VERSION ""

NS_ :

BS_:

BU_: WCM4 WCM3 WCM2 WCM VPM VLM VKM VICM VECM VDM VCU_RTOS_ETH VCU_ENTRY_ETH VCU_AGVM_ETH VCU UVM UPM TIM TEST_TOOL_1 TCP_ETH TCP TCM TCCM SRR_SRR_ETH SRR_SRR SRR_SLR_ETH SRR_SLR SRR_RR SRR_RF_ETH SRR_RF SRR_LR_CR SRR_LF_ETH SRR_LF SIB SDM SCL SBZA_R SBZA_L SBM SAM_RR SAM_RF SAM_LR SAM_LF SAM_BH SADS RadioLow_ETH RadioLow RSI_RTOS_ETH RSI RDCM PTM PLCM PFCM PDR_ETH PDR PCM PA ODS2 ODS NVM MTCM_R MTCM_L MSM_RR MSM_P MSM_LR MSM_D MSB2 MSB1 MRCM_R MRCM_L MFC LRR_RR_ETH LRR_LR_ETH LRR_CF_ETH LRR LRL_CF_ETH LIB_48V LIB1 IPC_INT IPC_GP IPC ICS_Info ICCM HVAC_FP_R HVAC_FP_F HUD_CAN HDLM FPI_RTOS_ETH FPI FOPM FCM_LC FCM EPSb EPS_1 EPSRAb EPSRAa EPS EOCM_HC_Superset EOCM_HCP2 EOCM ELM ECP_X1 ECP_S2 ECP_S ECP_MC ECP_H3 ECP_H2 ECP_H1 ECP_E ECM EBCM DMS DEFC DCM CSM_ETH CSM_AV CSM CGM_OTA_ETH CGM BSM_MH BSM_HEV BSM BCM ARS ARB APA AOS AMP ALC AHS AHL_AFL ADIMb ADIMa ACP2_MCU

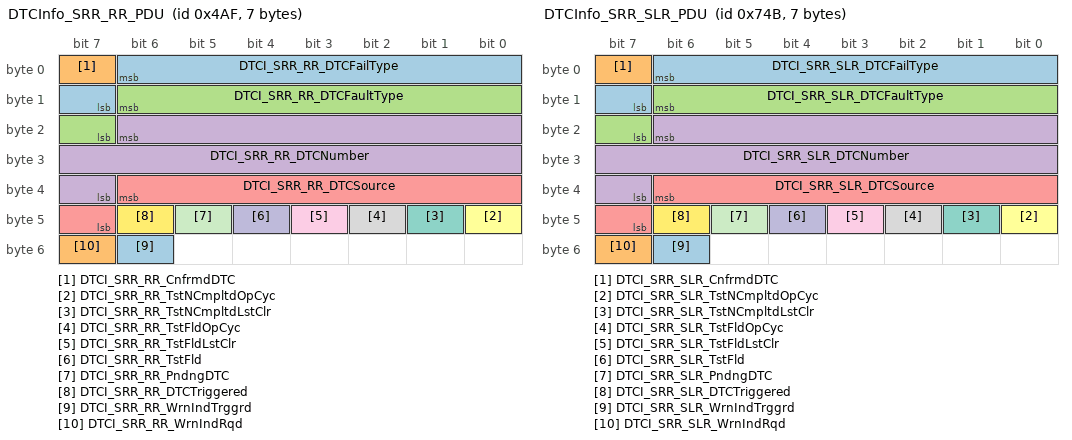
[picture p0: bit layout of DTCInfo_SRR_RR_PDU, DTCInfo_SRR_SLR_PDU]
BO_ 1199 DTCInfo_SRR_RR_PDU: 7 CGM
 SG_ DTCI_SRR_RR_DTCFailType : 6|8@0+ (1,0) [0|255] "" TCP,CSM
 SG_ DTCI_SRR_RR_CnfrmdDTC : 7|1@0+ (1,0) [0|1] "" TCP,CSM
 SG_ DTCI_SRR_RR_DTCFaultType : 14|8@0+ (1,0) [0|3] "" TCP,CSM
 SG_ DTCI_SRR_RR_DTCNumber : 22|16@0+ (1,0) [0|65535] "" TCP,CSM
 SG_ DTCI_SRR_RR_DTCSource : 38|8@0+ (1,0) [0|255] "" TCP,CSM
 SG_ DTCI_SRR_RR_TstNCmpltdOpCyc : 40|1@0+ (1,0) [0|1] "" TCP,CSM
 SG_ DTCI_SRR_RR_TstNCmpltdLstClr : 41|1@0+ (1,0) [0|1] "" TCP,CSM
 SG_ DTCI_SRR_RR_TstFldOpCyc : 42|1@0+ (1,0) [0|1] "" TCP,CSM
 SG_ DTCI_SRR_RR_TstFldLstClr : 43|1@0+ (1,0) [0|1] "" TCP,CSM
 SG_ DTCI_SRR_RR_TstFld : 44|1@0+ (1,0) [0|1] "" TCP,CSM
 SG_ DTCI_SRR_RR_PndngDTC : 45|1@0+ (1,0) [0|1] "" TCP,CSM
 SG_ DTCI_SRR_RR_DTCTriggered : 46|1@0+ (1,0) [0|1] "" TCP,CSM
 SG_ DTCI_SRR_RR_WrnIndTrggrd : 54|1@0+ (1,0) [0|1] "" TCP,CSM
 SG_ DTCI_SRR_RR_WrnIndRqd : 55|1@0+ (1,0) [0|1] "" TCP,CSM

BO_ 1867 DTCInfo_SRR_SLR_PDU: 7 CGM
 SG_ DTCI_SRR_SLR_DTCFailType : 6|8@0+ (1,0) [0|255] "" TCP,CSM
 SG_ DTCI_SRR_SLR_CnfrmdDTC : 7|1@0+ (1,0) [0|1] "" TCP,CSM
 SG_ DTCI_SRR_SLR_DTCFaultType : 14|8@0+ (1,0) [0|3] "" TCP,CSM
 SG_ DTCI_SRR_SLR_DTCNumber : 22|16@0+ (1,0) [0|65535] "" TCP,CSM
 SG_ DTCI_SRR_SLR_DTCSource : 38|8@0+ (1,0) [0|255] "" TCP,CSM
 SG_ DTCI_SRR_SLR_TstNCmpltdOpCyc : 40|1@0+ (1,0) [0|1] "" TCP,CSM
 SG_ DTCI_SRR_SLR_TstNCmpltdLstClr : 41|1@0+ (1,0) [0|1] "" TCP,CSM
 SG_ DTCI_SRR_SLR_TstFldOpCyc : 42|1@0+ (1,0) [0|1] "" TCP,CSM
 SG_ DTCI_SRR_SLR_TstFldLstClr : 43|1@0+ (1,0) [0|1] "" TCP,CSM
 SG_ DTCI_SRR_SLR_TstFld : 44|1@0+ (1,0) [0|1] "" TCP,CSM
 SG_ DTCI_SRR_SLR_PndngDTC : 45|1@0+ (1,0) [0|1] "" TCP,CSM
 SG_ DTCI_SRR_SLR_DTCTriggered : 46|1@0+ (1,0) [0|1] "" TCP,CSM
 SG_ DTCI_SRR_SLR_WrnIndTrggrd : 54|1@0+ (1,0) [0|1] "" TCP,CSM
 SG_ DTCI_SRR_SLR_WrnIndRqd : 55|1@0+ (1,0) [0|1] "" TCP,CSM

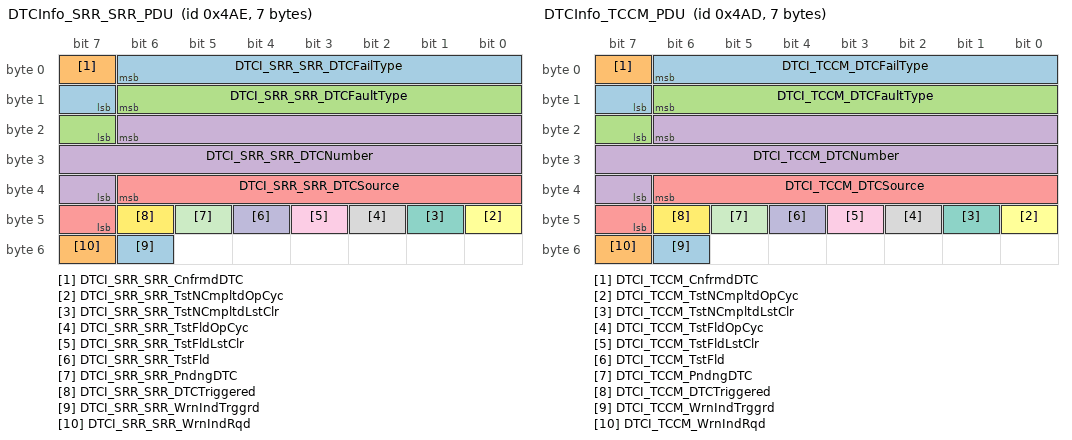
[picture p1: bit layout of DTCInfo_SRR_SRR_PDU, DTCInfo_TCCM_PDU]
BO_ 1198 DTCInfo_SRR_SRR_PDU: 7 CGM
 SG_ DTCI_SRR_SRR_DTCFailType : 6|8@0+ (1,0) [0|255] "" TCP,CSM
 SG_ DTCI_SRR_SRR_CnfrmdDTC : 7|1@0+ (1,0) [0|1] "" TCP,CSM
 SG_ DTCI_SRR_SRR_DTCFaultType : 14|8@0+ (1,0) [0|3] "" TCP,CSM
 SG_ DTCI_SRR_SRR_DTCNumber : 22|16@0+ (1,0) [0|65535] "" TCP,CSM
 SG_ DTCI_SRR_SRR_DTCSource : 38|8@0+ (1,0) [0|255] "" TCP,CSM
 SG_ DTCI_SRR_SRR_TstNCmpltdOpCyc : 40|1@0+ (1,0) [0|1] "" TCP,CSM
 SG_ DTCI_SRR_SRR_TstNCmpltdLstClr : 41|1@0+ (1,0) [0|1] "" TCP,CSM
 SG_ DTCI_SRR_SRR_TstFldOpCyc : 42|1@0+ (1,0) [0|1] "" TCP,CSM
 SG_ DTCI_SRR_SRR_TstFldLstClr : 43|1@0+ (1,0) [0|1] "" TCP,CSM
 SG_ DTCI_SRR_SRR_TstFld : 44|1@0+ (1,0) [0|1] "" TCP,CSM
 SG_ DTCI_SRR_SRR_PndngDTC : 45|1@0+ (1,0) [0|1] "" TCP,CSM
 SG_ DTCI_SRR_SRR_DTCTriggered : 46|1@0+ (1,0) [0|1] "" TCP,CSM
 SG_ DTCI_SRR_SRR_WrnIndTrggrd : 54|1@0+ (1,0) [0|1] "" TCP,CSM
 SG_ DTCI_SRR_SRR_WrnIndRqd : 55|1@0+ (1,0) [0|1] "" TCP,CSM

BO_ 1197 DTCInfo_TCCM_PDU: 7 CGM
 SG_ DTCI_TCCM_DTCFailType : 6|8@0+ (1,0) [0|255] "" TCP,CSM
 SG_ DTCI_TCCM_CnfrmdDTC : 7|1@0+ (1,0) [0|1] "" TCP,CSM
 SG_ DTCI_TCCM_DTCFaultType : 14|8@0+ (1,0) [0|3] "" TCP,CSM
 SG_ DTCI_TCCM_DTCNumber : 22|16@0+ (1,0) [0|65535] "" TCP,CSM
 SG_ DTCI_TCCM_DTCSource : 38|8@0+ (1,0) [0|255] "" TCP,CSM
 SG_ DTCI_TCCM_TstNCmpltdOpCyc : 40|1@0+ (1,0) [0|1] "" TCP,CSM
 SG_ DTCI_TCCM_TstNCmpltdLstClr : 41|1@0+ (1,0) [0|1] "" TCP,CSM
 SG_ DTCI_TCCM_TstFldOpCyc : 42|1@0+ (1,0) [0|1] "" TCP,CSM
 SG_ DTCI_TCCM_TstFldLstClr : 43|1@0+ (1,0) [0|1] "" TCP,CSM
 SG_ DTCI_TCCM_TstFld : 44|1@0+ (1,0) [0|1] "" TCP,CSM
 SG_ DTCI_TCCM_PndngDTC : 45|1@0+ (1,0) [0|1] "" TCP,CSM
 SG_ DTCI_TCCM_DTCTriggered : 46|1@0+ (1,0) [0|1] "" TCP,CSM
 SG_ DTCI_TCCM_WrnIndTrggrd : 54|1@0+ (1,0) [0|1] "" TCP,CSM
 SG_ DTCI_TCCM_WrnIndRqd : 55|1@0+ (1,0) [0|1] "" TCP,CSM

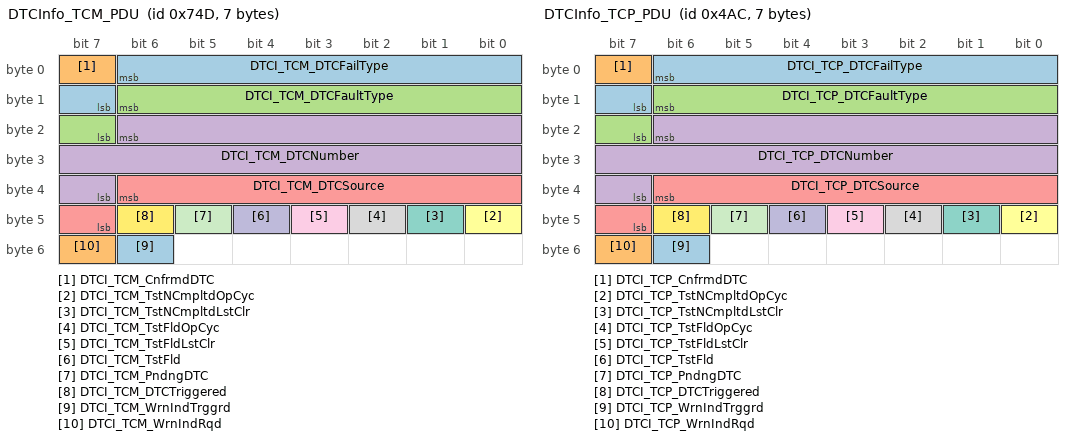
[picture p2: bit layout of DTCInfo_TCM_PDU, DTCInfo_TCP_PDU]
BO_ 1869 DTCInfo_TCM_PDU: 7 CGM
 SG_ DTCI_TCM_DTCFailType : 6|8@0+ (1,0) [0|255] "" TCP,CSM
 SG_ DTCI_TCM_CnfrmdDTC : 7|1@0+ (1,0) [0|1] "" TCP,CSM
 SG_ DTCI_TCM_DTCFaultType : 14|8@0+ (1,0) [0|3] "" TCP,CSM
 SG_ DTCI_TCM_DTCNumber : 22|16@0+ (1,0) [0|65535] "" TCP,CSM
 SG_ DTCI_TCM_DTCSource : 38|8@0+ (1,0) [0|255] "" TCP,CSM
 SG_ DTCI_TCM_TstNCmpltdOpCyc : 40|1@0+ (1,0) [0|1] "" TCP,CSM
 SG_ DTCI_TCM_TstNCmpltdLstClr : 41|1@0+ (1,0) [0|1] "" TCP,CSM
 SG_ DTCI_TCM_TstFldOpCyc : 42|1@0+ (1,0) [0|1] "" TCP,CSM
 SG_ DTCI_TCM_TstFldLstClr : 43|1@0+ (1,0) [0|1] "" TCP,CSM
 SG_ DTCI_TCM_TstFld : 44|1@0+ (1,0) [0|1] "" TCP,CSM
 SG_ DTCI_TCM_PndngDTC : 45|1@0+ (1,0) [0|1] "" TCP,CSM
 SG_ DTCI_TCM_DTCTriggered : 46|1@0+ (1,0) [0|1] "" TCP,CSM
 SG_ DTCI_TCM_WrnIndTrggrd : 54|1@0+ (1,0) [0|1] "" TCP,CSM
 SG_ DTCI_TCM_WrnIndRqd : 55|1@0+ (1,0) [0|1] "" TCP,CSM

BO_ 1196 DTCInfo_TCP_PDU: 7 TCP
 SG_ DTCI_TCP_DTCFailType : 6|8@0+ (1,0) [0|255] "" CGM,TCP,CSM
 SG_ DTCI_TCP_CnfrmdDTC : 7|1@0+ (1,0) [0|1] "" CGM,TCP,CSM
 SG_ DTCI_TCP_DTCFaultType : 14|8@0+ (1,0) [0|3] "" CGM,TCP,CSM
 SG_ DTCI_TCP_DTCNumber : 22|16@0+ (1,0) [0|65535] "" CGM,TCP,CSM
 SG_ DTCI_TCP_DTCSource : 38|8@0+ (1,0) [0|255] "" CGM,TCP,CSM
 SG_ DTCI_TCP_TstNCmpltdOpCyc : 40|1@0+ (1,0) [0|1] "" CGM,TCP,CSM
 SG_ DTCI_TCP_TstNCmpltdLstClr : 41|1@0+ (1,0) [0|1] "" CGM,TCP,CSM
 SG_ DTCI_TCP_TstFldOpCyc : 42|1@0+ (1,0) [0|1] "" CGM,TCP,CSM
 SG_ DTCI_TCP_TstFldLstClr : 43|1@0+ (1,0) [0|1] "" CGM,TCP,CSM
 SG_ DTCI_TCP_TstFld : 44|1@0+ (1,0) [0|1] "" CGM,TCP,CSM
 SG_ DTCI_TCP_PndngDTC : 45|1@0+ (1,0) [0|1] "" CGM,TCP,CSM
 SG_ DTCI_TCP_DTCTriggered : 46|1@0+ (1,0) [0|1] "" CGM,TCP,CSM
 SG_ DTCI_TCP_WrnIndTrggrd : 54|1@0+ (1,0) [0|1] "" CGM,TCP,CSM
 SG_ DTCI_TCP_WrnIndRqd : 55|1@0+ (1,0) [0|1] "" CGM,TCP,CSM

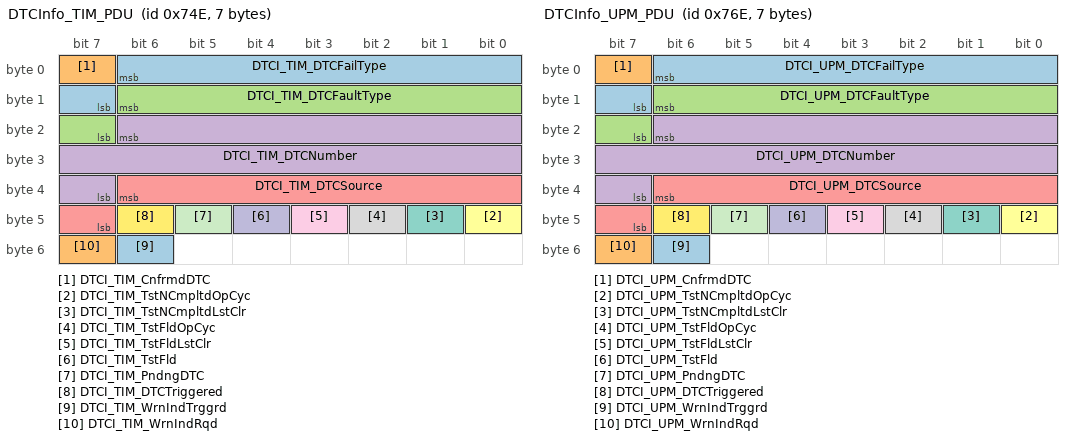
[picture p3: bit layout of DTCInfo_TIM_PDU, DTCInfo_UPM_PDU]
BO_ 1870 DTCInfo_TIM_PDU: 7 CGM
 SG_ DTCI_TIM_DTCFailType : 6|8@0+ (1,0) [0|255] "" TCP,CSM
 SG_ DTCI_TIM_CnfrmdDTC : 7|1@0+ (1,0) [0|1] "" TCP,CSM
 SG_ DTCI_TIM_DTCFaultType : 14|8@0+ (1,0) [0|3] "" TCP,CSM
 SG_ DTCI_TIM_DTCNumber : 22|16@0+ (1,0) [0|65535] "" TCP,CSM
 SG_ DTCI_TIM_DTCSource : 38|8@0+ (1,0) [0|255] "" TCP,CSM
 SG_ DTCI_TIM_TstNCmpltdOpCyc : 40|1@0+ (1,0) [0|1] "" TCP,CSM
 SG_ DTCI_TIM_TstNCmpltdLstClr : 41|1@0+ (1,0) [0|1] "" TCP,CSM
 SG_ DTCI_TIM_TstFldOpCyc : 42|1@0+ (1,0) [0|1] "" TCP,CSM
 SG_ DTCI_TIM_TstFldLstClr : 43|1@0+ (1,0) [0|1] "" TCP,CSM
 SG_ DTCI_TIM_TstFld : 44|1@0+ (1,0) [0|1] "" TCP,CSM
 SG_ DTCI_TIM_PndngDTC : 45|1@0+ (1,0) [0|1] "" TCP,CSM
 SG_ DTCI_TIM_DTCTriggered : 46|1@0+ (1,0) [0|1] "" TCP,CSM
 SG_ DTCI_TIM_WrnIndTrggrd : 54|1@0+ (1,0) [0|1] "" TCP,CSM
 SG_ DTCI_TIM_WrnIndRqd : 55|1@0+ (1,0) [0|1] "" TCP,CSM

BO_ 1902 DTCInfo_UPM_PDU: 7 CGM
 SG_ DTCI_UPM_DTCFailType : 6|8@0+ (1,0) [0|255] "" TCP
 SG_ DTCI_UPM_CnfrmdDTC : 7|1@0+ (1,0) [0|1] "" TCP
 SG_ DTCI_UPM_DTCFaultType : 14|8@0+ (1,0) [0|3] "" TCP
 SG_ DTCI_UPM_DTCNumber : 22|16@0+ (1,0) [0|65535] "" TCP
 SG_ DTCI_UPM_DTCSource : 38|8@0+ (1,0) [0|255] "" TCP
 SG_ DTCI_UPM_TstNCmpltdOpCyc : 40|1@0+ (1,0) [0|1] "" TCP
 SG_ DTCI_UPM_TstNCmpltdLstClr : 41|1@0+ (1,0) [0|1] "" TCP
 SG_ DTCI_UPM_TstFldOpCyc : 42|1@0+ (1,0) [0|1] "" TCP
 SG_ DTCI_UPM_TstFldLstClr : 43|1@0+ (1,0) [0|1] "" TCP
 SG_ DTCI_UPM_TstFld : 44|1@0+ (1,0) [0|1] "" TCP
 SG_ DTCI_UPM_PndngDTC : 45|1@0+ (1,0) [0|1] "" TCP
 SG_ DTCI_UPM_DTCTriggered : 46|1@0+ (1,0) [0|1] "" TCP
 SG_ DTCI_UPM_WrnIndTrggrd : 54|1@0+ (1,0) [0|1] "" TCP
 SG_ DTCI_UPM_WrnIndRqd : 55|1@0+ (1,0) [0|1] "" TCP

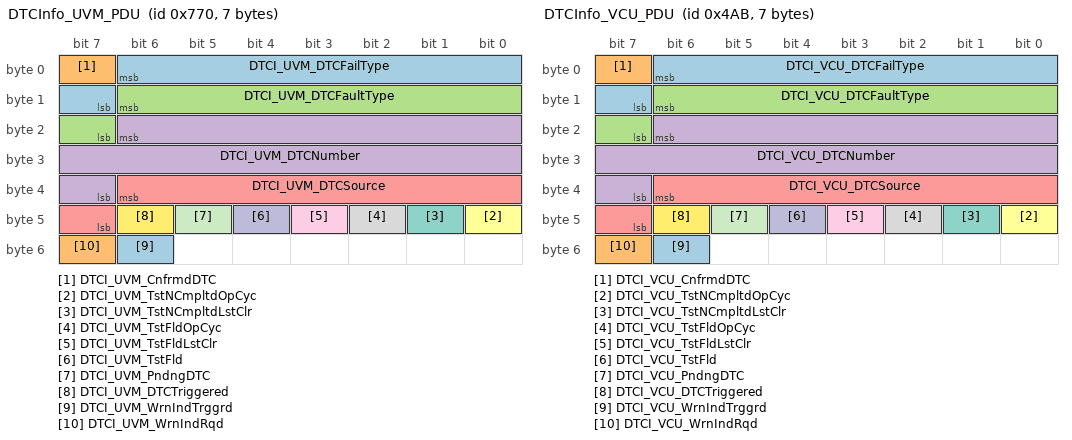
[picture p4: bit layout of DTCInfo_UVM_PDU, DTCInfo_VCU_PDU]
BO_ 1904 DTCInfo_UVM_PDU: 7 CGM
 SG_ DTCI_UVM_DTCFailType : 6|8@0+ (1,0) [0|255] "" TCP
 SG_ DTCI_UVM_CnfrmdDTC : 7|1@0+ (1,0) [0|1] "" TCP
 SG_ DTCI_UVM_DTCFaultType : 14|8@0+ (1,0) [0|3] "" TCP
 SG_ DTCI_UVM_DTCNumber : 22|16@0+ (1,0) [0|65535] "" TCP
 SG_ DTCI_UVM_DTCSource : 38|8@0+ (1,0) [0|255] "" TCP
 SG_ DTCI_UVM_TstNCmpltdOpCyc : 40|1@0+ (1,0) [0|1] "" TCP
 SG_ DTCI_UVM_TstNCmpltdLstClr : 41|1@0+ (1,0) [0|1] "" TCP
 SG_ DTCI_UVM_TstFldOpCyc : 42|1@0+ (1,0) [0|1] "" TCP
 SG_ DTCI_UVM_TstFldLstClr : 43|1@0+ (1,0) [0|1] "" TCP
 SG_ DTCI_UVM_TstFld : 44|1@0+ (1,0) [0|1] "" TCP
 SG_ DTCI_UVM_PndngDTC : 45|1@0+ (1,0) [0|1] "" TCP
 SG_ DTCI_UVM_DTCTriggered : 46|1@0+ (1,0) [0|1] "" TCP
 SG_ DTCI_UVM_WrnIndTrggrd : 54|1@0+ (1,0) [0|1] "" TCP
 SG_ DTCI_UVM_WrnIndRqd : 55|1@0+ (1,0) [0|1] "" TCP

BO_ 1195 DTCInfo_VCU_PDU: 7 VCU
 SG_ DTCI_VCU_DTCFailType : 6|8@0+ (1,0) [0|255] "" TCP
 SG_ DTCI_VCU_CnfrmdDTC : 7|1@0+ (1,0) [0|1] "" TCP
 SG_ DTCI_VCU_DTCFaultType : 14|8@0+ (1,0) [0|3] "" TCP
 SG_ DTCI_VCU_DTCNumber : 22|16@0+ (1,0) [0|65535] "" TCP
 SG_ DTCI_VCU_DTCSource : 38|8@0+ (1,0) [0|255] "" CGM,TCP
 SG_ DTCI_VCU_TstNCmpltdOpCyc : 40|1@0+ (1,0) [0|1] "" TCP
 SG_ DTCI_VCU_TstNCmpltdLstClr : 41|1@0+ (1,0) [0|1] "" TCP
 SG_ DTCI_VCU_TstFldOpCyc : 42|1@0+ (1,0) [0|1] "" TCP
 SG_ DTCI_VCU_TstFldLstClr : 43|1@0+ (1,0) [0|1] "" TCP
 SG_ DTCI_VCU_TstFld : 44|1@0+ (1,0) [0|1] "" TCP
 SG_ DTCI_VCU_PndngDTC : 45|1@0+ (1,0) [0|1] "" TCP
 SG_ DTCI_VCU_DTCTriggered : 46|1@0+ (1,0) [0|1] "" TCP
 SG_ DTCI_VCU_WrnIndTrggrd : 54|1@0+ (1,0) [0|1] "" TCP
 SG_ DTCI_VCU_WrnIndRqd : 55|1@0+ (1,0) [0|1] "" TCP

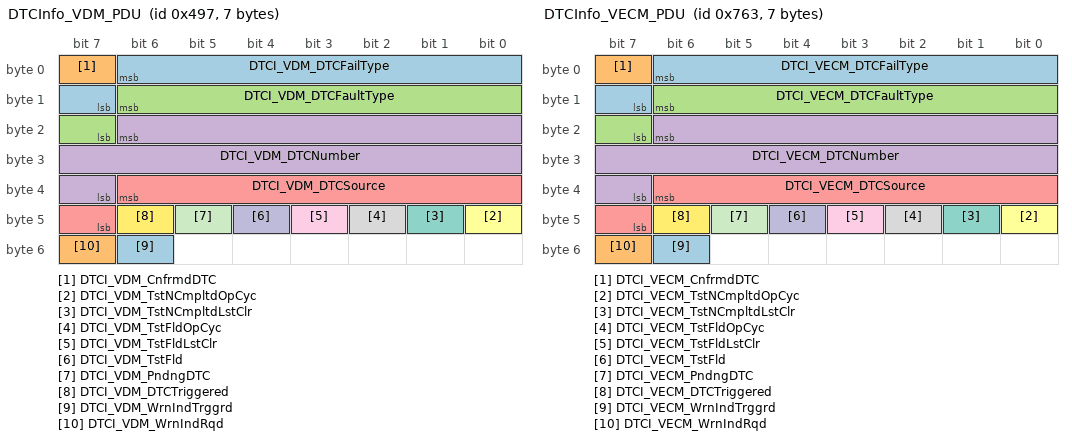
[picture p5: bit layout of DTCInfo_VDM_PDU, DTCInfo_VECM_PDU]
BO_ 1175 DTCInfo_VDM_PDU: 7 CGM
 SG_ DTCI_VDM_DTCFailType : 6|8@0+ (1,0) [0|255] "" TCP
 SG_ DTCI_VDM_CnfrmdDTC : 7|1@0+ (1,0) [0|1] "" TCP
 SG_ DTCI_VDM_DTCFaultType : 14|8@0+ (1,0) [0|3] "" TCP
 SG_ DTCI_VDM_DTCNumber : 22|16@0+ (1,0) [0|65535] "" TCP
 SG_ DTCI_VDM_DTCSource : 38|8@0+ (1,0) [0|255] "" TCP
 SG_ DTCI_VDM_TstNCmpltdOpCyc : 40|1@0+ (1,0) [0|1] "" TCP
 SG_ DTCI_VDM_TstNCmpltdLstClr : 41|1@0+ (1,0) [0|1] "" TCP
 SG_ DTCI_VDM_TstFldOpCyc : 42|1@0+ (1,0) [0|1] "" TCP
 SG_ DTCI_VDM_TstFldLstClr : 43|1@0+ (1,0) [0|1] "" TCP
 SG_ DTCI_VDM_TstFld : 44|1@0+ (1,0) [0|1] "" TCP
 SG_ DTCI_VDM_PndngDTC : 45|1@0+ (1,0) [0|1] "" TCP
 SG_ DTCI_VDM_DTCTriggered : 46|1@0+ (1,0) [0|1] "" TCP
 SG_ DTCI_VDM_WrnIndTrggrd : 54|1@0+ (1,0) [0|1] "" TCP
 SG_ DTCI_VDM_WrnIndRqd : 55|1@0+ (1,0) [0|1] "" TCP

BO_ 1891 DTCInfo_VECM_PDU: 7 CGM
 SG_ DTCI_VECM_DTCFailType : 6|8@0+ (1,0) [0|255] "" TCP
 SG_ DTCI_VECM_CnfrmdDTC : 7|1@0+ (1,0) [0|1] "" TCP
 SG_ DTCI_VECM_DTCFaultType : 14|8@0+ (1,0) [0|3] "" TCP
 SG_ DTCI_VECM_DTCNumber : 22|16@0+ (1,0) [0|65535] "" TCP
 SG_ DTCI_VECM_DTCSource : 38|8@0+ (1,0) [0|255] "" TCP
 SG_ DTCI_VECM_TstNCmpltdOpCyc : 40|1@0+ (1,0) [0|1] "" TCP
 SG_ DTCI_VECM_TstNCmpltdLstClr : 41|1@0+ (1,0) [0|1] "" TCP
 SG_ DTCI_VECM_TstFldOpCyc : 42|1@0+ (1,0) [0|1] "" TCP
 SG_ DTCI_VECM_TstFldLstClr : 43|1@0+ (1,0) [0|1] "" TCP
 SG_ DTCI_VECM_TstFld : 44|1@0+ (1,0) [0|1] "" TCP
 SG_ DTCI_VECM_PndngDTC : 45|1@0+ (1,0) [0|1] "" TCP
 SG_ DTCI_VECM_DTCTriggered : 46|1@0+ (1,0) [0|1] "" TCP
 SG_ DTCI_VECM_WrnIndTrggrd : 54|1@0+ (1,0) [0|1] "" TCP
 SG_ DTCI_VECM_WrnIndRqd : 55|1@0+ (1,0) [0|1] "" TCP

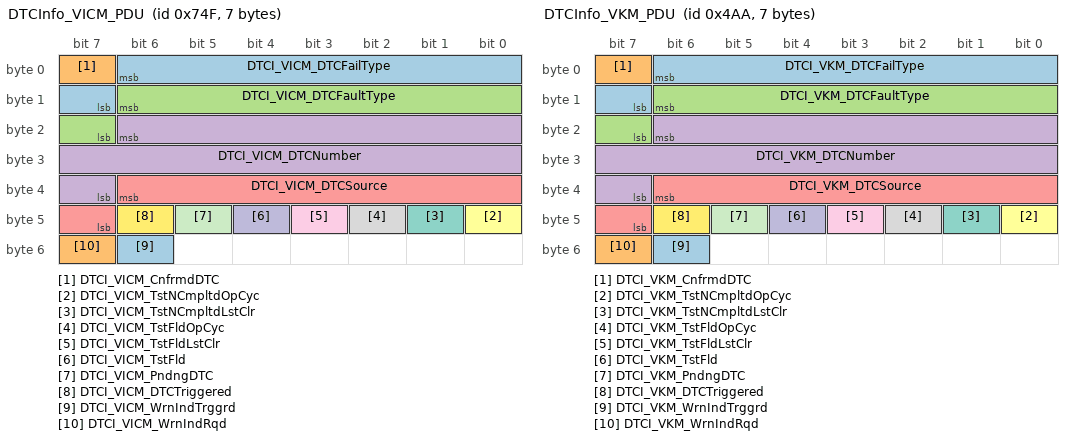
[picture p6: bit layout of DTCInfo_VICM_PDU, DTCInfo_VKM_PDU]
BO_ 1871 DTCInfo_VICM_PDU: 7 CGM
 SG_ DTCI_VICM_DTCFailType : 6|8@0+ (1,0) [0|255] "" TCP,CSM
 SG_ DTCI_VICM_CnfrmdDTC : 7|1@0+ (1,0) [0|1] "" TCP,CSM
 SG_ DTCI_VICM_DTCFaultType : 14|8@0+ (1,0) [0|3] "" TCP,CSM
 SG_ DTCI_VICM_DTCNumber : 22|16@0+ (1,0) [0|65535] "" TCP,CSM
 SG_ DTCI_VICM_DTCSource : 38|8@0+ (1,0) [0|255] "" TCP,CSM
 SG_ DTCI_VICM_TstNCmpltdOpCyc : 40|1@0+ (1,0) [0|1] "" TCP,CSM
 SG_ DTCI_VICM_TstNCmpltdLstClr : 41|1@0+ (1,0) [0|1] "" TCP,CSM
 SG_ DTCI_VICM_TstFldOpCyc : 42|1@0+ (1,0) [0|1] "" TCP,CSM
 SG_ DTCI_VICM_TstFldLstClr : 43|1@0+ (1,0) [0|1] "" TCP,CSM
 SG_ DTCI_VICM_TstFld : 44|1@0+ (1,0) [0|1] "" TCP,CSM
 SG_ DTCI_VICM_PndngDTC : 45|1@0+ (1,0) [0|1] "" TCP,CSM
 SG_ DTCI_VICM_DTCTriggered : 46|1@0+ (1,0) [0|1] "" TCP,CSM
 SG_ DTCI_VICM_WrnIndTrggrd : 54|1@0+ (1,0) [0|1] "" TCP,CSM
 SG_ DTCI_VICM_WrnIndRqd : 55|1@0+ (1,0) [0|1] "" TCP,CSM

BO_ 1194 DTCInfo_VKM_PDU: 7 VKM
 SG_ DTCI_VKM_DTCFailType : 6|8@0+ (1,0) [0|255] "" TCP,CSM
 SG_ DTCI_VKM_CnfrmdDTC : 7|1@0+ (1,0) [0|1] "" TCP,CSM
 SG_ DTCI_VKM_DTCFaultType : 14|8@0+ (1,0) [0|3] "" TCP,CSM
 SG_ DTCI_VKM_DTCNumber : 22|16@0+ (1,0) [0|65535] "" TCP,CSM
 SG_ DTCI_VKM_DTCSource : 38|8@0+ (1,0) [0|255] "" CGM,TCP,CSM
 SG_ DTCI_VKM_TstNCmpltdOpCyc : 40|1@0+ (1,0) [0|1] "" TCP,CSM
 SG_ DTCI_VKM_TstNCmpltdLstClr : 41|1@0+ (1,0) [0|1] "" TCP,CSM
 SG_ DTCI_VKM_TstFldOpCyc : 42|1@0+ (1,0) [0|1] "" TCP,CSM
 SG_ DTCI_VKM_TstFldLstClr : 43|1@0+ (1,0) [0|1] "" TCP,CSM
 SG_ DTCI_VKM_TstFld : 44|1@0+ (1,0) [0|1] "" TCP,CSM
 SG_ DTCI_VKM_PndngDTC : 45|1@0+ (1,0) [0|1] "" TCP,CSM
 SG_ DTCI_VKM_DTCTriggered : 46|1@0+ (1,0) [0|1] "" TCP,CSM
 SG_ DTCI_VKM_WrnIndTrggrd : 54|1@0+ (1,0) [0|1] "" TCP,CSM
 SG_ DTCI_VKM_WrnIndRqd : 55|1@0+ (1,0) [0|1] "" TCP,CSM

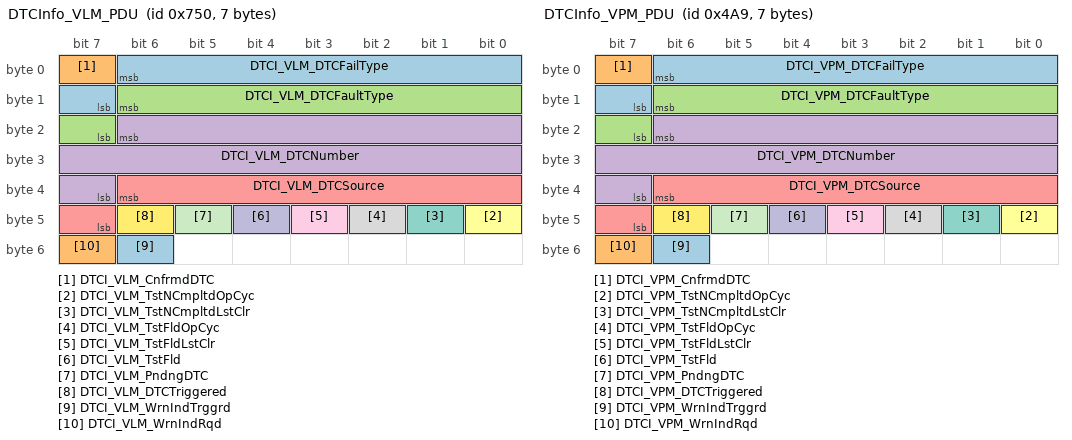
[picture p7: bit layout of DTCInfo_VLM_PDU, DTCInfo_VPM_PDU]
BO_ 1872 DTCInfo_VLM_PDU: 7 CGM
 SG_ DTCI_VLM_DTCFailType : 6|8@0+ (1,0) [0|255] "" TCP,CSM
 SG_ DTCI_VLM_CnfrmdDTC : 7|1@0+ (1,0) [0|1] "" TCP,CSM
 SG_ DTCI_VLM_DTCFaultType : 14|8@0+ (1,0) [0|3] "" TCP,CSM
 SG_ DTCI_VLM_DTCNumber : 22|16@0+ (1,0) [0|65535] "" TCP,CSM
 SG_ DTCI_VLM_DTCSource : 38|8@0+ (1,0) [0|255] "" TCP,CSM
 SG_ DTCI_VLM_TstNCmpltdOpCyc : 40|1@0+ (1,0) [0|1] "" TCP,CSM
 SG_ DTCI_VLM_TstNCmpltdLstClr : 41|1@0+ (1,0) [0|1] "" TCP,CSM
 SG_ DTCI_VLM_TstFldOpCyc : 42|1@0+ (1,0) [0|1] "" TCP,CSM
 SG_ DTCI_VLM_TstFldLstClr : 43|1@0+ (1,0) [0|1] "" TCP,CSM
 SG_ DTCI_VLM_TstFld : 44|1@0+ (1,0) [0|1] "" TCP,CSM
 SG_ DTCI_VLM_PndngDTC : 45|1@0+ (1,0) [0|1] "" TCP,CSM
 SG_ DTCI_VLM_DTCTriggered : 46|1@0+ (1,0) [0|1] "" TCP,CSM
 SG_ DTCI_VLM_WrnIndTrggrd : 54|1@0+ (1,0) [0|1] "" TCP,CSM
 SG_ DTCI_VLM_WrnIndRqd : 55|1@0+ (1,0) [0|1] "" TCP,CSM

BO_ 1193 DTCInfo_VPM_PDU: 7 CGM
 SG_ DTCI_VPM_DTCFailType : 6|8@0+ (1,0) [0|255] "" TCP,CSM
 SG_ DTCI_VPM_CnfrmdDTC : 7|1@0+ (1,0) [0|1] "" TCP,CSM
 SG_ DTCI_VPM_DTCFaultType : 14|8@0+ (1,0) [0|3] "" TCP,CSM
 SG_ DTCI_VPM_DTCNumber : 22|16@0+ (1,0) [0|65535] "" TCP,CSM
 SG_ DTCI_VPM_DTCSource : 38|8@0+ (1,0) [0|255] "" TCP,CSM
 SG_ DTCI_VPM_TstNCmpltdOpCyc : 40|1@0+ (1,0) [0|1] "" TCP,CSM
 SG_ DTCI_VPM_TstNCmpltdLstClr : 41|1@0+ (1,0) [0|1] "" TCP,CSM
 SG_ DTCI_VPM_TstFldOpCyc : 42|1@0+ (1,0) [0|1] "" TCP,CSM
 SG_ DTCI_VPM_TstFldLstClr : 43|1@0+ (1,0) [0|1] "" TCP,CSM
 SG_ DTCI_VPM_TstFld : 44|1@0+ (1,0) [0|1] "" TCP,CSM
 SG_ DTCI_VPM_PndngDTC : 45|1@0+ (1,0) [0|1] "" TCP,CSM
 SG_ DTCI_VPM_DTCTriggered : 46|1@0+ (1,0) [0|1] "" TCP,CSM
 SG_ DTCI_VPM_WrnIndTrggrd : 54|1@0+ (1,0) [0|1] "" TCP,CSM
 SG_ DTCI_VPM_WrnIndRqd : 55|1@0+ (1,0) [0|1] "" TCP,CSM

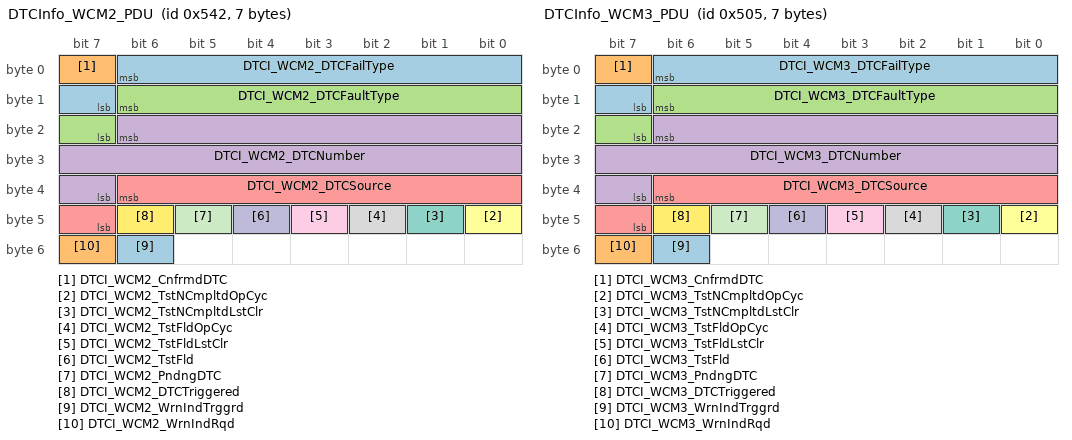
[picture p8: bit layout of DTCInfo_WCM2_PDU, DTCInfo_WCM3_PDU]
BO_ 1346 DTCInfo_WCM2_PDU: 7 WCM2
 SG_ DTCI_WCM2_DTCFailType : 6|8@0+ (1,0) [0|255] "" TCP
 SG_ DTCI_WCM2_CnfrmdDTC : 7|1@0+ (1,0) [0|1] "" TCP
 SG_ DTCI_WCM2_DTCFaultType : 14|8@0+ (1,0) [0|3] "" TCP
 SG_ DTCI_WCM2_DTCNumber : 22|16@0+ (1,0) [0|65535] "" TCP
 SG_ DTCI_WCM2_DTCSource : 38|8@0+ (1,0) [0|255] "" CGM,TCP
 SG_ DTCI_WCM2_TstNCmpltdOpCyc : 40|1@0+ (1,0) [0|1] "" TCP
 SG_ DTCI_WCM2_TstNCmpltdLstClr : 41|1@0+ (1,0) [0|1] "" TCP
 SG_ DTCI_WCM2_TstFldOpCyc : 42|1@0+ (1,0) [0|1] "" TCP
 SG_ DTCI_WCM2_TstFldLstClr : 43|1@0+ (1,0) [0|1] "" TCP
 SG_ DTCI_WCM2_TstFld : 44|1@0+ (1,0) [0|1] "" TCP
 SG_ DTCI_WCM2_PndngDTC : 45|1@0+ (1,0) [0|1] "" TCP
 SG_ DTCI_WCM2_DTCTriggered : 46|1@0+ (1,0) [0|1] "" TCP
 SG_ DTCI_WCM2_WrnIndTrggrd : 54|1@0+ (1,0) [0|1] "" TCP
 SG_ DTCI_WCM2_WrnIndRqd : 55|1@0+ (1,0) [0|1] "" TCP

BO_ 1285 DTCInfo_WCM3_PDU: 7 WCM3
 SG_ DTCI_WCM3_DTCFailType : 6|8@0+ (1,0) [0|255] "" TCP
 SG_ DTCI_WCM3_CnfrmdDTC : 7|1@0+ (1,0) [0|1] "" TCP
 SG_ DTCI_WCM3_DTCFaultType : 14|8@0+ (1,0) [0|3] "" TCP
 SG_ DTCI_WCM3_DTCNumber : 22|16@0+ (1,0) [0|65535] "" TCP
 SG_ DTCI_WCM3_DTCSource : 38|8@0+ (1,0) [0|255] "" CGM,TCP
 SG_ DTCI_WCM3_TstNCmpltdOpCyc : 40|1@0+ (1,0) [0|1] "" TCP
 SG_ DTCI_WCM3_TstNCmpltdLstClr : 41|1@0+ (1,0) [0|1] "" TCP
 SG_ DTCI_WCM3_TstFldOpCyc : 42|1@0+ (1,0) [0|1] "" TCP
 SG_ DTCI_WCM3_TstFldLstClr : 43|1@0+ (1,0) [0|1] "" TCP
 SG_ DTCI_WCM3_TstFld : 44|1@0+ (1,0) [0|1] "" TCP
 SG_ DTCI_WCM3_PndngDTC : 45|1@0+ (1,0) [0|1] "" TCP
 SG_ DTCI_WCM3_DTCTriggered : 46|1@0+ (1,0) [0|1] "" TCP
 SG_ DTCI_WCM3_WrnIndTrggrd : 54|1@0+ (1,0) [0|1] "" TCP
 SG_ DTCI_WCM3_WrnIndRqd : 55|1@0+ (1,0) [0|1] "" TCP

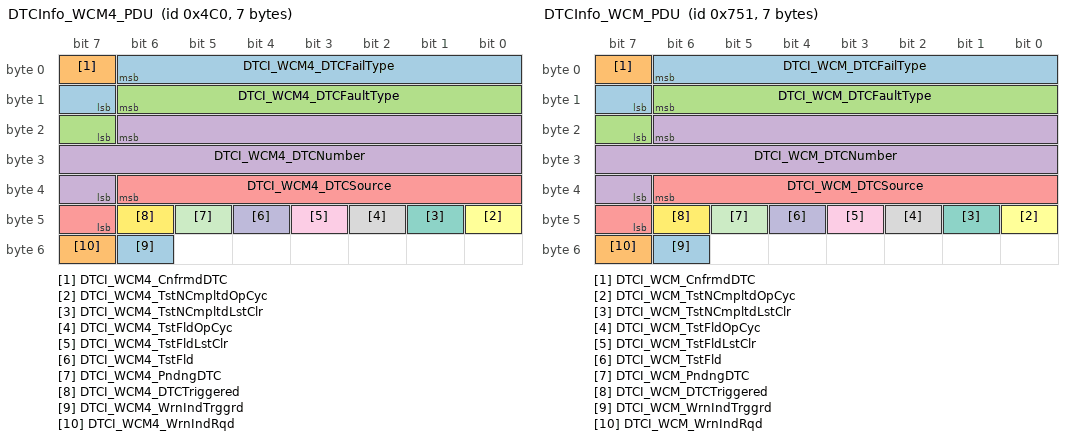
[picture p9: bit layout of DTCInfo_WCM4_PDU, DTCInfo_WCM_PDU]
BO_ 1216 DTCInfo_WCM4_PDU: 7 WCM4
 SG_ DTCI_WCM4_DTCFailType : 6|8@0+ (1,0) [0|255] "" TCP
 SG_ DTCI_WCM4_CnfrmdDTC : 7|1@0+ (1,0) [0|1] "" TCP
 SG_ DTCI_WCM4_DTCFaultType : 14|8@0+ (1,0) [0|3] "" TCP
 SG_ DTCI_WCM4_DTCNumber : 22|16@0+ (1,0) [0|65535] "" TCP
 SG_ DTCI_WCM4_DTCSource : 38|8@0+ (1,0) [0|255] "" CGM,TCP
 SG_ DTCI_WCM4_TstNCmpltdOpCyc : 40|1@0+ (1,0) [0|1] "" TCP
 SG_ DTCI_WCM4_TstNCmpltdLstClr : 41|1@0+ (1,0) [0|1] "" TCP
 SG_ DTCI_WCM4_TstFldOpCyc : 42|1@0+ (1,0) [0|1] "" TCP
 SG_ DTCI_WCM4_TstFldLstClr : 43|1@0+ (1,0) [0|1] "" TCP
 SG_ DTCI_WCM4_TstFld : 44|1@0+ (1,0) [0|1] "" TCP
 SG_ DTCI_WCM4_PndngDTC : 45|1@0+ (1,0) [0|1] "" TCP
 SG_ DTCI_WCM4_DTCTriggered : 46|1@0+ (1,0) [0|1] "" TCP
 SG_ DTCI_WCM4_WrnIndTrggrd : 54|1@0+ (1,0) [0|1] "" TCP
 SG_ DTCI_WCM4_WrnIndRqd : 55|1@0+ (1,0) [0|1] "" TCP

BO_ 1873 DTCInfo_WCM_PDU: 7 WCM
 SG_ DTCI_WCM_DTCFailType : 6|8@0+ (1,0) [0|255] "" TCP,CSM
 SG_ DTCI_WCM_CnfrmdDTC : 7|1@0+ (1,0) [0|1] "" TCP,CSM
 SG_ DTCI_WCM_DTCFaultType : 14|8@0+ (1,0) [0|3] "" TCP,CSM
 SG_ DTCI_WCM_DTCNumber : 22|16@0+ (1,0) [0|65535] "" TCP,CSM
 SG_ DTCI_WCM_DTCSource : 38|8@0+ (1,0) [0|255] "" CGM,TCP,CSM
 SG_ DTCI_WCM_TstNCmpltdOpCyc : 40|1@0+ (1,0) [0|1] "" TCP,CSM
 SG_ DTCI_WCM_TstNCmpltdLstClr : 41|1@0+ (1,0) [0|1] "" TCP,CSM
 SG_ DTCI_WCM_TstFldOpCyc : 42|1@0+ (1,0) [0|1] "" TCP,CSM
 SG_ DTCI_WCM_TstFldLstClr : 43|1@0+ (1,0) [0|1] "" TCP,CSM
 SG_ DTCI_WCM_TstFld : 44|1@0+ (1,0) [0|1] "" TCP,CSM
 SG_ DTCI_WCM_PndngDTC : 45|1@0+ (1,0) [0|1] "" TCP,CSM
 SG_ DTCI_WCM_DTCTriggered : 46|1@0+ (1,0) [0|1] "" TCP,CSM
 SG_ DTCI_WCM_WrnIndTrggrd : 54|1@0+ (1,0) [0|1] "" TCP,CSM
 SG_ DTCI_WCM_WrnIndRqd : 55|1@0+ (1,0) [0|1] "" TCP,CSM

BO_ 1390 DrvlnDispInfo_PCSM_PDU: 8 CGM
 SG_ DrvlnDispInfo_PCSM : 0|64@1+ (1,0) [0|1.84467e+019] "" IPC,IPC_INT,VCU

BO_ 872 DrvlnDispInfo_Prtctd_PDU: 8 CGM
 SG_ DDIP_MAC : 7|27@0+ (1,0) [0|1.34218e+008] "" IPC,IPC_INT,VCU
 SG_ DDIP_FCnt : 28|5@0+ (1,0) [0|31] "" IPC,IPC_INT,VCU
 SG_ DDIP_ARC : 33|2@0+ (1,0) [0|3] "" IPC,IPC_INT,VCU
 SG_ DDIP_SecAxl4WDAWDTmpInhbIOAuth : 34|1@0+ (1,0) [0|1] "" TCP,CSM,CSM_AV,IPC,IPC_INT,VCU
 SG_ DDIP_SecAxl4WDAWDNonEmMlfIOAuth : 35|1@0+ (1,0) [0|1] "" CSM,CSM_AV,IPC,IPC_INT,VCU
 SG_ DDIP_4AndAllWhlDrvIndReqAuth : 39|4@0+ (1,0) [0|15] "" CSM,CSM_AV,IPC,IPC_INT,VCU
 SG_ DDIP_Filler : 47|24@0+ (1,0) [0|1.67772e+007] "" IPC,IPC_INT,VCU

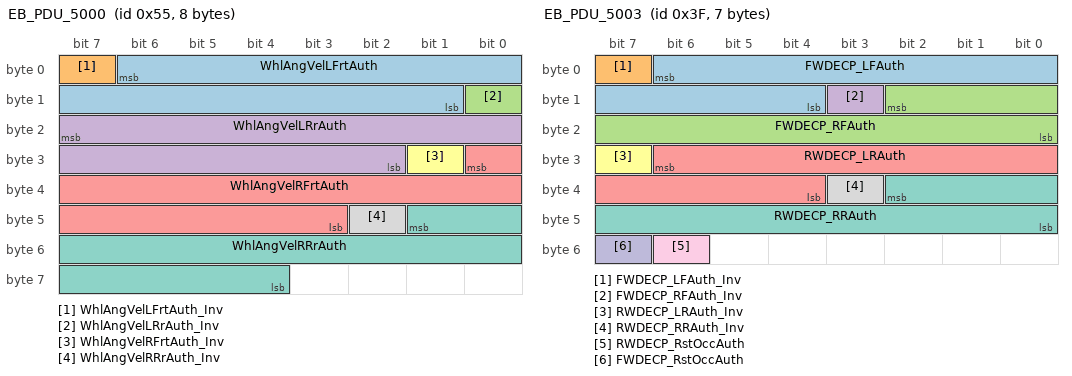
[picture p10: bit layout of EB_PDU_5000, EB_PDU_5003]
BO_ 85 EB_PDU_5000: 8 CGM
 SG_ WhlAngVelLFrtAuth : 6|14@0+ (0.004,0) [0|65.532] "Revolutions Per Second" PDR,TCP,CSM,CSM_AV,VCU
 SG_ WhlAngVelLFrtAuth_Inv : 7|1@0+ (1,0) [0|1] "" PDR,TCP,CSM,CSM_AV,VCU
 SG_ WhlAngVelLRrAuth_Inv : 8|1@0+ (1,0) [0|1] "" PDR,TCP,CSM,CSM_AV,VCU
 SG_ WhlAngVelLRrAuth : 23|14@0+ (0.004,0) [0|65.532] "Revolutions Per Second" PDR,TCP,CSM,CSM_AV,VCU
 SG_ WhlAngVelRFrtAuth : 24|14@0+ (0.004,0) [0|65.532] "Revolutions Per Second" PDR,TCP,CSM,CSM_AV,VCU
 SG_ WhlAngVelRFrtAuth_Inv : 25|1@0+ (1,0) [0|1] "" PDR,TCP,CSM,CSM_AV,VCU
 SG_ WhlAngVelRRrAuth : 41|14@0+ (0.004,0) [0|65.532] "Revolutions Per Second" PDR,TCP,CSM,CSM_AV,VCU
 SG_ WhlAngVelRRrAuth_Inv : 42|1@0+ (1,0) [0|1] "" PDR,TCP,CSM,CSM_AV,VCU

BO_ 69 EB_PDU_5001: 6 CGM
 SG_ CSBTP_ChsSysTtBrkAxTqVlAuth : 7|14@0+ (2,0) [0|32766] "" TCP
 SG_ CSBTP_DrvrIntndTtBrkTqAuth : 9|14@0+ (2,0) [0|32766] "Nm" TCP
 SG_ CBIP_BrkPedPstnEmsRltdAuth : 26|8@0+ (0.392157,0) [0|100] "%" TCP
 SG_ CBIP_BrkPedPstnEmsRltdAuth_Inv : 27|1@0+ (1,0) [0|1] "" TCP
 SG_ CBIP_ACCBrkgStsAuth : 32|2@0+ (1,0) [0|2] "" TCP
 SG_ BSIRP_HillDscntCtlStsAuth : 34|2@0+ (1,0) [0|2] "" VCU

BO_ 730 EB_PDU_5002: 1 CGM
 SG_ LDGI1_LgslDiagStdCondsMet : 7|1@0+ (1,0) [0|1] "" TCP

BO_ 63 EB_PDU_5003: 7 CGM
 SG_ FWDECP_LFAuth : 6|11@0+ (1,0) [0|2047] "" PDR,TCP,CSM,CSM_AV,VCU
 SG_ FWDECP_LFAuth_Inv : 7|1@0+ (1,0) [0|1] "" PDR,TCP,CSM,VCU
 SG_ FWDECP_RFAuth : 10|11@0+ (1,0) [0|2047] "" PDR,TCP,CSM,CSM_AV,VCU
 SG_ FWDECP_RFAuth_Inv : 11|1@0+ (1,0) [0|1] "" PDR,TCP,CSM,VCU
 SG_ RWDECP_LRAuth : 30|11@0+ (1,0) [0|2047] "" PDR,TCP,CSM,CSM_AV,VCU
 SG_ RWDECP_LRAuth_Inv : 31|1@0+ (1,0) [0|1] "" PDR,TCP,CSM,VCU
 SG_ RWDECP_RRAuth : 34|11@0+ (1,0) [0|2047] "" PDR,TCP,CSM,CSM_AV,VCU
 SG_ RWDECP_RRAuth_Inv : 35|1@0+ (1,0) [0|1] "" PDR,TCP,CSM,VCU
 SG_ RWDECP_RstOccAuth : 54|1@0+ (1,0) [0|1] "" PDR,TCP,CSM,CSM_AV,VCU
 SG_ FWDECP_RstOccAuth : 55|1@0+ (1,0) [0|1] "" PDR,TCP,CSM,CSM_AV,VCU

BO_ 225 EB_PDU_5004: 8 CGM
 SG_ PrplSysMtrBSpdAuth_Public : 6|16@0- (1,0) [-32768|32767] "RPM" AMP,VCU
 SG_ PrplSysMtrBSpdAuth_Public_Inv : 7|1@0+ (1,0) [0|1] "" AMP,VCU

BO_ 184 EB_PDU_5005: 8 CGM
 SG_ PrplSysMtrCSpdAuth_Public : 6|16@0- (1,0) [-32768|32767] "RPM" AMP,VCU
 SG_ PrplSysMtrCSpdAuth_Public_Inv : 7|1@0+ (1,0) [0|1] "" AMP,VCU

BO_ 1389 ElecShftRngSecDisp_PCSM_PDU: 8 CGM
 SG_ ElecShftRngSecDisp_PCSM : 0|64@1+ (1,0) [0|1.84467e+019] "" IPC,IPC_INT,VCU

BO_ 871 ElecShftRngSecDisp_Prtctd_PDU: 8 CGM
 SG_ ESRSDP_MAC : 7|27@0+ (1,0) [0|1.34218e+008] "" IPC,IPC_INT,VCU
 SG_ ESRSDP_FCnt : 28|5@0+ (1,0) [0|31] "" IPC,IPC_INT,VCU
 SG_ ESRSDP_Filler : 33|26@0+ (1,0) [0|6.71089e+007] "" IPC,IPC_INT,VCU
 SG_ ESRSDP_ARC : 35|2@0+ (1,0) [0|3] "" IPC,IPC_INT,VCU
 SG_ ESRSDP_ElecShftRngSecDispAuth : 39|4@0+ (1,0) [0|12] "" CSM,CSM_AV,IPC,IPC_INT,VCU

BO_ 1400 ElecStrgColLck_PCSM_PDU: 8 CGM
 SG_ ElecStrgColLck_PCSM : 0|64@1+ (1,0) [0|1.84467e+019] "" IPC,IPC_INT,VCU

BO_ 877 ElecStrgColLck_Prtctd_PDU: 5 CGM
 SG_ ESCLP_MAC : 7|27@0+ (1,0) [0|1.34218e+008] "" IPC,IPC_INT,VCU
 SG_ ESCLP_FCnt : 28|5@0+ (1,0) [0|31] "" IPC,IPC_INT,VCU
 SG_ ESCLP_ARC : 35|2@0+ (1,0) [0|3] "" IPC,IPC_INT,VCU
 SG_ ESCLP_StrgColLckdIndOnAuth : 36|1@0+ (1,0) [0|1] "" IPC,IPC_INT,VCU
 SG_ ESCLP_ServColLckIndOnAuth : 37|1@0+ (1,0) [0|1] "" IPC,IPC_INT,VCU
 SG_ ESCLP_ElecStrgColLckStsAuth : 39|2@0+ (1,0) [0|3] "" CSM,CSM_AV,IPC,IPC_INT,VCU

BO_ 1388 EnhdSrvsVhTpSp_PCSM_PDU: 8 TCP
 SG_ EnhdSrvsVhTpSp_PCSM : 0|64@1+ (1,0) [0|1.84467e+019] "" Vector__XXX

BO_ 869 EnhdSrvsVhTpSp_Prtctd_PDU: 6 TCP
 SG_ ESVTSP_MAC : 7|27@0+ (1,0) [0|1.34218e+008] "" Vector__XXX
 SG_ ESVTSP_FCnt : 28|5@0+ (1,0) [0|31] "" Vector__XXX
 SG_ ESVTSP_EnhdSrvsVhTpSpLimValAuth : 37|8@0+ (2,0) [0|510] "km/h" Vector__XXX
 SG_ ESVTSP_EnhdSrvsVhTpSpLimReqAuth : 39|2@0+ (1,0) [0|2] "" Vector__XXX
 SG_ ESVTSP_ARC : 45|2@0+ (1,0) [0|3] "" Vector__XXX

BO_ 1067 FOMI_ACP2_MCU_PDU: 6 CGM
 SG_ FOMI_ACP2_MCU_DTCNumber : 7|24@0+ (1,0) [0|1.67772e+007] "" TCP
 SG_ FOMI_ACP2_MCU_DTCTriggered : 31|1@0+ (1,0) [0|1] "" TCP

BO_ 1066 FOMI_ACP3_MCU_PDU: 6 CGM
 SG_ FOMI_ACP3_MCU_DTCNumber : 7|24@0+ (1,0) [0|1.67772e+007] "" TCP
 SG_ FOMI_ACP3_MCU_DTCTriggered : 31|1@0+ (1,0) [0|1] "" TCP

BO_ 2001 FOMI_ACP4_MCU_PDU: 6 CGM
 SG_ FOMI_ACP4_MCU_DTCNumber : 7|24@0+ (1,0) [0|1.67772e+007] "" TCP
 SG_ FOMI_ACP4_MCU_DTCTriggered : 31|1@0+ (1,0) [0|1] "" TCP

BO_ 2008 FOMI_BCM_PDU: 6 CGM
 SG_ FOMI_BCM_DTCNumber : 7|24@0+ (1,0) [0|1.67772e+007] "" TCP
 SG_ FOMI_BCM_DTCTriggered : 31|1@0+ (1,0) [0|1] "" TCP

BO_ 1065 FOMI_BSM_PDU: 6 CGM
 SG_ FOMI_BSM_DTCNumber : 7|24@0+ (1,0) [0|1.67772e+007] "" TCP
 SG_ FOMI_BSM_DTCTriggered : 31|1@0+ (1,0) [0|1] "" TCP

BO_ 2002 FOMI_EBCM_PDU: 6 CGM
 SG_ FOMI_EBCM_DTCNumber : 7|24@0+ (1,0) [0|1.67772e+007] "" TCP
 SG_ FOMI_EBCM_DTCTriggered : 31|1@0+ (1,0) [0|1] "" TCP

BO_ 2007 FOMI_ECM_PDU: 6 CGM
 SG_ FOMI_ECM_DTCNumber : 7|24@0+ (1,0) [0|1.67772e+007] "" TCP
 SG_ FOMI_ECM_DTCTriggered : 31|1@0+ (1,0) [0|1] "" TCP

BO_ 1064 FOMI_ECP_E_PDU: 6 CGM
 SG_ FOMI_ECP_E_DTCNumber : 7|24@0+ (1,0) [0|1.67772e+007] "" TCP
 SG_ FOMI_ECP_E_DTCTriggered : 31|1@0+ (1,0) [0|1] "" TCP

BO_ 2003 FOMI_ECP_H1_PDU: 6 CGM
 SG_ FOMI_ECP_H1_DTCNumber : 7|24@0+ (1,0) [0|1.67772e+007] "" TCP
 SG_ FOMI_ECP_H1_DTCTriggered : 31|1@0+ (1,0) [0|1] "" TCP

BO_ 1063 FOMI_ECP_H2_PDU: 6 CGM
 SG_ FOMI_ECP_H2_DTCNumber : 7|24@0+ (1,0) [0|1.67772e+007] "" TCP
 SG_ FOMI_ECP_H2_DTCTriggered : 31|1@0+ (1,0) [0|1] "" TCP

BO_ 1062 FOMI_ECP_H3_PDU: 6 CGM
 SG_ FOMI_ECP_H3_DTCNumber : 7|24@0+ (1,0) [0|1.67772e+007] "" TCP
 SG_ FOMI_ECP_H3_DTCTriggered : 31|1@0+ (1,0) [0|1] "" TCP

BO_ 1072 FOMI_ECP_S2_PDU: 6 CGM
 SG_ FOMI_ECP_S2_DTCNumber : 7|24@0+ (1,0) [0|1.67772e+007] "" TCP
 SG_ FOMI_ECP_S2_DTCTriggered : 31|1@0+ (1,0) [0|1] "" TCP

BO_ 1995 FOMI_ECP_S_PDU: 6 CGM
 SG_ FOMI_ECP_S_DTCNumber : 7|24@0+ (1,0) [0|1.67772e+007] "" TCP
 SG_ FOMI_ECP_S_DTCTriggered : 31|1@0+ (1,0) [0|1] "" TCP

BO_ 1071 FOMI_ECP_X1_PDU: 6 CGM
 SG_ FOMI_ECP_X1_DTCNumber : 7|24@0+ (1,0) [0|1.67772e+007] "" TCP
 SG_ FOMI_ECP_X1_DTCTriggered : 31|1@0+ (1,0) [0|1] "" TCP

BO_ 1996 FOMI_ELM_PDU: 6 CGM
 SG_ FOMI_ELM_DTCNumber : 7|24@0+ (1,0) [0|1.67772e+007] "" TCP
 SG_ FOMI_ELM_DTCTriggered : 31|1@0+ (1,0) [0|1] "" TCP

BO_ 1997 FOMI_EOCM_HCP1_PDU: 6 CGM
 SG_ FOMI_EOCM_HCP1_DTCNumber : 7|24@0+ (1,0) [0|1.67772e+007] "" TCP
 SG_ FOMI_EOCM_HCP1_DTCTriggered : 31|1@0+ (1,0) [0|1] "" TCP

BO_ 1070 FOMI_EOCM_PDU: 6 CGM
 SG_ FOMI_EOCM_DTCNumber : 7|24@0+ (1,0) [0|1.67772e+007] "" TCP
 SG_ FOMI_EOCM_DTCTriggered : 31|1@0+ (1,0) [0|1] "" TCP

BO_ 1069 FOMI_ICCM_PDU: 6 CGM
 SG_ FOMI_ICCM_DTCNumber : 7|24@0+ (1,0) [0|1.67772e+007] "" TCP
 SG_ FOMI_ICCM_DTCTriggered : 31|1@0+ (1,0) [0|1] "" TCP

BO_ 1998 FOMI_PCM_PDU: 6 CGM
 SG_ FOMI_PCM_DTCNumber : 7|24@0+ (1,0) [0|1.67772e+007] "" TCP
 SG_ FOMI_PCM_DTCTriggered : 31|1@0+ (1,0) [0|1] "" TCP

BO_ 1068 FOMI_TCM_PDU: 6 CGM
 SG_ FOMI_TCM_DTCNumber : 7|24@0+ (1,0) [0|1.67772e+007] "" TCP
 SG_ FOMI_TCM_DTCTriggered : 31|1@0+ (1,0) [0|1] "" TCP

BO_ 1999 FOMI_VECM_PDU: 6 CGM
 SG_ FOMI_VECM_DTCNumber : 7|24@0+ (1,0) [0|1.67772e+007] "" TCP
 SG_ FOMI_VECM_DTCTriggered : 31|1@0+ (1,0) [0|1] "" TCP

BO_ 2009 FOMI_VICM_PDU: 6 CGM
 SG_ FOMI_VICM_DTCNumber : 7|24@0+ (1,0) [0|1.67772e+007] "" TCP
 SG_ FOMI_VICM_DTCTriggered : 31|1@0+ (1,0) [0|1] "" TCP

BO_ 1508 FuelInfo_PDU: 8 CGM
 SG_ FI_FiltdDispTotFlLvlPct : 7|8@0+ (0.3921,0) [0|99.9855] "%" PDR,RadioLow,TCP,VKM,CSM,CSM_AV,IPC,IPC_INT,VCU
 SG_ FI_FiltdDispTotFlLvlTnk2Pct : 14|8@0+ (0.3921,0) [0|99.9855] "%" RadioLow,TCP,VKM,CSM,CSM_AV,IPC,IPC_INT,VCU
 SG_ FI_FiltdDispTotFlLvlPct_Inv : 15|1@0+ (1,0) [0|1] "" PDR,RadioLow,TCP,VKM,CSM,CSM_AV,IPC,IPC_INT,VCU
 SG_ FI_FiltdDispTotFlLvlTnk2Pct_Inv : 22|1@0+ (1,0) [0|1] "" TCP,VKM,CSM,CSM_AV,IPC,IPC_INT,VCU
 SG_ FI_CS : 50|11@0+ (1,0) [0|2047] "" IPC,IPC_INT,VCU
 SG_ FI_ARC : 55|2@0+ (1,0) [0|3] "" IPC,IPC_INT,VCU

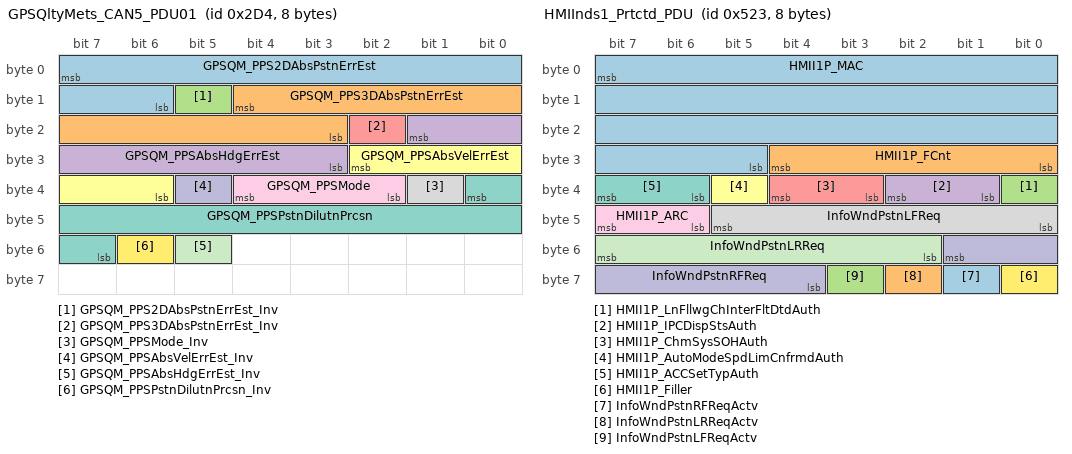
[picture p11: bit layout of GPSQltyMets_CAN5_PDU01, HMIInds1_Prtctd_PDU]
BO_ 724 GPSQltyMets_CAN5_PDU01: 8 TCP
 SG_ GPSQM_PPS2DAbsPstnErrEst : 7|10@0+ (0.1,0) [0|102.3] "m" CGM,VKM,CSM,CSM_AV,VCU
 SG_ GPSQM_PPS3DAbsPstnErrEst : 12|10@0+ (0.1,0) [0|102.3] "m" CGM,VKM,CSM,CSM_AV,VCU
 SG_ GPSQM_PPS2DAbsPstnErrEst_Inv : 13|1@0+ (1,0) [0|1] "" CGM,VKM,CSM,CSM_AV,VCU
 SG_ GPSQM_PPSAbsHdgErrEst : 17|7@0+ (0.5,0) [0|63.5] "deg" VKM,CSM,CSM_AV,VCU
 SG_ GPSQM_PPS3DAbsPstnErrEst_Inv : 18|1@0+ (1,0) [0|1] "" CGM,VKM,CSM,CSM_AV,VCU
 SG_ GPSQM_PPSAbsVelErrEst : 26|5@0+ (1,0) [0|31] "km/hr" CGM,VKM,CSM,CSM_AV,VCU
 SG_ GPSQM_PPSPstnDilutnPrcsn : 32|10@0+ (0.1,0) [0|102.3] "m" CGM,FPI,RSI,RadioLow,VKM,CSM,CSM_AV,VCU
 SG_ GPSQM_PPSMode_Inv : 33|1@0+ (1,0) [0|1] "" CGM,VKM,CSM,CSM_AV,VCU
 SG_ GPSQM_PPSMode : 36|3@0+ (1,0) [0|7] "" CGM,VKM,CSM,CSM_AV,VCU
 SG_ GPSQM_PPSAbsVelErrEst_Inv : 37|1@0+ (1,0) [0|1] "" CGM,VKM,CSM,CSM_AV,VCU
 SG_ GPSQM_PPSAbsHdgErrEst_Inv : 53|1@0+ (1,0) [0|1] "" VKM,CSM,CSM_AV,VCU
 SG_ GPSQM_PPSPstnDilutnPrcsn_Inv : 54|1@0+ (1,0) [0|1] "" CGM,RadioLow,VKM,CSM,CSM_AV,VCU

BO_ 725 GPSSysCoords_PDU01: 8 TCP
 SG_ GPSC_PPSLat : 7|30@0- (1,0) [-5.36871e+008|5.36871e+008] "ms arc" CGM,PDR,RadioLow,VKM,CSM,CSM_AV,VCU
 SG_ GPSC_PPSLong : 24|31@0- (1,0) [-1.07374e+009|1.07374e+009] "ms arc" CGM,PDR,RadioLow,VKM,CSM,CSM_AV,VCU
 SG_ GPSC_PPSLat_Inv : 25|1@0+ (1,0) [0|1] "" CGM,PDR,RadioLow,VKM,CSM,CSM_AV,VCU
 SG_ GPSC_PPSLong_Inv : 57|1@0+ (1,0) [0|1] "" CGM,PDR,RadioLow,VKM,CSM,CSM_AV,VCU

BO_ 726 GPSSysTm_CAN5_PDU01: 8 TCP
 SG_ GPST_PPSCldrDy : 7|9@0+ (1,0) [0|511] "day" RadioLow,CSM,CSM_AV,VCU
 SG_ GPST_PPSCldrYr : 13|7@0+ (1,2014) [2014|2141] "year" RadioLow,CSM,CSM_AV,VCU
 SG_ GPST_PPSCldrDy_Inv : 14|1@0+ (1,0) [0|1] "" RadioLow,CSM,CSM_AV,VCU
 SG_ GPST_PPSTmOfDy : 21|27@0+ (1,0) [0|1.34218e+008] "ms" CGM,RadioLow,CSM,CSM_AV,VCU
 SG_ GPST_PPSCldrYr_Inv : 22|1@0+ (1,0) [0|1] "" RadioLow,CSM,CSM_AV,VCU
 SG_ GPST_PPSTmOfDy_Inv : 42|1@0+ (1,0) [0|1] "" CGM,RadioLow,CSM,CSM_AV,VCU

BO_ 727 GPSSysVel_CAN5_PDU01: 8 TCP
 SG_ GPSV_PPSCalcdSpd : 7|8@0+ (1,0) [0|255] "km/h" CGM,RadioLow,VKM,CSM,CSM_AV,VCU
 SG_ GPSV_PPSElvtn : 14|21@0+ (1,-100000) [-100000|1.99715e+006] "cm" CGM,RadioLow,VKM,CSM,CSM_AV,VCU
 SG_ GPSV_PPSCalcdSpd_Inv : 15|1@0+ (1,0) [0|1] "" CGM,RadioLow,VKM,CSM,CSM_AV,VCU
 SG_ GPSV_PPSHdg : 24|19@0+ (0.001,0) [0|524.287] "deg" CGM,RadioLow,VKM,CSM,CSM_AV,VCU
 SG_ GPSV_PPSElvtn_Inv : 25|1@0+ (1,0) [0|1] "" CGM,RadioLow,VKM,CSM,CSM_AV,VCU
 SG_ GPSV_PPSHdg_Inv : 53|1@0+ (1,0) [0|1] "" CGM,RadioLow,VKM,CSM,CSM_AV,VCU

BO_ 1360 HMIGenInfo3_PCSM_PDU: 8 VCU
 SG_ HMIGenInfo3_PCSM : 0|64@1+ (1,0) [0|1.84467e+019] "" CGM

BO_ 1305 HMIGenInfo3_Prtctd_PDU: 8 VCU
 SG_ HMIGI3P_MAC : 7|27@0+ (1,0) [0|1.34218e+008] "" CGM
 SG_ HMIGI3P_FCnt : 28|5@0+ (1,0) [0|31] "" CGM
 SG_ CntrStckDispFlrIndOn : 32|1@0+ (1,0) [0|1] "" CGM
 SG_ VirtCtlAuxAlrmSnsrReqAuth : 34|2@0+ (1,0) [0|2] "" CGM
 SG_ HMIGI3P_ARC : 36|2@0+ (1,0) [0|3] "" CGM
 SG_ HMIGI3P_VirtCtlHdPrkLmpsReqAuth : 39|3@0+ (1,0) [0|4] "" CGM
 SG_ InfoWndMtnRRReq : 41|2@0+ (1,0) [0|3] "" CGM
 SG_ InfoWndMtnLRReq : 43|2@0+ (1,0) [0|3] "" CGM
 SG_ InfoWndMtnRFReq : 45|2@0+ (1,0) [0|3] "" CGM
 SG_ InfoWndMtnLFReq : 47|2@0+ (1,0) [0|3] "" CGM
 SG_ VirtCtlVehOnExtModeSwReqd : 48|1@0+ (1,0) [0|1] "" CGM
 SG_ VirtCtlVehEmrgOffSwReqd : 49|1@0+ (1,0) [0|1] "" CGM
 SG_ VirtCtlVehOffSwReq : 51|2@0+ (1,0) [0|2] "" CGM
 SG_ InfoSnrfPstnReq : 55|4@0+ (1,0) [0|11] "" CGM
 SG_ HMIGI3P_Filler : 56|1@0+ (1,0) [0|1] "" CGM
 SG_ InfoWndPstnRRReqActv : 57|1@0+ (1,0) [0|1] "" CGM
 SG_ InfoWndPstnRRReq : 63|6@0+ (1.5873,0) [0|100] "%" CGM

BO_ 1385 HMIInds1_PCSM_PDU: 8 IPC
 SG_ HMIInds1_PCSM : 0|64@1+ (1,0) [0|1.84467e+019] "" Vector__XXX

BO_ 1315 HMIInds1_Prtctd_PDU: 8 IPC
 SG_ HMII1P_MAC : 7|27@0+ (1,0) [0|1.34218e+008] "" CGM
 SG_ HMII1P_FCnt : 28|5@0+ (1,0) [0|31] "" CGM
 SG_ HMII1P_LnFllwgChInterFltDtdAuth : 32|1@0+ (1,0) [0|1] "" CGM
 SG_ HMII1P_IPCDispStsAuth : 34|2@0+ (1,0) [0|2] "" CGM
 SG_ HMII1P_ChmSysSOHAuth : 36|2@0+ (1,0) [0|2] "" CGM
 SG_ HMII1P_AutoModeSpdLimCnfrmdAuth : 37|1@0+ (1,0) [0|1] "" CGM,CSM,CSM_AV
 SG_ HMII1P_ACCSetTypAuth : 39|2@0+ (1,0) [0|1] "" CGM,TCP,CSM,CSM_AV
 SG_ InfoWndPstnLFReq : 45|6@0+ (1.5873,0) [0|100] "%" CGM
 SG_ HMII1P_ARC : 47|2@0+ (1,0) [0|3] "" CGM
 SG_ InfoWndPstnRFReq : 49|6@0+ (1.5873,0) [0|100] "%" CGM
 SG_ InfoWndPstnLRReq : 55|6@0+ (1.5873,0) [0|100] "%" CGM
 SG_ HMII1P_Filler : 56|1@0+ (1,0) [0|1] "" CGM
 SG_ InfoWndPstnRFReqActv : 57|1@0+ (1,0) [0|1] "" CGM
 SG_ InfoWndPstnLRReqActv : 58|1@0+ (1,0) [0|1] "" CGM
 SG_ InfoWndPstnLFReqActv : 59|1@0+ (1,0) [0|1] "" CGM

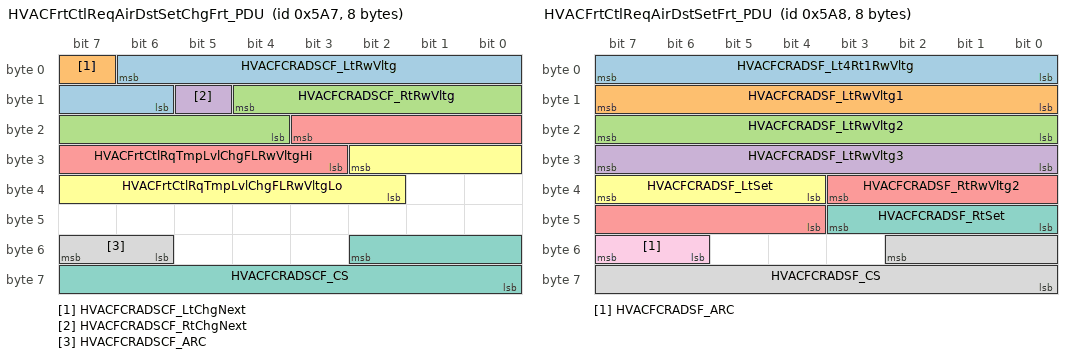
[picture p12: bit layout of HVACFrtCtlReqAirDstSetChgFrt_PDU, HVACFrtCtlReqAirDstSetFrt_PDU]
BO_ 1447 HVACFrtCtlReqAirDstSetChgFrt_PDU: 8 HVAC_FP_F
 SG_ HVACFCRADSCF_LtRwVltg : 6|9@0+ (0.01,0) [0|5.11] "Volts" Vector__XXX
 SG_ HVACFCRADSCF_LtChgNext : 7|1@0+ (1,0) [0|1] "" Vector__XXX
 SG_ HVACFCRADSCF_RtRwVltg : 12|9@0+ (0.01,0) [0|5.11] "Volts" Vector__XXX
 SG_ HVACFCRADSCF_RtChgNext : 13|1@0+ (1,0) [0|1] "" Vector__XXX
 SG_ HVACFrtCtlRqTmpLvlChgFLRwVltgHi : 19|9@0+ (0.01,0) [0|5.11] "Volts" Vector__XXX
 SG_ HVACFrtCtlRqTmpLvlChgFLRwVltgLo : 26|9@0+ (0.01,0) [0|5.11] "Volts" Vector__XXX
 SG_ HVACFCRADSCF_CS : 50|11@0+ (1,0) [0|2047] "" Vector__XXX
 SG_ HVACFCRADSCF_ARC : 55|2@0+ (1,0) [0|3] "Counts" Vector__XXX

BO_ 1448 HVACFrtCtlReqAirDstSetFrt_PDU: 8 HVAC_FP_F
 SG_ HVACFCRADSF_Lt4Rt1RwVltg : 7|8@0+ (0.02,0) [0|5.1] "Volts" Vector__XXX
 SG_ HVACFCRADSF_LtRwVltg1 : 15|8@0+ (0.02,0) [0|5.1] "Volts" Vector__XXX
 SG_ HVACFCRADSF_LtRwVltg2 : 23|8@0+ (0.02,0) [0|5.1] "Volts" Vector__XXX
 SG_ HVACFCRADSF_LtRwVltg3 : 31|8@0+ (0.02,0) [0|5.1] "Volts" Vector__XXX
 SG_ HVACFCRADSF_RtRwVltg2 : 35|8@0+ (0.02,0) [0|5.1] "Volts" Vector__XXX
 SG_ HVACFCRADSF_LtSet : 39|4@0+ (1,0) [0|8] "" Vector__XXX
 SG_ HVACFCRADSF_RtSet : 43|4@0+ (1,0) [0|8] "" Vector__XXX
 SG_ HVACFCRADSF_CS : 50|11@0+ (1,0) [0|2047] "" Vector__XXX
 SG_ HVACFCRADSF_ARC : 55|2@0+ (1,0) [0|3] "Counts" Vector__XXX

BO_ 1450 HVACFrtCtlReqBlwLvlChgFrtOR_PDU: 8 HVAC_FP_F
 SG_ HVACFCRBLCFOR_ORX1 : 7|10@0+ (1,0) [0|1023] "Counts" Vector__XXX
 SG_ HVACFCRBLCFOR_ORX2 : 13|10@0+ (1,0) [0|1023] "Counts" Vector__XXX
 SG_ HVACFCRBLCFOR_ORY1 : 19|10@0+ (1,0) [0|1023] "Counts" Vector__XXX
 SG_ HVACFCRBLCFOR_ORY2 : 25|10@0+ (1,0) [0|1023] "Counts" Vector__XXX
 SG_ HVACFCRBLCFOR_CS : 50|11@0+ (1,0) [0|2047] "" Vector__XXX
 SG_ HVACFCRBLCFOR_ARC : 55|2@0+ (1,0) [0|3] "Counts" Vector__XXX

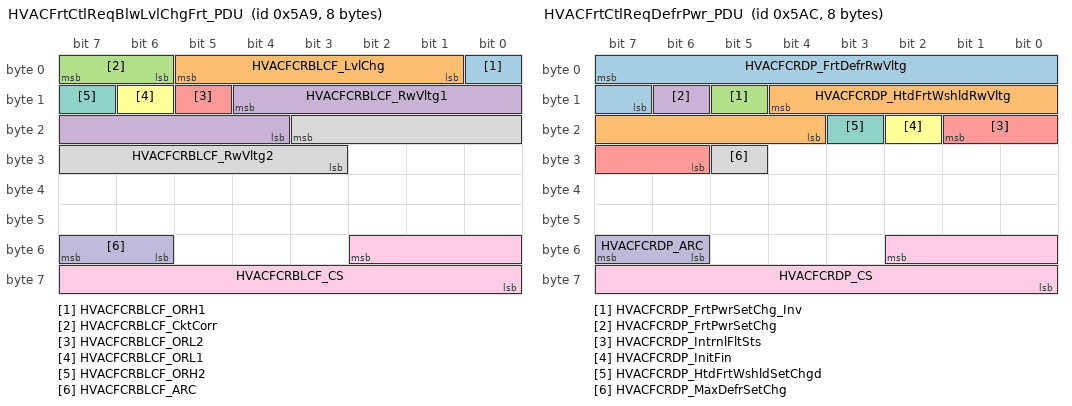
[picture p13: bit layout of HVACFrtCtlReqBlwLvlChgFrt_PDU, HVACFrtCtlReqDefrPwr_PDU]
BO_ 1449 HVACFrtCtlReqBlwLvlChgFrt_PDU: 8 HVAC_FP_F
 SG_ HVACFCRBLCF_ORH1 : 0|1@0+ (1,0) [0|1] "" Vector__XXX
 SG_ HVACFCRBLCF_LvlChg : 5|5@0- (1,0) [-16|15] "Counts" Vector__XXX
 SG_ HVACFCRBLCF_CktCorr : 7|2@0+ (1,0) [0|2] "" Vector__XXX
 SG_ HVACFCRBLCF_RwVltg1 : 12|9@0+ (0.01,0) [0|5.11] "Volts" Vector__XXX
 SG_ HVACFCRBLCF_ORL2 : 13|1@0+ (1,0) [0|1] "" Vector__XXX
 SG_ HVACFCRBLCF_ORL1 : 14|1@0+ (1,0) [0|1] "" Vector__XXX
 SG_ HVACFCRBLCF_ORH2 : 15|1@0+ (1,0) [0|1] "" Vector__XXX
 SG_ HVACFCRBLCF_RwVltg2 : 19|9@0+ (0.01,0) [0|5.11] "Volts" Vector__XXX
 SG_ HVACFCRBLCF_CS : 50|11@0+ (1,0) [0|2047] "" Vector__XXX
 SG_ HVACFCRBLCF_ARC : 55|2@0+ (1,0) [0|3] "Counts" Vector__XXX

BO_ 1451 HVACFrtCtlReqBlwLvlFrt_PDU: 8 HVAC_FP_F
 SG_ HVACFCRBLF_RwVltg : 2|9@0+ (0.01,0) [0|5.11] "Volts" Vector__XXX
 SG_ HVACFCRBLF_LvlActv : 3|1@0+ (1,0) [0|1] "" Vector__XXX
 SG_ HVACFCRBLF_Lvl : 7|4@0+ (1,0) [0|15] "Counts" Vector__XXX
 SG_ HVACFrtCtlReqBlwLvlFrtRwVltgHi : 9|9@0+ (0.01,0) [0|5.11] "0" Vector__XXX
 SG_ HVACFrtCtlReqBlwLvlFrtRwVltgLo : 16|9@0+ (0.01,0) [0|5.11] "0" Vector__XXX
 SG_ HVACFCRBLF_CS : 50|11@0+ (1,0) [0|2047] "" Vector__XXX
 SG_ HVACFCRBLF_ARC : 55|2@0+ (1,0) [0|3] "Counts" Vector__XXX

BO_ 1452 HVACFrtCtlReqDefrPwr_PDU: 8 HVAC_FP_F
 SG_ HVACFCRDP_FrtDefrRwVltg : 7|9@0+ (0.01,0) [0|5.11] "Volts" Vector__XXX
 SG_ HVACFCRDP_HtdFrtWshldRwVltg : 12|9@0+ (0.01,0) [0|5.11] "Volts" Vector__XXX
 SG_ HVACFCRDP_FrtPwrSetChg_Inv : 13|1@0+ (1,0) [0|1] "" Vector__XXX
 SG_ HVACFCRDP_FrtPwrSetChg : 14|1@0+ (1,0) [0|1] "" Vector__XXX
 SG_ HVACFCRDP_IntrnlFltSts : 17|4@0+ (1,0) [0|15] "" Vector__XXX
 SG_ HVACFCRDP_InitFin : 18|1@0+ (1,0) [0|1] "" Vector__XXX
 SG_ HVACFCRDP_HtdFrtWshldSetChgd : 19|1@0+ (1,0) [0|1] "" Vector__XXX
 SG_ HVACFCRDP_MaxDefrSetChg : 29|1@0+ (1,0) [0|1] "" Vector__XXX
 SG_ HVACFCRDP_CS : 50|11@0+ (1,0) [0|2047] "" Vector__XXX
 SG_ HVACFCRDP_ARC : 55|2@0+ (1,0) [0|3] "Counts" Vector__XXX

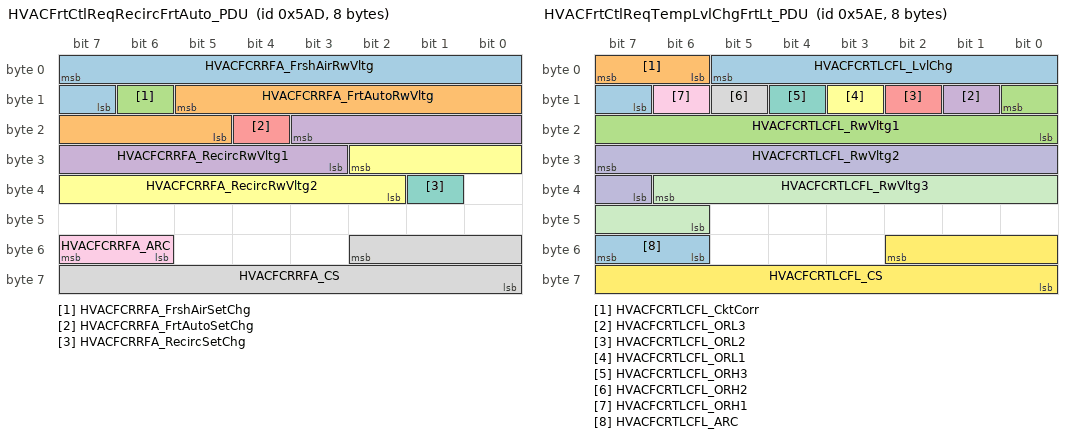
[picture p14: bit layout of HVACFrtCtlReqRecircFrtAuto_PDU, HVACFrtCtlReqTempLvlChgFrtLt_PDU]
BO_ 1453 HVACFrtCtlReqRecircFrtAuto_PDU: 8 HVAC_FP_F
 SG_ HVACFCRRFA_FrshAirRwVltg : 7|9@0+ (0.01,0) [0|5.11] "Volts" Vector__XXX
 SG_ HVACFCRRFA_FrtAutoRwVltg : 13|9@0+ (0.01,0) [0|5.11] "Volts" Vector__XXX
 SG_ HVACFCRRFA_FrshAirSetChg : 14|1@0+ (1,0) [0|1] "" Vector__XXX
 SG_ HVACFCRRFA_RecircRwVltg1 : 19|9@0+ (0.01,0) [0|5.11] "Volts" Vector__XXX
 SG_ HVACFCRRFA_FrtAutoSetChg : 20|1@0+ (1,0) [0|1] "" Vector__XXX
 SG_ HVACFCRRFA_RecircRwVltg2 : 26|9@0+ (0.01,0) [0|5.11] "Volts" Vector__XXX
 SG_ HVACFCRRFA_RecircSetChg : 33|1@0+ (1,0) [0|1] "" Vector__XXX
 SG_ HVACFCRRFA_CS : 50|11@0+ (1,0) [0|2047] "" Vector__XXX
 SG_ HVACFCRRFA_ARC : 55|2@0+ (1,0) [0|3] "Counts" Vector__XXX

BO_ 1455 HVACFrtCtlReqTempLvlChgFrtLtOR1n: 8 HVAC_FP_F
 SG_ HVACFCRTLCFLOR1n2_ORX1 : 7|10@0+ (1,0) [0|1023] "Counts" Vector__XXX
 SG_ HVACFCRTLCFLOR1n2_ORX2 : 13|10@0+ (1,0) [0|1023] "Counts" Vector__XXX
 SG_ HVACFCRTLCFLOR1n2_ORY1 : 19|10@0+ (1,0) [0|1023] "Counts" Vector__XXX
 SG_ HVACFCRTLCFLOR1n2_ORY2 : 25|10@0+ (1,0) [0|1023] "Counts" Vector__XXX
 SG_ HVACFCRTLCFLOR1n2_CS : 50|11@0+ (1,0) [0|2047] "" Vector__XXX
 SG_ HVACFCRTLCFLOR1n2_ARC : 55|2@0+ (1,0) [0|3] "Counts" Vector__XXX

BO_ 1454 HVACFrtCtlReqTempLvlChgFrtLt_PDU: 8 HVAC_FP_F
 SG_ HVACFCRTLCFL_LvlChg : 5|7@0- (1,0) [-64|63] "Counts" Vector__XXX
 SG_ HVACFCRTLCFL_CktCorr : 7|2@0+ (1,0) [0|2] "" Vector__XXX
 SG_ HVACFCRTLCFL_RwVltg1 : 8|9@0+ (0.01,0) [0|5.11] "Volts" Vector__XXX
 SG_ HVACFCRTLCFL_ORL3 : 9|1@0+ (1,0) [0|1] "" Vector__XXX
 SG_ HVACFCRTLCFL_ORL2 : 10|1@0+ (1,0) [0|1] "" Vector__XXX
 SG_ HVACFCRTLCFL_ORL1 : 11|1@0+ (1,0) [0|1] "" Vector__XXX
 SG_ HVACFCRTLCFL_ORH3 : 12|1@0+ (1,0) [0|1] "" Vector__XXX
 SG_ HVACFCRTLCFL_ORH2 : 13|1@0+ (1,0) [0|1] "" Vector__XXX
 SG_ HVACFCRTLCFL_ORH1 : 14|1@0+ (1,0) [0|1] "" Vector__XXX
 SG_ HVACFCRTLCFL_RwVltg2 : 31|9@0+ (0.01,0) [0|5.11] "Volts" Vector__XXX
 SG_ HVACFCRTLCFL_RwVltg3 : 38|9@0+ (0.01,0) [0|5.11] "Volts" Vector__XXX
 SG_ HVACFCRTLCFL_CS : 50|11@0+ (1,0) [0|2047] "" Vector__XXX
 SG_ HVACFCRTLCFL_ARC : 55|2@0+ (1,0) [0|3] "Counts" Vector__XXX

BO_ 1456 HVACFrtCtlReqTempLvlChgFrtOR3_PD: 8 HVAC_FP_F
 SG_ HVACFCRTLCFOR3_LtORX3 : 7|10@0+ (1,0) [0|1023] "Counts" Vector__XXX
 SG_ HVACFCRTLCFOR3_LtORY3 : 13|10@0+ (1,0) [0|1023] "Counts" Vector__XXX
 SG_ HVACFCRTLCFOR3_RtORX3 : 19|10@0+ (1,0) [0|1023] "Counts" Vector__XXX
 SG_ HVACFCRTLCFOR3_RtORY3 : 25|10@0+ (1,0) [0|1023] "Counts" Vector__XXX
 SG_ HVACFCRTLCFOR3_CS : 50|11@0+ (1,0) [0|2047] "" Vector__XXX
 SG_ HVACFCRTLCFOR3_ARC : 55|2@0+ (1,0) [0|3] "" Vector__XXX

BO_ 1458 HVACFrtCtlReqTempLvlChgFrtRtOR1n: 8 HVAC_FP_F
 SG_ HVACFCRTLCFROR1n2_ORX1 : 7|10@0+ (1,0) [0|1023] "Counts" Vector__XXX
 SG_ HVACFCRTLCFROR1n2_ORX2 : 13|10@0+ (1,0) [0|1023] "Counts" Vector__XXX
 SG_ HVACFCRTLCFROR1n2_ORY1 : 19|10@0+ (1,0) [0|1023] "Counts" Vector__XXX
 SG_ HVACFCRTLCFROR1n2_ORY2 : 25|10@0+ (1,0) [0|1023] "Counts" Vector__XXX
 SG_ HVACFCRTLCFROR1n2_CS : 50|11@0+ (1,0) [0|2047] "" Vector__XXX
 SG_ HVACFCRTLCFROR1n2_ARC : 55|2@0+ (1,0) [0|3] "Counts" Vector__XXX

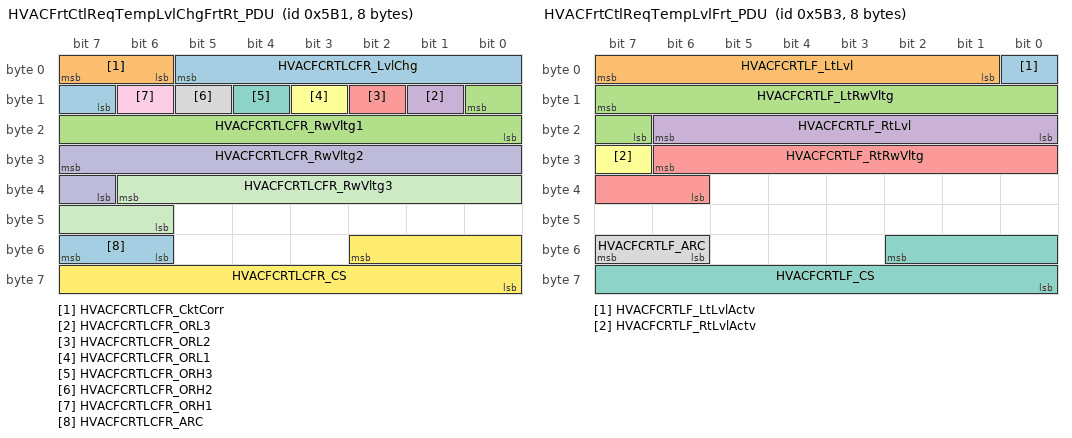
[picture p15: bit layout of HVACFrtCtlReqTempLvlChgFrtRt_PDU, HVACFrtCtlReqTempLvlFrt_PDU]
BO_ 1457 HVACFrtCtlReqTempLvlChgFrtRt_PDU: 8 HVAC_FP_F
 SG_ HVACFCRTLCFR_LvlChg : 5|7@0- (1,0) [-64|63] "Counts" Vector__XXX
 SG_ HVACFCRTLCFR_CktCorr : 7|2@0+ (1,0) [0|2] "" Vector__XXX
 SG_ HVACFCRTLCFR_RwVltg1 : 8|9@0+ (0.01,0) [0|5.11] "Volts" Vector__XXX
 SG_ HVACFCRTLCFR_ORL3 : 9|1@0+ (1,0) [0|1] "" Vector__XXX
 SG_ HVACFCRTLCFR_ORL2 : 10|1@0+ (1,0) [0|1] "" Vector__XXX
 SG_ HVACFCRTLCFR_ORL1 : 11|1@0+ (1,0) [0|1] "" Vector__XXX
 SG_ HVACFCRTLCFR_ORH3 : 12|1@0+ (1,0) [0|1] "" Vector__XXX
 SG_ HVACFCRTLCFR_ORH2 : 13|1@0+ (1,0) [0|1] "" Vector__XXX
 SG_ HVACFCRTLCFR_ORH1 : 14|1@0+ (1,0) [0|1] "" Vector__XXX
 SG_ HVACFCRTLCFR_RwVltg2 : 31|9@0+ (0.01,0) [0|5.11] "Volts" Vector__XXX
 SG_ HVACFCRTLCFR_RwVltg3 : 38|9@0+ (0.01,0) [0|5.11] "Volts" Vector__XXX
 SG_ HVACFCRTLCFR_CS : 50|11@0+ (1,0) [0|2047] "" Vector__XXX
 SG_ HVACFCRTLCFR_ARC : 55|2@0+ (1,0) [0|3] "" Vector__XXX

BO_ 1459 HVACFrtCtlReqTempLvlFrt_PDU: 8 HVAC_FP_F
 SG_ HVACFCRTLF_LtLvlActv : 0|1@0+ (1,0) [0|1] "" Vector__XXX
 SG_ HVACFCRTLF_LtLvl : 7|7@0+ (1,-16) [-16|111] "Counts" Vector__XXX
 SG_ HVACFCRTLF_LtRwVltg : 15|9@0+ (0.01,0) [0|5.11] "Volts" Vector__XXX
 SG_ HVACFCRTLF_RtLvl : 22|7@0+ (1,-16) [-16|111] "Counts" Vector__XXX
 SG_ HVACFCRTLF_RtRwVltg : 30|9@0+ (0.01,0) [0|5.11] "Volts" Vector__XXX
 SG_ HVACFCRTLF_RtLvlActv : 31|1@0+ (1,0) [0|1] "" Vector__XXX
 SG_ HVACFCRTLF_CS : 50|11@0+ (1,0) [0|2047] "" Vector__XXX
 SG_ HVACFCRTLF_ARC : 55|2@0+ (1,0) [0|3] "Counts" Vector__XXX

BO_ 1460 HVACFrtCtlRqTmpLvlChgFrtLtInfo2_: 8 HVAC_FP_F
 SG_ HVACFCRTLCFLI2_ORX4 : 5|10@0+ (1,0) [0|1023] "Counts" Vector__XXX
 SG_ HVACFCRTLCFLI2_ORL4 : 6|1@0+ (1,0) [0|1] "" Vector__XXX
 SG_ HVACFCRTLCFLI2_ORH4 : 7|1@0+ (1,0) [0|1] "" Vector__XXX
 SG_ HVACFCRTLCFLI2_ORY4 : 11|10@0+ (1,0) [0|1023] "Counts" Vector__XXX
 SG_ HVACFCRTLCFLI2_RwVltg4 : 17|9@0+ (0.01,0) [0|5.11] "Volts" Vector__XXX
 SG_ HVACFCRTLCFLI2_CS : 50|11@0+ (1,0) [0|2047] "" Vector__XXX
 SG_ HVACFCRTLCFLI2_ARC : 55|2@0+ (1,0) [0|3] "" Vector__XXX

BO_ 1461 HVACFrtCtlRqTmpLvlChgFrtRtInfo2_: 8 HVAC_FP_F
 SG_ HVACFCRTLCFRI2_ORX4 : 5|10@0+ (1,0) [0|1023] "Counts" Vector__XXX
 SG_ HVACFCRTLCFRI2_ORL4 : 6|1@0+ (1,0) [0|1] "" Vector__XXX
 SG_ HVACFCRTLCFRI2_ORH4 : 7|1@0+ (1,0) [0|1] "" Vector__XXX
 SG_ HVACFCRTLCFRI2_ORY4 : 11|10@0+ (1,0) [0|1023] "Counts" Vector__XXX
 SG_ HVACFCRTLCFRI2_RwVltg4 : 17|9@0+ (0.01,0) [0|5.11] "Volts" Vector__XXX
 SG_ HVACFCRTLCFRI2_CS : 50|11@0+ (1,0) [0|2047] "" Vector__XXX
 SG_ HVACFCRTLCFRI2_ARC : 55|2@0+ (1,0) [0|3] "" Vector__XXX

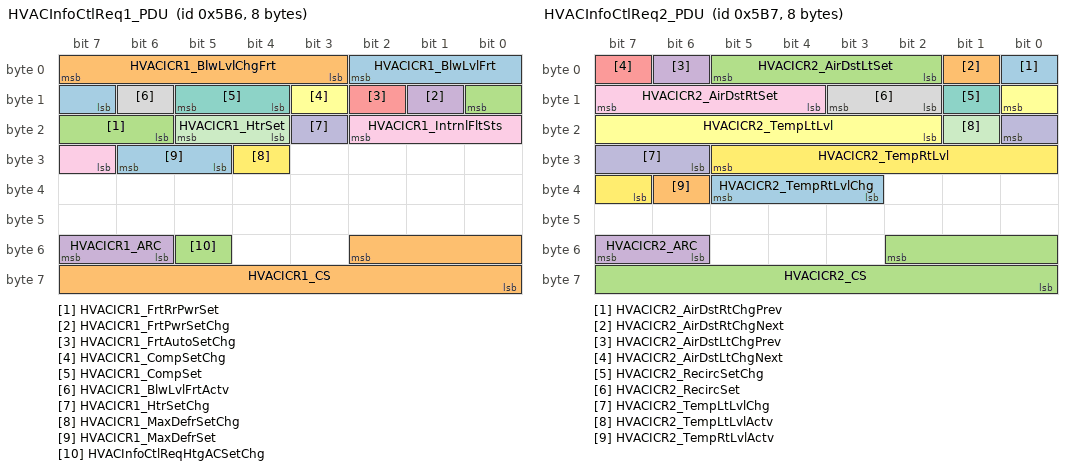
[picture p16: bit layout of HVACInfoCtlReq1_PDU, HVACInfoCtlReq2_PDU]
BO_ 1462 HVACInfoCtlReq1_PDU: 8 RadioLow
 SG_ HVACICR1_BlwLvlFrt : 2|4@0+ (1,0) [0|15] "Counts" Vector__XXX
 SG_ HVACICR1_BlwLvlChgFrt : 7|5@0- (1,0) [-16|15] "Counts" Vector__XXX
 SG_ HVACICR1_FrtRrPwrSet : 8|3@0+ (1,0) [0|4] "" Vector__XXX
 SG_ HVACICR1_FrtPwrSetChg : 9|1@0+ (1,0) [0|1] "" Vector__XXX
 SG_ HVACICR1_FrtAutoSetChg : 10|1@0+ (1,0) [0|1] "" Vector__XXX
 SG_ HVACICR1_CompSetChg : 11|1@0+ (1,0) [0|1] "" Vector__XXX
 SG_ HVACICR1_CompSet : 13|2@0+ (1,0) [0|3] "" Vector__XXX
 SG_ HVACICR1_BlwLvlFrtActv : 14|1@0+ (1,0) [0|1] "" Vector__XXX
 SG_ HVACICR1_IntrnlFltSts : 18|4@0+ (1,0) [0|15] "" Vector__XXX
 SG_ HVACICR1_HtrSetChg : 19|1@0+ (1,0) [0|1] "" Vector__XXX
 SG_ HVACICR1_HtrSet : 21|2@0+ (1,0) [0|2] "" Vector__XXX
 SG_ HVACICR1_MaxDefrSetChg : 28|1@0+ (1,0) [0|1] "" Vector__XXX
 SG_ HVACICR1_MaxDefrSet : 30|2@0+ (1,0) [0|2] "" Vector__XXX
 SG_ HVACICR1_CS : 50|11@0+ (1,0) [0|2047] "" Vector__XXX
 SG_ HVACInfoCtlReqHtgACSetChg : 53|1@0+ (1,0) [0|1] "" Vector__XXX
 SG_ HVACICR1_ARC : 55|2@0+ (1,0) [0|3] "" Vector__XXX

BO_ 1463 HVACInfoCtlReq2_PDU: 8 RadioLow
 SG_ HVACICR2_AirDstRtChgPrev : 0|1@0+ (1,0) [0|1] "" Vector__XXX
 SG_ HVACICR2_AirDstRtChgNext : 1|1@0+ (1,0) [0|1] "" Vector__XXX
 SG_ HVACICR2_AirDstLtSet : 5|4@0+ (1,0) [0|8] "" Vector__XXX
 SG_ HVACICR2_AirDstLtChgPrev : 6|1@0+ (1,0) [0|1] "" Vector__XXX
 SG_ HVACICR2_AirDstLtChgNext : 7|1@0+ (1,0) [0|1] "" Vector__XXX
 SG_ HVACICR2_TempLtLvl : 8|7@0+ (1,-16) [-16|111] "Counts" Vector__XXX
 SG_ HVACICR2_RecircSetChg : 9|1@0+ (1,0) [0|1] "" Vector__XXX
 SG_ HVACICR2_RecircSet : 11|2@0+ (1,0) [0|2] "" Vector__XXX
 SG_ HVACICR2_AirDstRtSet : 15|4@0+ (1,0) [0|8] "" Vector__XXX
 SG_ HVACICR2_TempLtLvlChg : 16|3@0- (1,0) [-4|3] "Counts" Vector__XXX
 SG_ HVACICR2_TempLtLvlActv : 17|1@0+ (1,0) [0|1] "" Vector__XXX
 SG_ HVACICR2_TempRtLvl : 29|7@0+ (1,-16) [-16|111] "Counts" Vector__XXX
 SG_ HVACICR2_TempRtLvlChg : 37|3@0- (1,0) [-4|3] "Counts" Vector__XXX
 SG_ HVACICR2_TempRtLvlActv : 38|1@0+ (1,0) [0|1] "" Vector__XXX
 SG_ HVACICR2_CS : 50|11@0+ (1,0) [0|2047] "" Vector__XXX
 SG_ HVACICR2_ARC : 55|2@0+ (1,0) [0|3] "" Vector__XXX

BO_ 358 ICS_Info_NM_PDU_On_CAN_5_Cluster: 8 ICS_Info
 SG_ ISignal_ICS_Info_CAN_5_Cluster : 23|48@0+ (1,0) [0|281474976710655] "" AMP,CGM,FPI,HVAC_FP_F,HVAC_FP_R,PDR,MFC,PLCM,RSI,RadioLow,TCP,VKM,CSM,CSM_AV,IPC,IPC_INT,VCU,WCM,WCM2,WCM3,WCM4

BO_ 352 IPC_INT_NM_PDU_On_CAN_5_Cluster: 8 IPC_INT
 SG_ ISignal_IPC_INT_CAN_5_Cluster : 23|48@0+ (1,0) [0|281474976710655] "" AMP,CGM,FPI,HVAC_FP_F,HVAC_FP_R,ICS_Info,PDR,MFC,PLCM,RSI,RadioLow,TCP,VKM,CSM,CSM_AV,VCU,WCM,WCM2,WCM3,WCM4

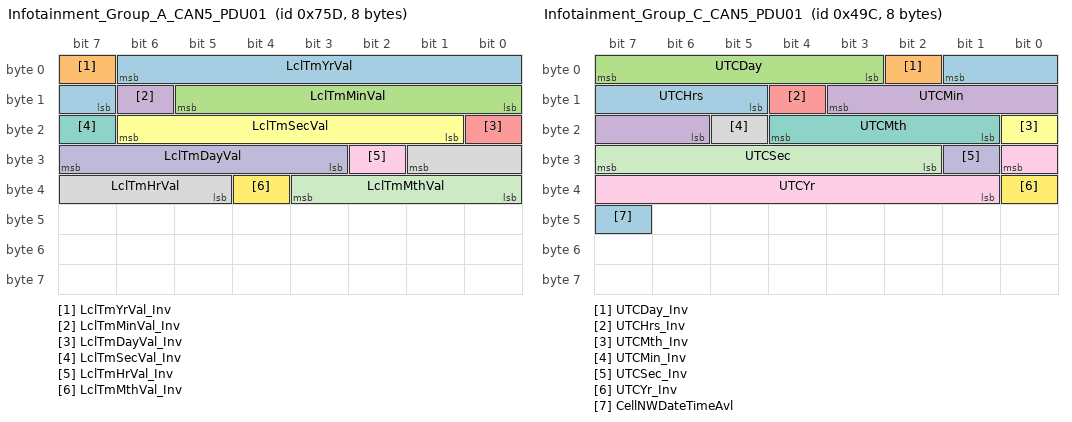
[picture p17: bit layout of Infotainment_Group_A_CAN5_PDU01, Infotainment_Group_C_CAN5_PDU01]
BO_ 1885 Infotainment_Group_A_CAN5_PDU01: 8 TCP
 SG_ LclTmYrVal : 6|8@0+ (1,2000) [2000|2255] "year" CGM,FPI,RSI,RadioLow,CSM,CSM_AV,VCU
 SG_ LclTmYrVal_Inv : 7|1@0+ (1,0) [0|1] "" FPI,RSI,RadioLow,CSM,CSM_AV,VCU
 SG_ LclTmMinVal : 13|6@0+ (1,0) [0|63] "minutes" CGM,FPI,RSI,RadioLow,CSM,CSM_AV,VCU
 SG_ LclTmMinVal_Inv : 14|1@0+ (1,0) [0|1] "" FPI,RSI,RadioLow,CSM,CSM_AV,VCU
 SG_ LclTmDayVal_Inv : 16|1@0+ (1,0) [0|1] "" FPI,RSI,RadioLow,CSM,CSM_AV,VCU
 SG_ LclTmSecVal : 22|6@0+ (1,0) [0|63] "seconds" CGM,FPI,RSI,RadioLow,CSM,CSM_AV,VCU
 SG_ LclTmSecVal_Inv : 23|1@0+ (1,0) [0|1] "" FPI,RSI,RadioLow,CSM,CSM_AV,VCU
 SG_ LclTmHrVal : 25|5@0+ (1,0) [0|31] "hours" CGM,FPI,RSI,RadioLow,CSM,CSM_AV,VCU
 SG_ LclTmHrVal_Inv : 26|1@0+ (1,0) [0|1] "" FPI,RSI,RadioLow,CSM,CSM_AV,VCU
 SG_ LclTmDayVal : 31|5@0+ (1,0) [0|31] "day" CGM,FPI,RSI,RadioLow,CSM,CSM_AV,VCU
 SG_ LclTmMthVal : 35|4@0+ (1,0) [0|12] "" CGM,FPI,RSI,RadioLow,CSM,CSM_AV,VCU
 SG_ LclTmMthVal_Inv : 36|1@0+ (1,0) [0|1] "" FPI,RSI,RadioLow,CSM,CSM_AV,VCU

BO_ 1439 Infotainment_Group_B_CAN5_PDU01: 8 ICS_Info
 SG_ FrtCntrStckEncdr4 : 7|8@0- (1,0) [-128|127] "count" TCP,CSM,CSM_AV,VCU
 SG_ FrtCntrStckEncdr5 : 15|8@0- (1,0) [-128|127] "count" TCP,CSM,CSM_AV,VCU
 SG_ FrtCntrStckMenuEncdr : 23|8@0- (1,0) [-128|127] "count" TCP,CSM,CSM_AV,VCU
 SG_ FrtCntrStckTuneEncdr : 31|8@0- (1,0) [-128|127] "count" TCP,CSM,CSM_AV,VCU
 SG_ FrtCntrStckVolEncdr : 39|8@0- (1,0) [-128|127] "count" TCP,CSM,CSM_AV,VCU
 SG_ FrtCntrStckFvrtUpSw : 40|1@0+ (1,0) [0|1] "" TCP,CSM,CSM_AV,VCU
 SG_ FrtCntrStckFvrtDnSw : 41|1@0+ (1,0) [0|1] "" TCP,CSM,CSM_AV,VCU
 SG_ FrtCntrStckEjectSw : 42|1@0+ (1,0) [0|1] "" TCP,CSM,CSM_AV,VCU
 SG_ FrtCntrStckDiscAuxSw : 43|1@0+ (1,0) [0|1] "" TCP,CSM,CSM_AV,VCU
 SG_ FrtCntrStckBndSw : 44|1@0+ (1,0) [0|1] "" TCP,CSM,CSM_AV,VCU
 SG_ FrtCntrStckBnchBtnID_VirtSw : 45|1@0+ (1,0) [0|1] "" CSM,CSM_AV,VCU
 SG_ FrtCntrStckBackSw : 46|1@0+ (1,0) [0|1] "" TCP,CSM,CSM_AV,VCU
 SG_ FrtCntrStckAllRelSw : 47|1@0+ (1,0) [0|1] "" TCP,CSM,CSM_AV,VCU
 SG_ FrtCntrStckSw24 : 48|1@0+ (1,0) [0|1] "" TCP,CSM,CSM_AV,VCU
 SG_ FrtCntrStckSw23 : 49|1@0+ (1,0) [0|1] "" TCP,CSM,CSM_AV,VCU
 SG_ FrtCntrStckStrgeUnlckSw : 50|1@0+ (1,0) [0|1] "" CSM,CSM_AV,VCU
 SG_ FrtCntrStckPwrSw : 51|1@0+ (1,0) [0|1] "" TCP,CSM,CSM_AV,VCU
 SG_ FrtCntrStckPrevSw : 52|1@0+ (1,0) [0|1] "" TCP,CSM,CSM_AV,VCU
 SG_ FrtCntrStckNextSw : 53|1@0+ (1,0) [0|1] "" TCP,CSM,CSM_AV,VCU
 SG_ FrtCntrStckMenuSw : 54|1@0+ (1,0) [0|1] "" TCP,CSM,CSM_AV,VCU
 SG_ FrtCntrStckHomeSw : 55|1@0+ (1,0) [0|1] "" TCP,CSM,CSM_AV,VCU
 SG_ FrtCntrStckSw32 : 56|1@0+ (1,0) [0|1] "" TCP,CSM,CSM_AV,VCU
 SG_ FrtCntrStckSw31 : 57|1@0+ (1,0) [0|1] "" TCP,CSM,CSM_AV,VCU
 SG_ FrtCntrStckSw30 : 58|1@0+ (1,0) [0|1] "" TCP,CSM,CSM_AV,VCU
 SG_ FrtCntrStckSw29 : 59|1@0+ (1,0) [0|1] "" TCP,CSM,CSM_AV,VCU
 SG_ FrtCntrStckSw28 : 60|1@0+ (1,0) [0|1] "" TCP,CSM,CSM_AV,VCU
 SG_ FrtCntrStckSw27 : 61|1@0+ (1,0) [0|1] "" TCP,CSM,CSM_AV,VCU
 SG_ FrtCntrStckSw26 : 62|1@0+ (1,0) [0|1] "" TCP,CSM,CSM_AV,VCU
 SG_ FrtCntrStckSw25 : 63|1@0+ (1,0) [0|1] "" TCP,CSM,CSM_AV,VCU

BO_ 1180 Infotainment_Group_C_CAN5_PDU01: 8 TCP
 SG_ UTCHrs : 1|5@0+ (1,0) [0|31] "hour" CGM,FPI,RSI,RadioLow,CSM,CSM_AV,VCU
 SG_ UTCDay_Inv : 2|1@0+ (1,0) [0|1] "" CGM,FPI,RSI,RadioLow,CSM,CSM_AV,VCU
 SG_ UTCDay : 7|5@0+ (1,0) [0|31] "day" CGM,FPI,RSI,RadioLow,CSM,CSM_AV,VCU
 SG_ UTCMin : 11|6@0+ (1,0) [0|63] "minutes" CGM,FPI,RSI,RadioLow,CSM,CSM_AV,VCU
 SG_ UTCHrs_Inv : 12|1@0+ (1,0) [0|1] "" CGM,FPI,RSI,RadioLow,CSM,CSM_AV,VCU
 SG_ UTCMth_Inv : 16|1@0+ (1,0) [0|1] "" CGM,FPI,RSI,RadioLow,CSM,CSM_AV,VCU
 SG_ UTCMth : 20|4@0+ (1,0) [0|12] "" CGM,FPI,RSI,RadioLow,CSM,CSM_AV,VCU
 SG_ UTCMin_Inv : 21|1@0+ (1,0) [0|1] "" CGM,FPI,RSI,RadioLow,CSM,CSM_AV,VCU
 SG_ UTCYr : 24|8@0+ (1,2000) [2000|2255] "year" CGM,FPI,RSI,RadioLow,CSM,CSM_AV,VCU
 SG_ UTCSec_Inv : 25|1@0+ (1,0) [0|1] "" CGM,FPI,RSI,RadioLow,CSM,CSM_AV,VCU
 SG_ UTCSec : 31|6@0+ (1,0) [0|63] "seconds" CGM,FPI,RSI,RadioLow,CSM,CSM_AV,VCU
 SG_ UTCYr_Inv : 32|1@0+ (1,0) [0|1] "" CGM,FPI,RSI,RadioLow,CSM,CSM_AV,VCU
 SG_ CellNWDateTimeAvl : 47|1@0+ (1,0) [0|1] "" RadioLow,CSM,CSM_AV,VCU

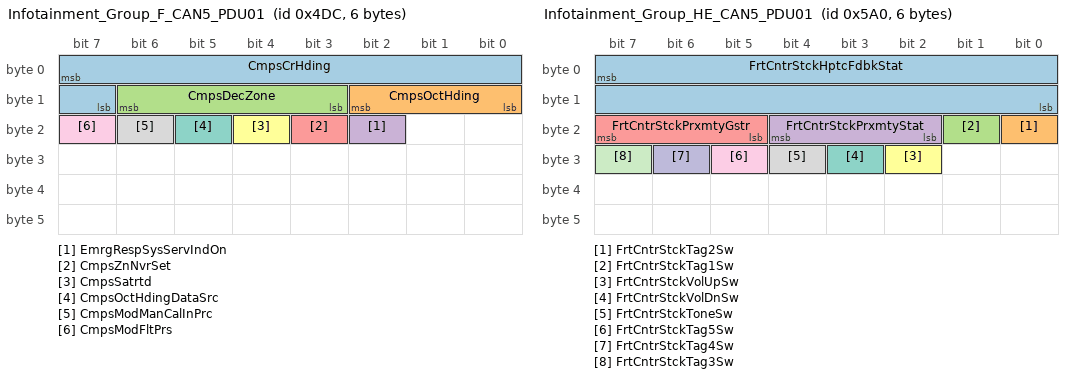
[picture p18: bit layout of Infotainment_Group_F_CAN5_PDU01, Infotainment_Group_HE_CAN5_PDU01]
BO_ 1244 Infotainment_Group_F_CAN5_PDU01: 6 TCP
 SG_ CmpsCrHding : 7|9@0+ (1,0) [0|511] "deg" RadioLow,CSM,CSM_AV,IPC,IPC_INT,VCU
 SG_ CmpsOctHding : 10|3@0+ (1,0) [0|7] "" FPI,RSI,RadioLow,CSM,CSM_AV,IPC,IPC_INT,VCU
 SG_ CmpsDecZone : 14|4@0+ (1,0) [0|15] "" RadioLow,CSM,CSM_AV,IPC,IPC_INT,VCU
 SG_ EmrgRespSysServIndOn : 18|1@0+ (1,0) [0|1] "" IPC,IPC_INT,VCU
 SG_ CmpsZnNvrSet : 19|1@0+ (1,0) [0|1] "" RadioLow,CSM,CSM_AV,VCU
 SG_ CmpsSatrtd : 20|1@0+ (1,0) [0|1] "" RadioLow,CSM,CSM_AV,VCU
 SG_ CmpsOctHdingDataSrc : 21|1@0+ (1,0) [0|1] "" RadioLow,CSM,CSM_AV,VCU
 SG_ CmpsModManCalInPrc : 22|1@0+ (1,0) [0|1] "" FPI,RSI,RadioLow,CSM,CSM_AV,IPC,IPC_INT,VCU
 SG_ CmpsModFltPrs : 23|1@0+ (1,0) [0|1] "" FPI,RSI,RadioLow,CSM,CSM_AV,IPC,IPC_INT,VCU

BO_ 1440 Infotainment_Group_HE_CAN5_PDU01: 6 ICS_Info
 SG_ FrtCntrStckHptcFdbkStat : 7|16@0+ (1,0) [0|15] "" TCP,CSM,CSM_AV,VCU
 SG_ FrtCntrStckTag2Sw : 16|1@0+ (1,0) [0|1] "" TCP,CSM,CSM_AV,VCU
 SG_ FrtCntrStckTag1Sw : 17|1@0+ (1,0) [0|1] "" TCP,CSM,CSM_AV,VCU
 SG_ FrtCntrStckPrxmtyStat : 20|3@0+ (1,0) [0|7] "" TCP,CSM,CSM_AV,VCU
 SG_ FrtCntrStckPrxmtyGstr : 23|3@0+ (1,0) [0|7] "" TCP,CSM,CSM_AV,VCU
 SG_ FrtCntrStckVolUpSw : 26|1@0+ (1,0) [0|1] "" TCP,CSM,CSM_AV,VCU
 SG_ FrtCntrStckVolDnSw : 27|1@0+ (1,0) [0|1] "" TCP,CSM,CSM_AV,VCU
 SG_ FrtCntrStckToneSw : 28|1@0+ (1,0) [0|1] "" TCP,CSM,CSM_AV,VCU
 SG_ FrtCntrStckTag5Sw : 29|1@0+ (1,0) [0|1] "" TCP,CSM,CSM_AV,VCU
 SG_ FrtCntrStckTag4Sw : 30|1@0+ (1,0) [0|1] "" TCP,CSM,CSM_AV,VCU
 SG_ FrtCntrStckTag3Sw : 31|1@0+ (1,0) [0|1] "" TCP,CSM,CSM_AV,VCU

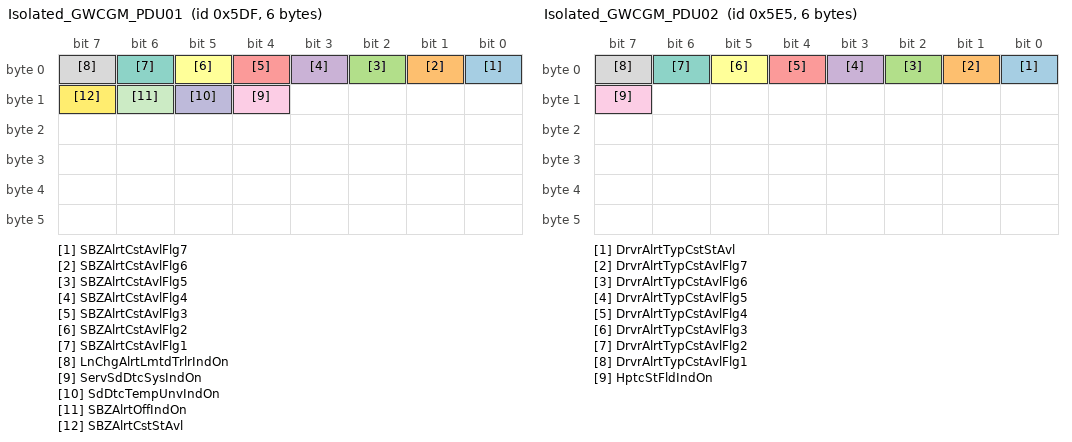
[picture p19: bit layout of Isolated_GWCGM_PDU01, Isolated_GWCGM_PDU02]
BO_ 1503 Isolated_GWCGM_PDU01: 6 CGM
 SG_ SBZAlrtCstAvlFlg7 : 0|1@0+ (1,0) [0|1] "" RadioLow,CSM,CSM_AV,VCU
 SG_ SBZAlrtCstAvlFlg6 : 1|1@0+ (1,0) [0|1] "" RadioLow,CSM,CSM_AV,VCU
 SG_ SBZAlrtCstAvlFlg5 : 2|1@0+ (1,0) [0|1] "" RadioLow,CSM,CSM_AV,VCU
 SG_ SBZAlrtCstAvlFlg4 : 3|1@0+ (1,0) [0|1] "" RadioLow,CSM,CSM_AV,VCU
 SG_ SBZAlrtCstAvlFlg3 : 4|1@0+ (1,0) [0|1] "" RadioLow,CSM,CSM_AV,VCU
 SG_ SBZAlrtCstAvlFlg2 : 5|1@0+ (1,0) [0|1] "" RadioLow,CSM,CSM_AV,VCU
 SG_ SBZAlrtCstAvlFlg1 : 6|1@0+ (1,0) [0|1] "" RadioLow,CSM,CSM_AV,VCU
 SG_ LnChgAlrtLmtdTrlrIndOn : 7|1@0+ (1,0) [0|1] "" IPC,IPC_INT,VCU
 SG_ ServSdDtcSysIndOn : 12|1@0+ (1,0) [0|1] "" TCP,IPC,IPC_INT,VCU
 SG_ SdDtcTempUnvIndOn : 13|1@0+ (1,0) [0|1] "" IPC,IPC_INT,VCU
 SG_ SBZAlrtOffIndOn : 14|1@0+ (1,0) [0|1] "" IPC,IPC_INT,VCU
 SG_ SBZAlrtCstStAvl : 15|1@0+ (1,0) [0|1] "" RadioLow,CSM,CSM_AV,VCU

BO_ 1509 Isolated_GWCGM_PDU02: 6 CGM
 SG_ DrvrAlrtTypCstStAvl : 0|1@0+ (1,0) [0|1] "" RadioLow,CSM,CSM_AV,VCU
 SG_ DrvrAlrtTypCstAvlFlg7 : 1|1@0+ (1,0) [0|1] "" RadioLow,CSM,CSM_AV,VCU
 SG_ DrvrAlrtTypCstAvlFlg6 : 2|1@0+ (1,0) [0|1] "" RadioLow,CSM,CSM_AV,VCU
 SG_ DrvrAlrtTypCstAvlFlg5 : 3|1@0+ (1,0) [0|1] "" RadioLow,CSM,CSM_AV,VCU
 SG_ DrvrAlrtTypCstAvlFlg4 : 4|1@0+ (1,0) [0|1] "" RadioLow,CSM,CSM_AV,VCU
 SG_ DrvrAlrtTypCstAvlFlg3 : 5|1@0+ (1,0) [0|1] "" RadioLow,CSM,CSM_AV,VCU
 SG_ DrvrAlrtTypCstAvlFlg2 : 6|1@0+ (1,0) [0|1] "" RadioLow,CSM,CSM_AV,VCU
 SG_ DrvrAlrtTypCstAvlFlg1 : 7|1@0+ (1,0) [0|1] "" RadioLow,CSM,CSM_AV,VCU
 SG_ HptcStFldIndOn : 15|1@0+ (1,0) [0|1] "" TCP,IPC,IPC_INT,VCU

BO_ 702 Isolated_GWCGM_PDU03: 4 CGM
 SG_ DrvrAppStrgTrq : 7|11@0- (0.01,0) [-10.24|10.23] "Nm" TCP
 SG_ StrgWhlTrqIntegSts : 10|2@0+ (1,0) [0|3] "" TCP
 SG_ StrgWhlHndsOffDtnStat : 12|2@0+ (1,0) [0|2] "" TCP

BA_DEF_ SG_  "SignalType" STRING ;
BA_DEF_ SG_  "SignalLongName" STRING ;
BA_DEF_ BO_  "GenMsgCycleTime" INT 0 10000;
BA_DEF_ BO_  "GenMsgSendType" ENUM "cyclicX","spontanX","cyclicIfActiveX","spontanWithDelay","cyclicAndSpontanX","cyclicAndSpontanWithDelay","spontanWithRepetition","cyclicIfActiveAndSpontanWD";
BA_DEF_DEF_  "SignalType" "";
BA_DEF_DEF_  "SignalLongName" "";
BA_DEF_DEF_  "GenMsgCycleTime" 0;
BA_DEF_DEF_  "GenMsgSendType" "cyclicX";
BA_ "GenMsgCycleTime" BO_ 1199 1000;
BA_ "GenMsgCycleTime" BO_ 1867 1000;
BA_ "GenMsgCycleTime" BO_ 1198 1000;
BA_ "GenMsgCycleTime" BO_ 1197 1000;
BA_ "GenMsgCycleTime" BO_ 1869 1000;
BA_ "GenMsgCycleTime" BO_ 1196 1000;
BA_ "GenMsgCycleTime" BO_ 1870 1000;
BA_ "GenMsgCycleTime" BO_ 1902 1000;
BA_ "GenMsgCycleTime" BO_ 1904 1000;
BA_ "GenMsgCycleTime" BO_ 1195 1000;
BA_ "GenMsgCycleTime" BO_ 1175 1000;
BA_ "GenMsgCycleTime" BO_ 1891 1000;
BA_ "GenMsgCycleTime" BO_ 1871 1000;
BA_ "GenMsgCycleTime" BO_ 1194 1000;
BA_ "GenMsgCycleTime" BO_ 1872 1000;
BA_ "GenMsgCycleTime" BO_ 1193 1000;
BA_ "GenMsgCycleTime" BO_ 1346 1000;
BA_ "GenMsgCycleTime" BO_ 1285 1000;
BA_ "GenMsgCycleTime" BO_ 1216 1000;
BA_ "GenMsgCycleTime" BO_ 1873 1000;
BA_ "GenMsgCycleTime" BO_ 1390 1000;
BA_ "GenMsgCycleTime" BO_ 872 250;
BA_ "GenMsgCycleTime" BO_ 1389 1000;
BA_ "GenMsgCycleTime" BO_ 871 250;
BA_ "GenMsgCycleTime" BO_ 1400 1000;
BA_ "GenMsgCycleTime" BO_ 877 250;
BA_ "GenMsgCycleTime" BO_ 1388 1000;
BA_ "GenMsgCycleTime" BO_ 869 250;
BA_ "GenMsgCycleTime" BO_ 1067 1000;
BA_ "GenMsgCycleTime" BO_ 1066 1000;
BA_ "GenMsgCycleTime" BO_ 2001 1000;
BA_ "GenMsgCycleTime" BO_ 2008 1000;
BA_ "GenMsgCycleTime" BO_ 1065 1000;
BA_ "GenMsgCycleTime" BO_ 2002 1000;
BA_ "GenMsgCycleTime" BO_ 2007 1000;
BA_ "GenMsgCycleTime" BO_ 1064 1000;
BA_ "GenMsgCycleTime" BO_ 2003 1000;
BA_ "GenMsgCycleTime" BO_ 1063 1000;
BA_ "GenMsgCycleTime" BO_ 1062 1000;
BA_ "GenMsgCycleTime" BO_ 1072 1000;
BA_ "GenMsgCycleTime" BO_ 1995 1000;
BA_ "GenMsgCycleTime" BO_ 1071 1000;
BA_ "GenMsgCycleTime" BO_ 1996 1000;
BA_ "GenMsgCycleTime" BO_ 1997 1000;
BA_ "GenMsgCycleTime" BO_ 1070 1000;
BA_ "GenMsgCycleTime" BO_ 1069 1000;
BA_ "GenMsgCycleTime" BO_ 1998 1000;
BA_ "GenMsgCycleTime" BO_ 1068 1000;
BA_ "GenMsgCycleTime" BO_ 1999 1000;
BA_ "GenMsgCycleTime" BO_ 2009 1000;
BA_ "GenMsgCycleTime" BO_ 1508 1000;
BA_ "GenMsgCycleTime" BO_ 724 100;
BA_ "GenMsgCycleTime" BO_ 725 100;
BA_ "GenMsgCycleTime" BO_ 726 100;
BA_ "GenMsgCycleTime" BO_ 727 100;
BA_ "GenMsgCycleTime" BO_ 1360 3500;
BA_ "GenMsgCycleTime" BO_ 1305 1000;
BA_ "GenMsgCycleTime" BO_ 1385 3500;
BA_ "GenMsgCycleTime" BO_ 1315 1000;
BA_ "GenMsgCycleTime" BO_ 1447 1000;
BA_ "GenMsgCycleTime" BO_ 1448 1000;
BA_ "GenMsgCycleTime" BO_ 1450 1000;
BA_ "GenMsgCycleTime" BO_ 1449 1000;
BA_ "GenMsgCycleTime" BO_ 1451 1000;
BA_ "GenMsgCycleTime" BO_ 1452 1000;
BA_ "GenMsgCycleTime" BO_ 1453 1000;
BA_ "GenMsgCycleTime" BO_ 1455 1000;
BA_ "GenMsgCycleTime" BO_ 1454 1000;
BA_ "GenMsgCycleTime" BO_ 1456 1000;
BA_ "GenMsgCycleTime" BO_ 1458 1000;
BA_ "GenMsgCycleTime" BO_ 1457 1000;
BA_ "GenMsgCycleTime" BO_ 1459 1000;
BA_ "GenMsgCycleTime" BO_ 1460 1000;
BA_ "GenMsgCycleTime" BO_ 1461 1000;
BA_ "GenMsgCycleTime" BO_ 1462 1000;
BA_ "GenMsgCycleTime" BO_ 1463 1000;
BA_ "GenMsgCycleTime" BO_ 1885 1000;
BA_ "GenMsgCycleTime" BO_ 1439 1000;
BA_ "GenMsgCycleTime" BO_ 1180 1000;
BA_ "GenMsgCycleTime" BO_ 1244 1000;
BA_ "GenMsgCycleTime" BO_ 1440 1000;
BA_ "GenMsgCycleTime" BO_ 1503 1000;
BA_ "GenMsgCycleTime" BO_ 1509 1000;
BA_ "GenMsgCycleTime" BO_ 702 100;
BA_ "SignalLongName" SG_ 1199 DTCI_SRR_RR_DTCFailType "Diagnostic Trouble Code Information Extended - SRR_RR : Diagnostic Trouble Code Failure Type";
BA_ "SignalType" SG_ 1199 DTCI_SRR_RR_CnfrmdDTC "ENM";
BA_ "SignalLongName" SG_ 1199 DTCI_SRR_RR_CnfrmdDTC "Diagnostic Trouble Code Information Extended - SRR_RR : Confirmed DTC";
BA_ "SignalType" SG_ 1199 DTCI_SRR_RR_DTCFaultType "ENM";
BA_ "SignalLongName" SG_ 1199 DTCI_SRR_RR_DTCFaultType "Diagnostic Trouble Code Information Extended - SRR_RR : Diagnostic Trouble Code Fault Type";
BA_ "SignalLongName" SG_ 1199 DTCI_SRR_RR_DTCNumber "Diagnostic Trouble Code Information Extended - SRR_RR : Diagnostic Trouble Code Number";
BA_ "SignalLongName" SG_ 1199 DTCI_SRR_RR_DTCSource "Diagnostic Trouble Code Information Extended - SRR_RR : Diagnostic Trouble Code Source";
BA_ "SignalType" SG_ 1199 DTCI_SRR_RR_TstNCmpltdOpCyc "ENM";
BA_ "SignalLongName" SG_ 1199 DTCI_SRR_RR_TstNCmpltdOpCyc "Diagnostic Trouble Code Information Extended - SRR_RR : Test Not Completed This Operation Cycle";
BA_ "SignalType" SG_ 1199 DTCI_SRR_RR_TstNCmpltdLstClr "ENM";
BA_ "SignalLongName" SG_ 1199 DTCI_SRR_RR_TstNCmpltdLstClr "Diagnostic Trouble Code Information Extended - SRR_RR : Test Not Completed Since Last Clear";
BA_ "SignalType" SG_ 1199 DTCI_SRR_RR_TstFldOpCyc "ENM";
BA_ "SignalLongName" SG_ 1199 DTCI_SRR_RR_TstFldOpCyc "Diagnostic Trouble Code Information Extended - SRR_RR : Test Failed This Operation Cycle";
BA_ "SignalType" SG_ 1199 DTCI_SRR_RR_TstFldLstClr "ENM";
BA_ "SignalLongName" SG_ 1199 DTCI_SRR_RR_TstFldLstClr "Diagnostic Trouble Code Information Extended - SRR_RR : Test Failed Since Last Clear";
BA_ "SignalType" SG_ 1199 DTCI_SRR_RR_TstFld "ENM";
BA_ "SignalLongName" SG_ 1199 DTCI_SRR_RR_TstFld "Diagnostic Trouble Code Information Extended - SRR_RR : Test Failed";
BA_ "SignalType" SG_ 1199 DTCI_SRR_RR_PndngDTC "ENM";
BA_ "SignalLongName" SG_ 1199 DTCI_SRR_RR_PndngDTC "Diagnostic Trouble Code Information Extended - SRR_RR : Pending DTC";
BA_ "SignalType" SG_ 1199 DTCI_SRR_RR_DTCTriggered "ENM";
BA_ "SignalLongName" SG_ 1199 DTCI_SRR_RR_DTCTriggered "Diagnostic Trouble Code Information Extended - SRR_RR : Diagnostic Trouble Code Triggered";
BA_ "SignalType" SG_ 1199 DTCI_SRR_RR_WrnIndTrggrd "ENM";
BA_ "SignalLongName" SG_ 1199 DTCI_SRR_RR_WrnIndTrggrd "Diagnostic Trouble Code Information Extended - SRR_RR : Warning Indicator Triggered";
BA_ "SignalType" SG_ 1199 DTCI_SRR_RR_WrnIndRqd "ENM";
BA_ "SignalLongName" SG_ 1199 DTCI_SRR_RR_WrnIndRqd "Diagnostic Trouble Code Information Extended - SRR_RR : Warning Indicator Requested";
BA_ "SignalLongName" SG_ 1867 DTCI_SRR_SLR_DTCFailType "Diagnostic Trouble Code Information Extended - SRR_SLR : Diagnostic Trouble Code Failure Type";
BA_ "SignalType" SG_ 1867 DTCI_SRR_SLR_CnfrmdDTC "ENM";
BA_ "SignalLongName" SG_ 1867 DTCI_SRR_SLR_CnfrmdDTC "Diagnostic Trouble Code Information Extended - SRR_SLR : Confirmed DTC";
BA_ "SignalType" SG_ 1867 DTCI_SRR_SLR_DTCFaultType "ENM";
BA_ "SignalLongName" SG_ 1867 DTCI_SRR_SLR_DTCFaultType "Diagnostic Trouble Code Information Extended - SRR_SLR : Diagnostic Trouble Code Fault Type";
BA_ "SignalLongName" SG_ 1867 DTCI_SRR_SLR_DTCNumber "Diagnostic Trouble Code Information Extended - SRR_SLR : Diagnostic Trouble Code Number";
BA_ "SignalLongName" SG_ 1867 DTCI_SRR_SLR_DTCSource "Diagnostic Trouble Code Information Extended - SRR_SLR : Diagnostic Trouble Code Source";
BA_ "SignalType" SG_ 1867 DTCI_SRR_SLR_TstNCmpltdOpCyc "ENM";
BA_ "SignalLongName" SG_ 1867 DTCI_SRR_SLR_TstNCmpltdOpCyc "Diagnostic Trouble Code Information Extended - SRR_SLR : Test Not Completed This Operation Cycle";
BA_ "SignalType" SG_ 1867 DTCI_SRR_SLR_TstNCmpltdLstClr "ENM";
BA_ "SignalLongName" SG_ 1867 DTCI_SRR_SLR_TstNCmpltdLstClr "Diagnostic Trouble Code Information Extended - SRR_SLR : Test Not Completed Since Last Clear";
BA_ "SignalType" SG_ 1867 DTCI_SRR_SLR_TstFldOpCyc "ENM";
BA_ "SignalLongName" SG_ 1867 DTCI_SRR_SLR_TstFldOpCyc "Diagnostic Trouble Code Information Extended - SRR_SLR : Test Failed This Operation Cycle";
BA_ "SignalType" SG_ 1867 DTCI_SRR_SLR_TstFldLstClr "ENM";
BA_ "SignalLongName" SG_ 1867 DTCI_SRR_SLR_TstFldLstClr "Diagnostic Trouble Code Information Extended - SRR_SLR : Test Failed Since Last Clear";
BA_ "SignalType" SG_ 1867 DTCI_SRR_SLR_TstFld "ENM";
BA_ "SignalLongName" SG_ 1867 DTCI_SRR_SLR_TstFld "Diagnostic Trouble Code Information Extended - SRR_SLR : Test Failed";
BA_ "SignalType" SG_ 1867 DTCI_SRR_SLR_PndngDTC "ENM";
BA_ "SignalLongName" SG_ 1867 DTCI_SRR_SLR_PndngDTC "Diagnostic Trouble Code Information Extended - SRR_SLR : Pending DTC";
BA_ "SignalType" SG_ 1867 DTCI_SRR_SLR_DTCTriggered "ENM";
BA_ "SignalLongName" SG_ 1867 DTCI_SRR_SLR_DTCTriggered "Diagnostic Trouble Code Information Extended - SRR_SLR : Diagnostic Trouble Code Triggered";
BA_ "SignalType" SG_ 1867 DTCI_SRR_SLR_WrnIndTrggrd "ENM";
BA_ "SignalLongName" SG_ 1867 DTCI_SRR_SLR_WrnIndTrggrd "Diagnostic Trouble Code Information Extended - SRR_SLR : Warning Indicator Triggered";
BA_ "SignalType" SG_ 1867 DTCI_SRR_SLR_WrnIndRqd "ENM";
BA_ "SignalLongName" SG_ 1867 DTCI_SRR_SLR_WrnIndRqd "Diagnostic Trouble Code Information Extended - SRR_SLR : Warning Indicator Requested";
BA_ "SignalLongName" SG_ 1198 DTCI_SRR_SRR_DTCFailType "Diagnostic Trouble Code Information Extended - SRR_SRR : Diagnostic Trouble Code Failure Type";
BA_ "SignalType" SG_ 1198 DTCI_SRR_SRR_CnfrmdDTC "ENM";
BA_ "SignalLongName" SG_ 1198 DTCI_SRR_SRR_CnfrmdDTC "Diagnostic Trouble Code Information Extended - SRR_SRR : Confirmed DTC";
BA_ "SignalType" SG_ 1198 DTCI_SRR_SRR_DTCFaultType "ENM";
BA_ "SignalLongName" SG_ 1198 DTCI_SRR_SRR_DTCFaultType "Diagnostic Trouble Code Information Extended - SRR_SRR : Diagnostic Trouble Code Fault Type";
BA_ "SignalLongName" SG_ 1198 DTCI_SRR_SRR_DTCNumber "Diagnostic Trouble Code Information Extended - SRR_SRR : Diagnostic Trouble Code Number";
BA_ "SignalLongName" SG_ 1198 DTCI_SRR_SRR_DTCSource "Diagnostic Trouble Code Information Extended - SRR_SRR : Diagnostic Trouble Code Source";
BA_ "SignalType" SG_ 1198 DTCI_SRR_SRR_TstNCmpltdOpCyc "ENM";
BA_ "SignalLongName" SG_ 1198 DTCI_SRR_SRR_TstNCmpltdOpCyc "Diagnostic Trouble Code Information Extended - SRR_SRR : Test Not Completed This Operation Cycle";
BA_ "SignalType" SG_ 1198 DTCI_SRR_SRR_TstNCmpltdLstClr "ENM";
BA_ "SignalLongName" SG_ 1198 DTCI_SRR_SRR_TstNCmpltdLstClr "Diagnostic Trouble Code Information Extended - SRR_SRR : Test Not Completed Since Last Clear";
BA_ "SignalType" SG_ 1198 DTCI_SRR_SRR_TstFldOpCyc "ENM";
BA_ "SignalLongName" SG_ 1198 DTCI_SRR_SRR_TstFldOpCyc "Diagnostic Trouble Code Information Extended - SRR_SRR : Test Failed This Operation Cycle";
BA_ "SignalType" SG_ 1198 DTCI_SRR_SRR_TstFldLstClr "ENM";
BA_ "SignalLongName" SG_ 1198 DTCI_SRR_SRR_TstFldLstClr "Diagnostic Trouble Code Information Extended - SRR_SRR : Test Failed Since Last Clear";
BA_ "SignalType" SG_ 1198 DTCI_SRR_SRR_TstFld "ENM";
BA_ "SignalLongName" SG_ 1198 DTCI_SRR_SRR_TstFld "Diagnostic Trouble Code Information Extended - SRR_SRR : Test Failed";
BA_ "SignalType" SG_ 1198 DTCI_SRR_SRR_PndngDTC "ENM";
BA_ "SignalLongName" SG_ 1198 DTCI_SRR_SRR_PndngDTC "Diagnostic Trouble Code Information Extended - SRR_SRR : Pending DTC";
BA_ "SignalType" SG_ 1198 DTCI_SRR_SRR_DTCTriggered "ENM";
BA_ "SignalLongName" SG_ 1198 DTCI_SRR_SRR_DTCTriggered "Diagnostic Trouble Code Information Extended - SRR_SRR : Diagnostic Trouble Code Triggered";
BA_ "SignalType" SG_ 1198 DTCI_SRR_SRR_WrnIndTrggrd "ENM";
BA_ "SignalLongName" SG_ 1198 DTCI_SRR_SRR_WrnIndTrggrd "Diagnostic Trouble Code Information Extended - SRR_SRR : Warning Indicator Triggered";
BA_ "SignalType" SG_ 1198 DTCI_SRR_SRR_WrnIndRqd "ENM";
BA_ "SignalLongName" SG_ 1198 DTCI_SRR_SRR_WrnIndRqd "Diagnostic Trouble Code Information Extended - SRR_SRR : Warning Indicator Requested";
BA_ "SignalLongName" SG_ 1197 DTCI_TCCM_DTCFailType "Diagnostic Trouble Code Information Extended - TCCM : Diagnostic Trouble Code Failure Type";
BA_ "SignalType" SG_ 1197 DTCI_TCCM_CnfrmdDTC "ENM";
BA_ "SignalLongName" SG_ 1197 DTCI_TCCM_CnfrmdDTC "Diagnostic Trouble Code Information Extended - TCCM : Confirmed DTC";
BA_ "SignalType" SG_ 1197 DTCI_TCCM_DTCFaultType "ENM";
BA_ "SignalLongName" SG_ 1197 DTCI_TCCM_DTCFaultType "Diagnostic Trouble Code Information Extended - TCCM : Diagnostic Trouble Code Fault Type";
BA_ "SignalLongName" SG_ 1197 DTCI_TCCM_DTCNumber "Diagnostic Trouble Code Information Extended - TCCM : Diagnostic Trouble Code Number";
BA_ "SignalLongName" SG_ 1197 DTCI_TCCM_DTCSource "Diagnostic Trouble Code Information Extended - TCCM : Diagnostic Trouble Code Source";
BA_ "SignalType" SG_ 1197 DTCI_TCCM_TstNCmpltdOpCyc "ENM";
BA_ "SignalLongName" SG_ 1197 DTCI_TCCM_TstNCmpltdOpCyc "Diagnostic Trouble Code Information Extended - TCCM : Test Not Completed This Operation Cycle";
BA_ "SignalType" SG_ 1197 DTCI_TCCM_TstNCmpltdLstClr "ENM";
BA_ "SignalLongName" SG_ 1197 DTCI_TCCM_TstNCmpltdLstClr "Diagnostic Trouble Code Information Extended - TCCM : Test Not Completed Since Last Clear";
BA_ "SignalType" SG_ 1197 DTCI_TCCM_TstFldOpCyc "ENM";
BA_ "SignalLongName" SG_ 1197 DTCI_TCCM_TstFldOpCyc "Diagnostic Trouble Code Information Extended - TCCM : Test Failed This Operation Cycle";
BA_ "SignalType" SG_ 1197 DTCI_TCCM_TstFldLstClr "ENM";
BA_ "SignalLongName" SG_ 1197 DTCI_TCCM_TstFldLstClr "Diagnostic Trouble Code Information Extended - TCCM : Test Failed Since Last Clear";
BA_ "SignalType" SG_ 1197 DTCI_TCCM_TstFld "ENM";
BA_ "SignalLongName" SG_ 1197 DTCI_TCCM_TstFld "Diagnostic Trouble Code Information Extended - TCCM : Test Failed";
BA_ "SignalType" SG_ 1197 DTCI_TCCM_PndngDTC "ENM";
BA_ "SignalLongName" SG_ 1197 DTCI_TCCM_PndngDTC "Diagnostic Trouble Code Information Extended - TCCM : Pending DTC";
BA_ "SignalType" SG_ 1197 DTCI_TCCM_DTCTriggered "ENM";
BA_ "SignalLongName" SG_ 1197 DTCI_TCCM_DTCTriggered "Diagnostic Trouble Code Information Extended - TCCM : Diagnostic Trouble Code Triggered";
BA_ "SignalType" SG_ 1197 DTCI_TCCM_WrnIndTrggrd "ENM";
BA_ "SignalLongName" SG_ 1197 DTCI_TCCM_WrnIndTrggrd "Diagnostic Trouble Code Information Extended - TCCM : Warning Indicator Triggered";
BA_ "SignalType" SG_ 1197 DTCI_TCCM_WrnIndRqd "ENM";
BA_ "SignalLongName" SG_ 1197 DTCI_TCCM_WrnIndRqd "Diagnostic Trouble Code Information Extended - TCCM : Warning Indicator Requested";
BA_ "SignalLongName" SG_ 1869 DTCI_TCM_DTCFailType "Diagnostic Trouble Code Information Extended - TCM : Diagnostic Trouble Code Failure Type";
BA_ "SignalType" SG_ 1869 DTCI_TCM_CnfrmdDTC "ENM";
BA_ "SignalLongName" SG_ 1869 DTCI_TCM_CnfrmdDTC "Diagnostic Trouble Code Information Extended - TCM : Confirmed DTC";
BA_ "SignalType" SG_ 1869 DTCI_TCM_DTCFaultType "ENM";
BA_ "SignalLongName" SG_ 1869 DTCI_TCM_DTCFaultType "Diagnostic Trouble Code Information Extended - TCM : Diagnostic Trouble Code Fault Type";
BA_ "SignalLongName" SG_ 1869 DTCI_TCM_DTCNumber "Diagnostic Trouble Code Information Extended - TCM : Diagnostic Trouble Code Number";
BA_ "SignalLongName" SG_ 1869 DTCI_TCM_DTCSource "Diagnostic Trouble Code Information Extended - TCM : Diagnostic Trouble Code Source";
BA_ "SignalType" SG_ 1869 DTCI_TCM_TstNCmpltdOpCyc "ENM";
BA_ "SignalLongName" SG_ 1869 DTCI_TCM_TstNCmpltdOpCyc "Diagnostic Trouble Code Information Extended - TCM : Test Not Completed This Operation Cycle";
BA_ "SignalType" SG_ 1869 DTCI_TCM_TstNCmpltdLstClr "ENM";
BA_ "SignalLongName" SG_ 1869 DTCI_TCM_TstNCmpltdLstClr "Diagnostic Trouble Code Information Extended - TCM : Test Not Completed Since Last Clear";
BA_ "SignalType" SG_ 1869 DTCI_TCM_TstFldOpCyc "ENM";
BA_ "SignalLongName" SG_ 1869 DTCI_TCM_TstFldOpCyc "Diagnostic Trouble Code Information Extended - TCM : Test Failed This Operation Cycle";
BA_ "SignalType" SG_ 1869 DTCI_TCM_TstFldLstClr "ENM";
BA_ "SignalLongName" SG_ 1869 DTCI_TCM_TstFldLstClr "Diagnostic Trouble Code Information Extended - TCM : Test Failed Since Last Clear";
BA_ "SignalType" SG_ 1869 DTCI_TCM_TstFld "ENM";
BA_ "SignalLongName" SG_ 1869 DTCI_TCM_TstFld "Diagnostic Trouble Code Information Extended - TCM : Test Failed";
BA_ "SignalType" SG_ 1869 DTCI_TCM_PndngDTC "ENM";
BA_ "SignalLongName" SG_ 1869 DTCI_TCM_PndngDTC "Diagnostic Trouble Code Information Extended - TCM : Pending DTC";
BA_ "SignalType" SG_ 1869 DTCI_TCM_DTCTriggered "ENM";
BA_ "SignalLongName" SG_ 1869 DTCI_TCM_DTCTriggered "Diagnostic Trouble Code Information Extended - TCM : Diagnostic Trouble Code Triggered";
BA_ "SignalType" SG_ 1869 DTCI_TCM_WrnIndTrggrd "ENM";
BA_ "SignalLongName" SG_ 1869 DTCI_TCM_WrnIndTrggrd "Diagnostic Trouble Code Information Extended - TCM : Warning Indicator Triggered";
BA_ "SignalType" SG_ 1869 DTCI_TCM_WrnIndRqd "ENM";
BA_ "SignalLongName" SG_ 1869 DTCI_TCM_WrnIndRqd "Diagnostic Trouble Code Information Extended - TCM : Warning Indicator Requested";
BA_ "SignalLongName" SG_ 1196 DTCI_TCP_DTCFailType "Diagnostic Trouble Code Information Extended - TCP : Diagnostic Trouble Code Failure Type";
BA_ "SignalType" SG_ 1196 DTCI_TCP_CnfrmdDTC "ENM";
BA_ "SignalLongName" SG_ 1196 DTCI_TCP_CnfrmdDTC "Diagnostic Trouble Code Information Extended - TCP : Confirmed DTC";
BA_ "SignalType" SG_ 1196 DTCI_TCP_DTCFaultType "ENM";
BA_ "SignalLongName" SG_ 1196 DTCI_TCP_DTCFaultType "Diagnostic Trouble Code Information Extended - TCP : Diagnostic Trouble Code Fault Type";
BA_ "SignalLongName" SG_ 1196 DTCI_TCP_DTCNumber "Diagnostic Trouble Code Information Extended - TCP : Diagnostic Trouble Code Number";
BA_ "SignalLongName" SG_ 1196 DTCI_TCP_DTCSource "Diagnostic Trouble Code Information Extended - TCP : Diagnostic Trouble Code Source";
BA_ "SignalType" SG_ 1196 DTCI_TCP_TstNCmpltdOpCyc "ENM";
BA_ "SignalLongName" SG_ 1196 DTCI_TCP_TstNCmpltdOpCyc "Diagnostic Trouble Code Information Extended - TCP : Test Not Completed This Operation Cycle";
BA_ "SignalType" SG_ 1196 DTCI_TCP_TstNCmpltdLstClr "ENM";
BA_ "SignalLongName" SG_ 1196 DTCI_TCP_TstNCmpltdLstClr "Diagnostic Trouble Code Information Extended - TCP : Test Not Completed Since Last Clear";
BA_ "SignalType" SG_ 1196 DTCI_TCP_TstFldOpCyc "ENM";
BA_ "SignalLongName" SG_ 1196 DTCI_TCP_TstFldOpCyc "Diagnostic Trouble Code Information Extended - TCP : Test Failed This Operation Cycle";
BA_ "SignalType" SG_ 1196 DTCI_TCP_TstFldLstClr "ENM";
BA_ "SignalLongName" SG_ 1196 DTCI_TCP_TstFldLstClr "Diagnostic Trouble Code Information Extended - TCP : Test Failed Since Last Clear";
BA_ "SignalType" SG_ 1196 DTCI_TCP_TstFld "ENM";
BA_ "SignalLongName" SG_ 1196 DTCI_TCP_TstFld "Diagnostic Trouble Code Information Extended - TCP : Test Failed";
BA_ "SignalType" SG_ 1196 DTCI_TCP_PndngDTC "ENM";
BA_ "SignalLongName" SG_ 1196 DTCI_TCP_PndngDTC "Diagnostic Trouble Code Information Extended - TCP : Pending DTC";
BA_ "SignalType" SG_ 1196 DTCI_TCP_DTCTriggered "ENM";
BA_ "SignalLongName" SG_ 1196 DTCI_TCP_DTCTriggered "Diagnostic Trouble Code Information Extended - TCP : Diagnostic Trouble Code Triggered";
BA_ "SignalType" SG_ 1196 DTCI_TCP_WrnIndTrggrd "ENM";
BA_ "SignalLongName" SG_ 1196 DTCI_TCP_WrnIndTrggrd "Diagnostic Trouble Code Information Extended - TCP : Warning Indicator Triggered";
BA_ "SignalType" SG_ 1196 DTCI_TCP_WrnIndRqd "ENM";
BA_ "SignalLongName" SG_ 1196 DTCI_TCP_WrnIndRqd "Diagnostic Trouble Code Information Extended - TCP : Warning Indicator Requested";
BA_ "SignalLongName" SG_ 1870 DTCI_TIM_DTCFailType "Diagnostic Trouble Code Information Extended - TIM : Diagnostic Trouble Code Failure Type";
BA_ "SignalType" SG_ 1870 DTCI_TIM_CnfrmdDTC "ENM";
BA_ "SignalLongName" SG_ 1870 DTCI_TIM_CnfrmdDTC "Diagnostic Trouble Code Information Extended - TIM : Confirmed DTC";
BA_ "SignalType" SG_ 1870 DTCI_TIM_DTCFaultType "ENM";
BA_ "SignalLongName" SG_ 1870 DTCI_TIM_DTCFaultType "Diagnostic Trouble Code Information Extended - TIM : Diagnostic Trouble Code Fault Type";
BA_ "SignalLongName" SG_ 1870 DTCI_TIM_DTCNumber "Diagnostic Trouble Code Information Extended - TIM : Diagnostic Trouble Code Number";
BA_ "SignalLongName" SG_ 1870 DTCI_TIM_DTCSource "Diagnostic Trouble Code Information Extended - TIM : Diagnostic Trouble Code Source";
BA_ "SignalType" SG_ 1870 DTCI_TIM_TstNCmpltdOpCyc "ENM";
BA_ "SignalLongName" SG_ 1870 DTCI_TIM_TstNCmpltdOpCyc "Diagnostic Trouble Code Information Extended - TIM : Test Not Completed This Operation Cycle";
BA_ "SignalType" SG_ 1870 DTCI_TIM_TstNCmpltdLstClr "ENM";
BA_ "SignalLongName" SG_ 1870 DTCI_TIM_TstNCmpltdLstClr "Diagnostic Trouble Code Information Extended - TIM : Test Not Completed Since Last Clear";
BA_ "SignalType" SG_ 1870 DTCI_TIM_TstFldOpCyc "ENM";
BA_ "SignalLongName" SG_ 1870 DTCI_TIM_TstFldOpCyc "Diagnostic Trouble Code Information Extended - TIM : Test Failed This Operation Cycle";
BA_ "SignalType" SG_ 1870 DTCI_TIM_TstFldLstClr "ENM";
BA_ "SignalLongName" SG_ 1870 DTCI_TIM_TstFldLstClr "Diagnostic Trouble Code Information Extended - TIM : Test Failed Since Last Clear";
BA_ "SignalType" SG_ 1870 DTCI_TIM_TstFld "ENM";
BA_ "SignalLongName" SG_ 1870 DTCI_TIM_TstFld "Diagnostic Trouble Code Information Extended - TIM : Test Failed";
BA_ "SignalType" SG_ 1870 DTCI_TIM_PndngDTC "ENM";
BA_ "SignalLongName" SG_ 1870 DTCI_TIM_PndngDTC "Diagnostic Trouble Code Information Extended - TIM : Pending DTC";
BA_ "SignalType" SG_ 1870 DTCI_TIM_DTCTriggered "ENM";
BA_ "SignalLongName" SG_ 1870 DTCI_TIM_DTCTriggered "Diagnostic Trouble Code Information Extended - TIM : Diagnostic Trouble Code Triggered";
BA_ "SignalType" SG_ 1870 DTCI_TIM_WrnIndTrggrd "ENM";
BA_ "SignalLongName" SG_ 1870 DTCI_TIM_WrnIndTrggrd "Diagnostic Trouble Code Information Extended - TIM : Warning Indicator Triggered";
BA_ "SignalType" SG_ 1870 DTCI_TIM_WrnIndRqd "ENM";
BA_ "SignalLongName" SG_ 1870 DTCI_TIM_WrnIndRqd "Diagnostic Trouble Code Information Extended - TIM : Warning Indicator Requested";
BA_ "SignalLongName" SG_ 1902 DTCI_UPM_DTCFailType "Diagnostic Trouble Code Information Extended - UPM : Diagnostic Trouble Code Failure Type";
BA_ "SignalType" SG_ 1902 DTCI_UPM_CnfrmdDTC "ENM";
BA_ "SignalLongName" SG_ 1902 DTCI_UPM_CnfrmdDTC "Diagnostic Trouble Code Information Extended - UPM : Confirmed DTC";
BA_ "SignalType" SG_ 1902 DTCI_UPM_DTCFaultType "ENM";
BA_ "SignalLongName" SG_ 1902 DTCI_UPM_DTCFaultType "Diagnostic Trouble Code Information Extended - UPM : Diagnostic Trouble Code Fault Type";
BA_ "SignalLongName" SG_ 1902 DTCI_UPM_DTCNumber "Diagnostic Trouble Code Information Extended - UPM : Diagnostic Trouble Code Number";
BA_ "SignalLongName" SG_ 1902 DTCI_UPM_DTCSource "Diagnostic Trouble Code Information Extended - UPM : Diagnostic Trouble Code Source";
BA_ "SignalType" SG_ 1902 DTCI_UPM_TstNCmpltdOpCyc "ENM";
BA_ "SignalLongName" SG_ 1902 DTCI_UPM_TstNCmpltdOpCyc "Diagnostic Trouble Code Information Extended - UPM : Test Not Completed This Operation Cycle";
BA_ "SignalType" SG_ 1902 DTCI_UPM_TstNCmpltdLstClr "ENM";
BA_ "SignalLongName" SG_ 1902 DTCI_UPM_TstNCmpltdLstClr "Diagnostic Trouble Code Information Extended - UPM : Test Not Completed Since Last Clear";
BA_ "SignalType" SG_ 1902 DTCI_UPM_TstFldOpCyc "ENM";
BA_ "SignalLongName" SG_ 1902 DTCI_UPM_TstFldOpCyc "Diagnostic Trouble Code Information Extended - UPM : Test Failed This Operation Cycle";
BA_ "SignalType" SG_ 1902 DTCI_UPM_TstFldLstClr "ENM";
BA_ "SignalLongName" SG_ 1902 DTCI_UPM_TstFldLstClr "Diagnostic Trouble Code Information Extended - UPM : Test Failed Since Last Clear";
BA_ "SignalType" SG_ 1902 DTCI_UPM_TstFld "ENM";
BA_ "SignalLongName" SG_ 1902 DTCI_UPM_TstFld "Diagnostic Trouble Code Information Extended - UPM : Test Failed";
BA_ "SignalType" SG_ 1902 DTCI_UPM_PndngDTC "ENM";
BA_ "SignalLongName" SG_ 1902 DTCI_UPM_PndngDTC "Diagnostic Trouble Code Information Extended - UPM : Pending DTC";
BA_ "SignalType" SG_ 1902 DTCI_UPM_DTCTriggered "ENM";
BA_ "SignalLongName" SG_ 1902 DTCI_UPM_DTCTriggered "Diagnostic Trouble Code Information Extended - UPM : Diagnostic Trouble Code Triggered";
BA_ "SignalType" SG_ 1902 DTCI_UPM_WrnIndTrggrd "ENM";
BA_ "SignalLongName" SG_ 1902 DTCI_UPM_WrnIndTrggrd "Diagnostic Trouble Code Information Extended - UPM : Warning Indicator Triggered";
BA_ "SignalType" SG_ 1902 DTCI_UPM_WrnIndRqd "ENM";
BA_ "SignalLongName" SG_ 1902 DTCI_UPM_WrnIndRqd "Diagnostic Trouble Code Information Extended - UPM : Warning Indicator Requested";
BA_ "SignalLongName" SG_ 1904 DTCI_UVM_DTCFailType "Diagnostic Trouble Code Information Extended - UVM : Diagnostic Trouble Code Failure Type";
BA_ "SignalType" SG_ 1904 DTCI_UVM_CnfrmdDTC "ENM";
BA_ "SignalLongName" SG_ 1904 DTCI_UVM_CnfrmdDTC "Diagnostic Trouble Code Information Extended - UVM : Confirmed DTC";
BA_ "SignalType" SG_ 1904 DTCI_UVM_DTCFaultType "ENM";
BA_ "SignalLongName" SG_ 1904 DTCI_UVM_DTCFaultType "Diagnostic Trouble Code Information Extended - UVM : Diagnostic Trouble Code Fault Type";
BA_ "SignalLongName" SG_ 1904 DTCI_UVM_DTCNumber "Diagnostic Trouble Code Information Extended - UVM : Diagnostic Trouble Code Number";
BA_ "SignalLongName" SG_ 1904 DTCI_UVM_DTCSource "Diagnostic Trouble Code Information Extended - UVM : Diagnostic Trouble Code Source";
BA_ "SignalType" SG_ 1904 DTCI_UVM_TstNCmpltdOpCyc "ENM";
BA_ "SignalLongName" SG_ 1904 DTCI_UVM_TstNCmpltdOpCyc "Diagnostic Trouble Code Information Extended - UVM : Test Not Completed This Operation Cycle";
BA_ "SignalType" SG_ 1904 DTCI_UVM_TstNCmpltdLstClr "ENM";
BA_ "SignalLongName" SG_ 1904 DTCI_UVM_TstNCmpltdLstClr "Diagnostic Trouble Code Information Extended - UVM : Test Not Completed Since Last Clear";
BA_ "SignalType" SG_ 1904 DTCI_UVM_TstFldOpCyc "ENM";
BA_ "SignalLongName" SG_ 1904 DTCI_UVM_TstFldOpCyc "Diagnostic Trouble Code Information Extended - UVM : Test Failed This Operation Cycle";
BA_ "SignalType" SG_ 1904 DTCI_UVM_TstFldLstClr "ENM";
BA_ "SignalLongName" SG_ 1904 DTCI_UVM_TstFldLstClr "Diagnostic Trouble Code Information Extended - UVM : Test Failed Since Last Clear";
BA_ "SignalType" SG_ 1904 DTCI_UVM_TstFld "ENM";
BA_ "SignalLongName" SG_ 1904 DTCI_UVM_TstFld "Diagnostic Trouble Code Information Extended - UVM : Test Failed";
BA_ "SignalType" SG_ 1904 DTCI_UVM_PndngDTC "ENM";
BA_ "SignalLongName" SG_ 1904 DTCI_UVM_PndngDTC "Diagnostic Trouble Code Information Extended - UVM : Pending DTC";
BA_ "SignalType" SG_ 1904 DTCI_UVM_DTCTriggered "ENM";
BA_ "SignalLongName" SG_ 1904 DTCI_UVM_DTCTriggered "Diagnostic Trouble Code Information Extended - UVM : Diagnostic Trouble Code Triggered";
BA_ "SignalType" SG_ 1904 DTCI_UVM_WrnIndTrggrd "ENM";
BA_ "SignalLongName" SG_ 1904 DTCI_UVM_WrnIndTrggrd "Diagnostic Trouble Code Information Extended - UVM : Warning Indicator Triggered";
BA_ "SignalType" SG_ 1904 DTCI_UVM_WrnIndRqd "ENM";
BA_ "SignalLongName" SG_ 1904 DTCI_UVM_WrnIndRqd "Diagnostic Trouble Code Information Extended - UVM : Warning Indicator Requested";
BA_ "SignalLongName" SG_ 1195 DTCI_VCU_DTCFailType "Diagnostic Trouble Code Information Extended - VCU : Diagnostic Trouble Code Failure Type";
BA_ "SignalType" SG_ 1195 DTCI_VCU_CnfrmdDTC "ENM";
BA_ "SignalLongName" SG_ 1195 DTCI_VCU_CnfrmdDTC "Diagnostic Trouble Code Information Extended - VCU : Confirmed DTC";
BA_ "SignalType" SG_ 1195 DTCI_VCU_DTCFaultType "ENM";
BA_ "SignalLongName" SG_ 1195 DTCI_VCU_DTCFaultType "Diagnostic Trouble Code Information Extended - VCU : Diagnostic Trouble Code Fault Type";
BA_ "SignalLongName" SG_ 1195 DTCI_VCU_DTCNumber "Diagnostic Trouble Code Information Extended - VCU : Diagnostic Trouble Code Number";
BA_ "SignalLongName" SG_ 1195 DTCI_VCU_DTCSource "Diagnostic Trouble Code Information Extended - VCU : Diagnostic Trouble Code Source";
BA_ "SignalType" SG_ 1195 DTCI_VCU_TstNCmpltdOpCyc "ENM";
BA_ "SignalLongName" SG_ 1195 DTCI_VCU_TstNCmpltdOpCyc "Diagnostic Trouble Code Information Extended - VCU : Test Not Completed This Operation Cycle";
BA_ "SignalType" SG_ 1195 DTCI_VCU_TstNCmpltdLstClr "ENM";
BA_ "SignalLongName" SG_ 1195 DTCI_VCU_TstNCmpltdLstClr "Diagnostic Trouble Code Information Extended - VCU : Test Not Completed Since Last Clear";
BA_ "SignalType" SG_ 1195 DTCI_VCU_TstFldOpCyc "ENM";
BA_ "SignalLongName" SG_ 1195 DTCI_VCU_TstFldOpCyc "Diagnostic Trouble Code Information Extended - VCU : Test Failed This Operation Cycle";
BA_ "SignalType" SG_ 1195 DTCI_VCU_TstFldLstClr "ENM";
BA_ "SignalLongName" SG_ 1195 DTCI_VCU_TstFldLstClr "Diagnostic Trouble Code Information Extended - VCU : Test Failed Since Last Clear";
BA_ "SignalType" SG_ 1195 DTCI_VCU_TstFld "ENM";
BA_ "SignalLongName" SG_ 1195 DTCI_VCU_TstFld "Diagnostic Trouble Code Information Extended - VCU : Test Failed";
BA_ "SignalType" SG_ 1195 DTCI_VCU_PndngDTC "ENM";
BA_ "SignalLongName" SG_ 1195 DTCI_VCU_PndngDTC "Diagnostic Trouble Code Information Extended - VCU : Pending DTC";
BA_ "SignalType" SG_ 1195 DTCI_VCU_DTCTriggered "ENM";
BA_ "SignalLongName" SG_ 1195 DTCI_VCU_DTCTriggered "Diagnostic Trouble Code Information Extended - VCU : Diagnostic Trouble Code Triggered";
BA_ "SignalType" SG_ 1195 DTCI_VCU_WrnIndTrggrd "ENM";
BA_ "SignalLongName" SG_ 1195 DTCI_VCU_WrnIndTrggrd "Diagnostic Trouble Code Information Extended - VCU : Warning Indicator Triggered";
BA_ "SignalType" SG_ 1195 DTCI_VCU_WrnIndRqd "ENM";
BA_ "SignalLongName" SG_ 1195 DTCI_VCU_WrnIndRqd "Diagnostic Trouble Code Information Extended - VCU : Warning Indicator Requested";
BA_ "SignalLongName" SG_ 1175 DTCI_VDM_DTCFailType "Diagnostic Trouble Code Information Extended - VDM : Diagnostic Trouble Code Failure Type";
BA_ "SignalType" SG_ 1175 DTCI_VDM_CnfrmdDTC "ENM";
BA_ "SignalLongName" SG_ 1175 DTCI_VDM_CnfrmdDTC "Diagnostic Trouble Code Information Extended - VDM : Confirmed DTC";
BA_ "SignalType" SG_ 1175 DTCI_VDM_DTCFaultType "ENM";
BA_ "SignalLongName" SG_ 1175 DTCI_VDM_DTCFaultType "Diagnostic Trouble Code Information Extended - VDM : Diagnostic Trouble Code Fault Type";
BA_ "SignalLongName" SG_ 1175 DTCI_VDM_DTCNumber "Diagnostic Trouble Code Information Extended - VDM : Diagnostic Trouble Code Number";
BA_ "SignalLongName" SG_ 1175 DTCI_VDM_DTCSource "Diagnostic Trouble Code Information Extended - VDM : Diagnostic Trouble Code Source";
BA_ "SignalType" SG_ 1175 DTCI_VDM_TstNCmpltdOpCyc "ENM";
BA_ "SignalLongName" SG_ 1175 DTCI_VDM_TstNCmpltdOpCyc "Diagnostic Trouble Code Information Extended - VDM : Test Not Completed This Operation Cycle";
BA_ "SignalType" SG_ 1175 DTCI_VDM_TstNCmpltdLstClr "ENM";
BA_ "SignalLongName" SG_ 1175 DTCI_VDM_TstNCmpltdLstClr "Diagnostic Trouble Code Information Extended - VDM : Test Not Completed Since Last Clear";
BA_ "SignalType" SG_ 1175 DTCI_VDM_TstFldOpCyc "ENM";
BA_ "SignalLongName" SG_ 1175 DTCI_VDM_TstFldOpCyc "Diagnostic Trouble Code Information Extended - VDM : Test Failed This Operation Cycle";
BA_ "SignalType" SG_ 1175 DTCI_VDM_TstFldLstClr "ENM";
BA_ "SignalLongName" SG_ 1175 DTCI_VDM_TstFldLstClr "Diagnostic Trouble Code Information Extended - VDM : Test Failed Since Last Clear";
BA_ "SignalType" SG_ 1175 DTCI_VDM_TstFld "ENM";
BA_ "SignalLongName" SG_ 1175 DTCI_VDM_TstFld "Diagnostic Trouble Code Information Extended - VDM : Test Failed";
BA_ "SignalType" SG_ 1175 DTCI_VDM_PndngDTC "ENM";
BA_ "SignalLongName" SG_ 1175 DTCI_VDM_PndngDTC "Diagnostic Trouble Code Information Extended - VDM : Pending DTC";
BA_ "SignalType" SG_ 1175 DTCI_VDM_DTCTriggered "ENM";
BA_ "SignalLongName" SG_ 1175 DTCI_VDM_DTCTriggered "Diagnostic Trouble Code Information Extended - VDM : Diagnostic Trouble Code Triggered";
BA_ "SignalType" SG_ 1175 DTCI_VDM_WrnIndTrggrd "ENM";
BA_ "SignalLongName" SG_ 1175 DTCI_VDM_WrnIndTrggrd "Diagnostic Trouble Code Information Extended - VDM : Warning Indicator Triggered";
BA_ "SignalType" SG_ 1175 DTCI_VDM_WrnIndRqd "ENM";
BA_ "SignalLongName" SG_ 1175 DTCI_VDM_WrnIndRqd "Diagnostic Trouble Code Information Extended - VDM : Warning Indicator Requested";
BA_ "SignalLongName" SG_ 1891 DTCI_VECM_DTCFailType "Diagnostic Trouble Code Information Extended - VECM : Diagnostic Trouble Code Failure Type";
BA_ "SignalType" SG_ 1891 DTCI_VECM_CnfrmdDTC "ENM";
BA_ "SignalLongName" SG_ 1891 DTCI_VECM_CnfrmdDTC "Diagnostic Trouble Code Information Extended - VECM : Confirmed DTC";
BA_ "SignalType" SG_ 1891 DTCI_VECM_DTCFaultType "ENM";
BA_ "SignalLongName" SG_ 1891 DTCI_VECM_DTCFaultType "Diagnostic Trouble Code Information Extended - VECM : Diagnostic Trouble Code Fault Type";
BA_ "SignalLongName" SG_ 1891 DTCI_VECM_DTCNumber "Diagnostic Trouble Code Information Extended - VECM : Diagnostic Trouble Code Number";
BA_ "SignalLongName" SG_ 1891 DTCI_VECM_DTCSource "Diagnostic Trouble Code Information Extended - VECM : Diagnostic Trouble Code Source";
BA_ "SignalType" SG_ 1891 DTCI_VECM_TstNCmpltdOpCyc "ENM";
BA_ "SignalLongName" SG_ 1891 DTCI_VECM_TstNCmpltdOpCyc "Diagnostic Trouble Code Information Extended - VECM : Test Not Completed This Operation Cycle";
BA_ "SignalType" SG_ 1891 DTCI_VECM_TstNCmpltdLstClr "ENM";
BA_ "SignalLongName" SG_ 1891 DTCI_VECM_TstNCmpltdLstClr "Diagnostic Trouble Code Information Extended - VECM : Test Not Completed Since Last Clear";
BA_ "SignalType" SG_ 1891 DTCI_VECM_TstFldOpCyc "ENM";
BA_ "SignalLongName" SG_ 1891 DTCI_VECM_TstFldOpCyc "Diagnostic Trouble Code Information Extended - VECM : Test Failed This Operation Cycle";
BA_ "SignalType" SG_ 1891 DTCI_VECM_TstFldLstClr "ENM";
BA_ "SignalLongName" SG_ 1891 DTCI_VECM_TstFldLstClr "Diagnostic Trouble Code Information Extended - VECM : Test Failed Since Last Clear";
BA_ "SignalType" SG_ 1891 DTCI_VECM_TstFld "ENM";
BA_ "SignalLongName" SG_ 1891 DTCI_VECM_TstFld "Diagnostic Trouble Code Information Extended - VECM : Test Failed";
BA_ "SignalType" SG_ 1891 DTCI_VECM_PndngDTC "ENM";
BA_ "SignalLongName" SG_ 1891 DTCI_VECM_PndngDTC "Diagnostic Trouble Code Information Extended - VECM : Pending DTC";
BA_ "SignalType" SG_ 1891 DTCI_VECM_DTCTriggered "ENM";
BA_ "SignalLongName" SG_ 1891 DTCI_VECM_DTCTriggered "Diagnostic Trouble Code Information Extended - VECM : Diagnostic Trouble Code Triggered";
BA_ "SignalType" SG_ 1891 DTCI_VECM_WrnIndTrggrd "ENM";
BA_ "SignalLongName" SG_ 1891 DTCI_VECM_WrnIndTrggrd "Diagnostic Trouble Code Information Extended - VECM : Warning Indicator Triggered";
BA_ "SignalType" SG_ 1891 DTCI_VECM_WrnIndRqd "ENM";
BA_ "SignalLongName" SG_ 1891 DTCI_VECM_WrnIndRqd "Diagnostic Trouble Code Information Extended - VECM : Warning Indicator Requested";
BA_ "SignalLongName" SG_ 1871 DTCI_VICM_DTCFailType "Diagnostic Trouble Code Information Extended - VICM : Diagnostic Trouble Code Failure Type";
BA_ "SignalType" SG_ 1871 DTCI_VICM_CnfrmdDTC "ENM";
BA_ "SignalLongName" SG_ 1871 DTCI_VICM_CnfrmdDTC "Diagnostic Trouble Code Information Extended - VICM : Confirmed DTC";
BA_ "SignalType" SG_ 1871 DTCI_VICM_DTCFaultType "ENM";
BA_ "SignalLongName" SG_ 1871 DTCI_VICM_DTCFaultType "Diagnostic Trouble Code Information Extended - VICM : Diagnostic Trouble Code Fault Type";
BA_ "SignalLongName" SG_ 1871 DTCI_VICM_DTCNumber "Diagnostic Trouble Code Information Extended - VICM : Diagnostic Trouble Code Number";
BA_ "SignalLongName" SG_ 1871 DTCI_VICM_DTCSource "Diagnostic Trouble Code Information Extended - VICM : Diagnostic Trouble Code Source";
BA_ "SignalType" SG_ 1871 DTCI_VICM_TstNCmpltdOpCyc "ENM";
BA_ "SignalLongName" SG_ 1871 DTCI_VICM_TstNCmpltdOpCyc "Diagnostic Trouble Code Information Extended - VICM : Test Not Completed This Operation Cycle";
BA_ "SignalType" SG_ 1871 DTCI_VICM_TstNCmpltdLstClr "ENM";
BA_ "SignalLongName" SG_ 1871 DTCI_VICM_TstNCmpltdLstClr "Diagnostic Trouble Code Information Extended - VICM : Test Not Completed Since Last Clear";
BA_ "SignalType" SG_ 1871 DTCI_VICM_TstFldOpCyc "ENM";
BA_ "SignalLongName" SG_ 1871 DTCI_VICM_TstFldOpCyc "Diagnostic Trouble Code Information Extended - VICM : Test Failed This Operation Cycle";
BA_ "SignalType" SG_ 1871 DTCI_VICM_TstFldLstClr "ENM";
BA_ "SignalLongName" SG_ 1871 DTCI_VICM_TstFldLstClr "Diagnostic Trouble Code Information Extended - VICM : Test Failed Since Last Clear";
BA_ "SignalType" SG_ 1871 DTCI_VICM_TstFld "ENM";
BA_ "SignalLongName" SG_ 1871 DTCI_VICM_TstFld "Diagnostic Trouble Code Information Extended - VICM : Test Failed";
BA_ "SignalType" SG_ 1871 DTCI_VICM_PndngDTC "ENM";
BA_ "SignalLongName" SG_ 1871 DTCI_VICM_PndngDTC "Diagnostic Trouble Code Information Extended - VICM : Pending DTC";
BA_ "SignalType" SG_ 1871 DTCI_VICM_DTCTriggered "ENM";
BA_ "SignalLongName" SG_ 1871 DTCI_VICM_DTCTriggered "Diagnostic Trouble Code Information Extended - VICM : Diagnostic Trouble Code Triggered";
BA_ "SignalType" SG_ 1871 DTCI_VICM_WrnIndTrggrd "ENM";
BA_ "SignalLongName" SG_ 1871 DTCI_VICM_WrnIndTrggrd "Diagnostic Trouble Code Information Extended - VICM : Warning Indicator Triggered";
BA_ "SignalType" SG_ 1871 DTCI_VICM_WrnIndRqd "ENM";
BA_ "SignalLongName" SG_ 1871 DTCI_VICM_WrnIndRqd "Diagnostic Trouble Code Information Extended - VICM : Warning Indicator Requested";
BA_ "SignalLongName" SG_ 1194 DTCI_VKM_DTCFailType "Diagnostic Trouble Code Information Extended - VKM : Diagnostic Trouble Code Failure Type";
BA_ "SignalType" SG_ 1194 DTCI_VKM_CnfrmdDTC "ENM";
BA_ "SignalLongName" SG_ 1194 DTCI_VKM_CnfrmdDTC "Diagnostic Trouble Code Information Extended - VKM : Confirmed DTC";
BA_ "SignalType" SG_ 1194 DTCI_VKM_DTCFaultType "ENM";
BA_ "SignalLongName" SG_ 1194 DTCI_VKM_DTCFaultType "Diagnostic Trouble Code Information Extended - VKM : Diagnostic Trouble Code Fault Type";
BA_ "SignalLongName" SG_ 1194 DTCI_VKM_DTCNumber "Diagnostic Trouble Code Information Extended - VKM : Diagnostic Trouble Code Number";
BA_ "SignalLongName" SG_ 1194 DTCI_VKM_DTCSource "Diagnostic Trouble Code Information Extended - VKM : Diagnostic Trouble Code Source";
BA_ "SignalType" SG_ 1194 DTCI_VKM_TstNCmpltdOpCyc "ENM";
BA_ "SignalLongName" SG_ 1194 DTCI_VKM_TstNCmpltdOpCyc "Diagnostic Trouble Code Information Extended - VKM : Test Not Completed This Operation Cycle";
BA_ "SignalType" SG_ 1194 DTCI_VKM_TstNCmpltdLstClr "ENM";
BA_ "SignalLongName" SG_ 1194 DTCI_VKM_TstNCmpltdLstClr "Diagnostic Trouble Code Information Extended - VKM : Test Not Completed Since Last Clear";
BA_ "SignalType" SG_ 1194 DTCI_VKM_TstFldOpCyc "ENM";
BA_ "SignalLongName" SG_ 1194 DTCI_VKM_TstFldOpCyc "Diagnostic Trouble Code Information Extended - VKM : Test Failed This Operation Cycle";
BA_ "SignalType" SG_ 1194 DTCI_VKM_TstFldLstClr "ENM";
BA_ "SignalLongName" SG_ 1194 DTCI_VKM_TstFldLstClr "Diagnostic Trouble Code Information Extended - VKM : Test Failed Since Last Clear";
BA_ "SignalType" SG_ 1194 DTCI_VKM_TstFld "ENM";
BA_ "SignalLongName" SG_ 1194 DTCI_VKM_TstFld "Diagnostic Trouble Code Information Extended - VKM : Test Failed";
BA_ "SignalType" SG_ 1194 DTCI_VKM_PndngDTC "ENM";
BA_ "SignalLongName" SG_ 1194 DTCI_VKM_PndngDTC "Diagnostic Trouble Code Information Extended - VKM : Pending DTC";
BA_ "SignalType" SG_ 1194 DTCI_VKM_DTCTriggered "ENM";
BA_ "SignalLongName" SG_ 1194 DTCI_VKM_DTCTriggered "Diagnostic Trouble Code Information Extended - VKM : Diagnostic Trouble Code Triggered";
BA_ "SignalType" SG_ 1194 DTCI_VKM_WrnIndTrggrd "ENM";
BA_ "SignalLongName" SG_ 1194 DTCI_VKM_WrnIndTrggrd "Diagnostic Trouble Code Information Extended - VKM : Warning Indicator Triggered";
BA_ "SignalType" SG_ 1194 DTCI_VKM_WrnIndRqd "ENM";
BA_ "SignalLongName" SG_ 1194 DTCI_VKM_WrnIndRqd "Diagnostic Trouble Code Information Extended - VKM : Warning Indicator Requested";
BA_ "SignalLongName" SG_ 1872 DTCI_VLM_DTCFailType "Diagnostic Trouble Code Information Extended - VLM : Diagnostic Trouble Code Failure Type";
BA_ "SignalType" SG_ 1872 DTCI_VLM_CnfrmdDTC "ENM";
BA_ "SignalLongName" SG_ 1872 DTCI_VLM_CnfrmdDTC "Diagnostic Trouble Code Information Extended - VLM : Confirmed DTC";
BA_ "SignalType" SG_ 1872 DTCI_VLM_DTCFaultType "ENM";
BA_ "SignalLongName" SG_ 1872 DTCI_VLM_DTCFaultType "Diagnostic Trouble Code Information Extended - VLM : Diagnostic Trouble Code Fault Type";
BA_ "SignalLongName" SG_ 1872 DTCI_VLM_DTCNumber "Diagnostic Trouble Code Information Extended - VLM : Diagnostic Trouble Code Number";
BA_ "SignalLongName" SG_ 1872 DTCI_VLM_DTCSource "Diagnostic Trouble Code Information Extended - VLM : Diagnostic Trouble Code Source";
BA_ "SignalType" SG_ 1872 DTCI_VLM_TstNCmpltdOpCyc "ENM";
BA_ "SignalLongName" SG_ 1872 DTCI_VLM_TstNCmpltdOpCyc "Diagnostic Trouble Code Information Extended - VLM : Test Not Completed This Operation Cycle";
BA_ "SignalType" SG_ 1872 DTCI_VLM_TstNCmpltdLstClr "ENM";
BA_ "SignalLongName" SG_ 1872 DTCI_VLM_TstNCmpltdLstClr "Diagnostic Trouble Code Information Extended - VLM : Test Not Completed Since Last Clear";
BA_ "SignalType" SG_ 1872 DTCI_VLM_TstFldOpCyc "ENM";
BA_ "SignalLongName" SG_ 1872 DTCI_VLM_TstFldOpCyc "Diagnostic Trouble Code Information Extended - VLM : Test Failed This Operation Cycle";
BA_ "SignalType" SG_ 1872 DTCI_VLM_TstFldLstClr "ENM";
BA_ "SignalLongName" SG_ 1872 DTCI_VLM_TstFldLstClr "Diagnostic Trouble Code Information Extended - VLM : Test Failed Since Last Clear";
BA_ "SignalType" SG_ 1872 DTCI_VLM_TstFld "ENM";
BA_ "SignalLongName" SG_ 1872 DTCI_VLM_TstFld "Diagnostic Trouble Code Information Extended - VLM : Test Failed";
BA_ "SignalType" SG_ 1872 DTCI_VLM_PndngDTC "ENM";
BA_ "SignalLongName" SG_ 1872 DTCI_VLM_PndngDTC "Diagnostic Trouble Code Information Extended - VLM : Pending DTC";
BA_ "SignalType" SG_ 1872 DTCI_VLM_DTCTriggered "ENM";
BA_ "SignalLongName" SG_ 1872 DTCI_VLM_DTCTriggered "Diagnostic Trouble Code Information Extended - VLM : Diagnostic Trouble Code Triggered";
BA_ "SignalType" SG_ 1872 DTCI_VLM_WrnIndTrggrd "ENM";
BA_ "SignalLongName" SG_ 1872 DTCI_VLM_WrnIndTrggrd "Diagnostic Trouble Code Information Extended - VLM : Warning Indicator Triggered";
BA_ "SignalType" SG_ 1872 DTCI_VLM_WrnIndRqd "ENM";
BA_ "SignalLongName" SG_ 1872 DTCI_VLM_WrnIndRqd "Diagnostic Trouble Code Information Extended - VLM : Warning Indicator Requested";
BA_ "SignalLongName" SG_ 1193 DTCI_VPM_DTCFailType "Diagnostic Trouble Code Information Extended - VPM : Diagnostic Trouble Code Failure Type";
BA_ "SignalType" SG_ 1193 DTCI_VPM_CnfrmdDTC "ENM";
BA_ "SignalLongName" SG_ 1193 DTCI_VPM_CnfrmdDTC "Diagnostic Trouble Code Information Extended - VPM : Confirmed DTC";
BA_ "SignalType" SG_ 1193 DTCI_VPM_DTCFaultType "ENM";
BA_ "SignalLongName" SG_ 1193 DTCI_VPM_DTCFaultType "Diagnostic Trouble Code Information Extended - VPM : Diagnostic Trouble Code Fault Type";
BA_ "SignalLongName" SG_ 1193 DTCI_VPM_DTCNumber "Diagnostic Trouble Code Information Extended - VPM : Diagnostic Trouble Code Number";
BA_ "SignalLongName" SG_ 1193 DTCI_VPM_DTCSource "Diagnostic Trouble Code Information Extended - VPM : Diagnostic Trouble Code Source";
BA_ "SignalType" SG_ 1193 DTCI_VPM_TstNCmpltdOpCyc "ENM";
BA_ "SignalLongName" SG_ 1193 DTCI_VPM_TstNCmpltdOpCyc "Diagnostic Trouble Code Information Extended - VPM : Test Not Completed This Operation Cycle";
BA_ "SignalType" SG_ 1193 DTCI_VPM_TstNCmpltdLstClr "ENM";
BA_ "SignalLongName" SG_ 1193 DTCI_VPM_TstNCmpltdLstClr "Diagnostic Trouble Code Information Extended - VPM : Test Not Completed Since Last Clear";
BA_ "SignalType" SG_ 1193 DTCI_VPM_TstFldOpCyc "ENM";
BA_ "SignalLongName" SG_ 1193 DTCI_VPM_TstFldOpCyc "Diagnostic Trouble Code Information Extended - VPM : Test Failed This Operation Cycle";
BA_ "SignalType" SG_ 1193 DTCI_VPM_TstFldLstClr "ENM";
BA_ "SignalLongName" SG_ 1193 DTCI_VPM_TstFldLstClr "Diagnostic Trouble Code Information Extended - VPM : Test Failed Since Last Clear";
BA_ "SignalType" SG_ 1193 DTCI_VPM_TstFld "ENM";
BA_ "SignalLongName" SG_ 1193 DTCI_VPM_TstFld "Diagnostic Trouble Code Information Extended - VPM : Test Failed";
BA_ "SignalType" SG_ 1193 DTCI_VPM_PndngDTC "ENM";
BA_ "SignalLongName" SG_ 1193 DTCI_VPM_PndngDTC "Diagnostic Trouble Code Information Extended - VPM : Pending DTC";
BA_ "SignalType" SG_ 1193 DTCI_VPM_DTCTriggered "ENM";
BA_ "SignalLongName" SG_ 1193 DTCI_VPM_DTCTriggered "Diagnostic Trouble Code Information Extended - VPM : Diagnostic Trouble Code Triggered";
BA_ "SignalType" SG_ 1193 DTCI_VPM_WrnIndTrggrd "ENM";
BA_ "SignalLongName" SG_ 1193 DTCI_VPM_WrnIndTrggrd "Diagnostic Trouble Code Information Extended - VPM : Warning Indicator Triggered";
BA_ "SignalType" SG_ 1193 DTCI_VPM_WrnIndRqd "ENM";
BA_ "SignalLongName" SG_ 1193 DTCI_VPM_WrnIndRqd "Diagnostic Trouble Code Information Extended - VPM : Warning Indicator Requested";
BA_ "SignalLongName" SG_ 1346 DTCI_WCM2_DTCFailType "Diagnostic Trouble Code Information Extended - WCM2 : Diagnostic Trouble Code Failure Type";
BA_ "SignalType" SG_ 1346 DTCI_WCM2_CnfrmdDTC "ENM";
BA_ "SignalLongName" SG_ 1346 DTCI_WCM2_CnfrmdDTC "Diagnostic Trouble Code Information Extended - WCM2 : Confirmed DTC";
BA_ "SignalType" SG_ 1346 DTCI_WCM2_DTCFaultType "ENM";
BA_ "SignalLongName" SG_ 1346 DTCI_WCM2_DTCFaultType "Diagnostic Trouble Code Information Extended - WCM2 : Diagnostic Trouble Code Fault Type";
BA_ "SignalLongName" SG_ 1346 DTCI_WCM2_DTCNumber "Diagnostic Trouble Code Information Extended - WCM2 : Diagnostic Trouble Code Number";
BA_ "SignalLongName" SG_ 1346 DTCI_WCM2_DTCSource "Diagnostic Trouble Code Information Extended - WCM2 : Diagnostic Trouble Code Source";
BA_ "SignalType" SG_ 1346 DTCI_WCM2_TstNCmpltdOpCyc "ENM";
BA_ "SignalLongName" SG_ 1346 DTCI_WCM2_TstNCmpltdOpCyc "Diagnostic Trouble Code Information Extended - WCM2 : Test Not Completed This Operation Cycle";
BA_ "SignalType" SG_ 1346 DTCI_WCM2_TstNCmpltdLstClr "ENM";
BA_ "SignalLongName" SG_ 1346 DTCI_WCM2_TstNCmpltdLstClr "Diagnostic Trouble Code Information Extended - WCM2 : Test Not Completed Since Last Clear";
BA_ "SignalType" SG_ 1346 DTCI_WCM2_TstFldOpCyc "ENM";
BA_ "SignalLongName" SG_ 1346 DTCI_WCM2_TstFldOpCyc "Diagnostic Trouble Code Information Extended - WCM2 : Test Failed This Operation Cycle";
BA_ "SignalType" SG_ 1346 DTCI_WCM2_TstFldLstClr "ENM";
BA_ "SignalLongName" SG_ 1346 DTCI_WCM2_TstFldLstClr "Diagnostic Trouble Code Information Extended - WCM2 : Test Failed Since Last Clear";
BA_ "SignalType" SG_ 1346 DTCI_WCM2_TstFld "ENM";
BA_ "SignalLongName" SG_ 1346 DTCI_WCM2_TstFld "Diagnostic Trouble Code Information Extended - WCM2 : Test Failed";
BA_ "SignalType" SG_ 1346 DTCI_WCM2_PndngDTC "ENM";
BA_ "SignalLongName" SG_ 1346 DTCI_WCM2_PndngDTC "Diagnostic Trouble Code Information Extended - WCM2 : Pending DTC";
BA_ "SignalType" SG_ 1346 DTCI_WCM2_DTCTriggered "ENM";
BA_ "SignalLongName" SG_ 1346 DTCI_WCM2_DTCTriggered "Diagnostic Trouble Code Information Extended - WCM2 : Diagnostic Trouble Code Triggered";
BA_ "SignalType" SG_ 1346 DTCI_WCM2_WrnIndTrggrd "ENM";
BA_ "SignalLongName" SG_ 1346 DTCI_WCM2_WrnIndTrggrd "Diagnostic Trouble Code Information Extended - WCM2 : Warning Indicator Triggered";
BA_ "SignalType" SG_ 1346 DTCI_WCM2_WrnIndRqd "ENM";
BA_ "SignalLongName" SG_ 1346 DTCI_WCM2_WrnIndRqd "Diagnostic Trouble Code Information Extended - WCM2 : Warning Indicator Requested";
BA_ "SignalLongName" SG_ 1285 DTCI_WCM3_DTCFailType "Diagnostic Trouble Code Information Extended - WCM3 : Diagnostic Trouble Code Failure Type";
BA_ "SignalType" SG_ 1285 DTCI_WCM3_CnfrmdDTC "ENM";
BA_ "SignalLongName" SG_ 1285 DTCI_WCM3_CnfrmdDTC "Diagnostic Trouble Code Information Extended - WCM3 : Confirmed DTC";
BA_ "SignalType" SG_ 1285 DTCI_WCM3_DTCFaultType "ENM";
BA_ "SignalLongName" SG_ 1285 DTCI_WCM3_DTCFaultType "Diagnostic Trouble Code Information Extended - WCM3 : Diagnostic Trouble Code Fault Type";
BA_ "SignalLongName" SG_ 1285 DTCI_WCM3_DTCNumber "Diagnostic Trouble Code Information Extended - WCM3 : Diagnostic Trouble Code Number";
BA_ "SignalLongName" SG_ 1285 DTCI_WCM3_DTCSource "Diagnostic Trouble Code Information Extended - WCM3 : Diagnostic Trouble Code Source";
BA_ "SignalType" SG_ 1285 DTCI_WCM3_TstNCmpltdOpCyc "ENM";
BA_ "SignalLongName" SG_ 1285 DTCI_WCM3_TstNCmpltdOpCyc "Diagnostic Trouble Code Information Extended - WCM3 : Test Not Completed This Operation Cycle";
BA_ "SignalType" SG_ 1285 DTCI_WCM3_TstNCmpltdLstClr "ENM";
BA_ "SignalLongName" SG_ 1285 DTCI_WCM3_TstNCmpltdLstClr "Diagnostic Trouble Code Information Extended - WCM3 : Test Not Completed Since Last Clear";
BA_ "SignalType" SG_ 1285 DTCI_WCM3_TstFldOpCyc "ENM";
BA_ "SignalLongName" SG_ 1285 DTCI_WCM3_TstFldOpCyc "Diagnostic Trouble Code Information Extended - WCM3 : Test Failed This Operation Cycle";
BA_ "SignalType" SG_ 1285 DTCI_WCM3_TstFldLstClr "ENM";
BA_ "SignalLongName" SG_ 1285 DTCI_WCM3_TstFldLstClr "Diagnostic Trouble Code Information Extended - WCM3 : Test Failed Since Last Clear";
BA_ "SignalType" SG_ 1285 DTCI_WCM3_TstFld "ENM";
BA_ "SignalLongName" SG_ 1285 DTCI_WCM3_TstFld "Diagnostic Trouble Code Information Extended - WCM3 : Test Failed";
BA_ "SignalType" SG_ 1285 DTCI_WCM3_PndngDTC "ENM";
BA_ "SignalLongName" SG_ 1285 DTCI_WCM3_PndngDTC "Diagnostic Trouble Code Information Extended - WCM3 : Pending DTC";
BA_ "SignalType" SG_ 1285 DTCI_WCM3_DTCTriggered "ENM";
BA_ "SignalLongName" SG_ 1285 DTCI_WCM3_DTCTriggered "Diagnostic Trouble Code Information Extended - WCM3 : Diagnostic Trouble Code Triggered";
BA_ "SignalType" SG_ 1285 DTCI_WCM3_WrnIndTrggrd "ENM";
BA_ "SignalLongName" SG_ 1285 DTCI_WCM3_WrnIndTrggrd "Diagnostic Trouble Code Information Extended - WCM3 : Warning Indicator Triggered";
BA_ "SignalType" SG_ 1285 DTCI_WCM3_WrnIndRqd "ENM";
BA_ "SignalLongName" SG_ 1285 DTCI_WCM3_WrnIndRqd "Diagnostic Trouble Code Information Extended - WCM3 : Warning Indicator Requested";
BA_ "SignalLongName" SG_ 1216 DTCI_WCM4_DTCFailType "Diagnostic Trouble Code Information Extended - WCM4 : Diagnostic Trouble Code Failure Type";
BA_ "SignalType" SG_ 1216 DTCI_WCM4_CnfrmdDTC "ENM";
BA_ "SignalLongName" SG_ 1216 DTCI_WCM4_CnfrmdDTC "Diagnostic Trouble Code Information Extended - WCM4 : Confirmed DTC";
BA_ "SignalType" SG_ 1216 DTCI_WCM4_DTCFaultType "ENM";
BA_ "SignalLongName" SG_ 1216 DTCI_WCM4_DTCFaultType "Diagnostic Trouble Code Information Extended - WCM4 : Diagnostic Trouble Code Fault Type";
BA_ "SignalLongName" SG_ 1216 DTCI_WCM4_DTCNumber "Diagnostic Trouble Code Information Extended - WCM4 : Diagnostic Trouble Code Number";
BA_ "SignalLongName" SG_ 1216 DTCI_WCM4_DTCSource "Diagnostic Trouble Code Information Extended - WCM4 : Diagnostic Trouble Code Source";
BA_ "SignalType" SG_ 1216 DTCI_WCM4_TstNCmpltdOpCyc "ENM";
BA_ "SignalLongName" SG_ 1216 DTCI_WCM4_TstNCmpltdOpCyc "Diagnostic Trouble Code Information Extended - WCM4 : Test Not Completed This Operation Cycle";
BA_ "SignalType" SG_ 1216 DTCI_WCM4_TstNCmpltdLstClr "ENM";
BA_ "SignalLongName" SG_ 1216 DTCI_WCM4_TstNCmpltdLstClr "Diagnostic Trouble Code Information Extended - WCM4 : Test Not Completed Since Last Clear";
BA_ "SignalType" SG_ 1216 DTCI_WCM4_TstFldOpCyc "ENM";
BA_ "SignalLongName" SG_ 1216 DTCI_WCM4_TstFldOpCyc "Diagnostic Trouble Code Information Extended - WCM4 : Test Failed This Operation Cycle";
BA_ "SignalType" SG_ 1216 DTCI_WCM4_TstFldLstClr "ENM";
BA_ "SignalLongName" SG_ 1216 DTCI_WCM4_TstFldLstClr "Diagnostic Trouble Code Information Extended - WCM4 : Test Failed Since Last Clear";
BA_ "SignalType" SG_ 1216 DTCI_WCM4_TstFld "ENM";
BA_ "SignalLongName" SG_ 1216 DTCI_WCM4_TstFld "Diagnostic Trouble Code Information Extended - WCM4 : Test Failed";
BA_ "SignalType" SG_ 1216 DTCI_WCM4_PndngDTC "ENM";
BA_ "SignalLongName" SG_ 1216 DTCI_WCM4_PndngDTC "Diagnostic Trouble Code Information Extended - WCM4 : Pending DTC";
BA_ "SignalType" SG_ 1216 DTCI_WCM4_DTCTriggered "ENM";
BA_ "SignalLongName" SG_ 1216 DTCI_WCM4_DTCTriggered "Diagnostic Trouble Code Information Extended - WCM4 : Diagnostic Trouble Code Triggered";
BA_ "SignalType" SG_ 1216 DTCI_WCM4_WrnIndTrggrd "ENM";
BA_ "SignalLongName" SG_ 1216 DTCI_WCM4_WrnIndTrggrd "Diagnostic Trouble Code Information Extended - WCM4 : Warning Indicator Triggered";
BA_ "SignalType" SG_ 1216 DTCI_WCM4_WrnIndRqd "ENM";
BA_ "SignalLongName" SG_ 1216 DTCI_WCM4_WrnIndRqd "Diagnostic Trouble Code Information Extended - WCM4 : Warning Indicator Requested";
BA_ "SignalLongName" SG_ 1873 DTCI_WCM_DTCFailType "Diagnostic Trouble Code Information Extended - WCM : Diagnostic Trouble Code Failure Type";
BA_ "SignalType" SG_ 1873 DTCI_WCM_CnfrmdDTC "ENM";
BA_ "SignalLongName" SG_ 1873 DTCI_WCM_CnfrmdDTC "Diagnostic Trouble Code Information Extended - WCM : Confirmed DTC";
BA_ "SignalType" SG_ 1873 DTCI_WCM_DTCFaultType "ENM";
BA_ "SignalLongName" SG_ 1873 DTCI_WCM_DTCFaultType "Diagnostic Trouble Code Information Extended - WCM : Diagnostic Trouble Code Fault Type";
BA_ "SignalLongName" SG_ 1873 DTCI_WCM_DTCNumber "Diagnostic Trouble Code Information Extended - WCM : Diagnostic Trouble Code Number";
BA_ "SignalLongName" SG_ 1873 DTCI_WCM_DTCSource "Diagnostic Trouble Code Information Extended - WCM : Diagnostic Trouble Code Source";
BA_ "SignalType" SG_ 1873 DTCI_WCM_TstNCmpltdOpCyc "ENM";
BA_ "SignalLongName" SG_ 1873 DTCI_WCM_TstNCmpltdOpCyc "Diagnostic Trouble Code Information Extended - WCM : Test Not Completed This Operation Cycle";
BA_ "SignalType" SG_ 1873 DTCI_WCM_TstNCmpltdLstClr "ENM";
BA_ "SignalLongName" SG_ 1873 DTCI_WCM_TstNCmpltdLstClr "Diagnostic Trouble Code Information Extended - WCM : Test Not Completed Since Last Clear";
BA_ "SignalType" SG_ 1873 DTCI_WCM_TstFldOpCyc "ENM";
BA_ "SignalLongName" SG_ 1873 DTCI_WCM_TstFldOpCyc "Diagnostic Trouble Code Information Extended - WCM : Test Failed This Operation Cycle";
BA_ "SignalType" SG_ 1873 DTCI_WCM_TstFldLstClr "ENM";
BA_ "SignalLongName" SG_ 1873 DTCI_WCM_TstFldLstClr "Diagnostic Trouble Code Information Extended - WCM : Test Failed Since Last Clear";
BA_ "SignalType" SG_ 1873 DTCI_WCM_TstFld "ENM";
BA_ "SignalLongName" SG_ 1873 DTCI_WCM_TstFld "Diagnostic Trouble Code Information Extended - WCM : Test Failed";
BA_ "SignalType" SG_ 1873 DTCI_WCM_PndngDTC "ENM";
BA_ "SignalLongName" SG_ 1873 DTCI_WCM_PndngDTC "Diagnostic Trouble Code Information Extended - WCM : Pending DTC";
BA_ "SignalType" SG_ 1873 DTCI_WCM_DTCTriggered "ENM";
BA_ "SignalLongName" SG_ 1873 DTCI_WCM_DTCTriggered "Diagnostic Trouble Code Information Extended - WCM : Diagnostic Trouble Code Triggered";
BA_ "SignalType" SG_ 1873 DTCI_WCM_WrnIndTrggrd "ENM";
BA_ "SignalLongName" SG_ 1873 DTCI_WCM_WrnIndTrggrd "Diagnostic Trouble Code Information Extended - WCM : Warning Indicator Triggered";
BA_ "SignalType" SG_ 1873 DTCI_WCM_WrnIndRqd "ENM";
BA_ "SignalLongName" SG_ 1873 DTCI_WCM_WrnIndRqd "Diagnostic Trouble Code Information Extended - WCM : Warning Indicator Requested";
BA_ "SignalLongName" SG_ 1390 DrvlnDispInfo_PCSM "Driveline Display Information Protected Counter Sync Message";
BA_ "SignalLongName" SG_ 872 DDIP_MAC "Driveline Display Information Protected : MAC";
BA_ "SignalLongName" SG_ 872 DDIP_FCnt "Driveline Display Information Protected : Freshness Counter";
BA_ "SignalLongName" SG_ 872 DDIP_ARC "Driveline Display Information Protected : Alive Rolling Count";
BA_ "SignalType" SG_ 872 DDIP_SecAxl4WDAWDTmpInhbIOAuth "ENM";
BA_ "SignalLongName" SG_ 872 DDIP_SecAxl4WDAWDTmpInhbIOAuth "Driveline Display Information Protected : Secondary Axle 4WD AWD Temporary Inhibit Indication On Authenticated";
BA_ "SignalType" SG_ 872 DDIP_SecAxl4WDAWDNonEmMlfIOAuth "ENM";
BA_ "SignalLongName" SG_ 872 DDIP_SecAxl4WDAWDNonEmMlfIOAuth "Driveline Display Information Protected : Secondary Axle 4WD AWD Non emissions Malfunction Indication On Authenticated";
BA_ "SignalType" SG_ 872 DDIP_4AndAllWhlDrvIndReqAuth "ENM";
BA_ "SignalLongName" SG_ 872 DDIP_4AndAllWhlDrvIndReqAuth "Driveline Display Information Protected : Four and All Wheel Drive Indication Request Authenticated";
BA_ "SignalLongName" SG_ 872 DDIP_Filler "Driveline Display Information Protected : Filler";
BA_ "SignalLongName" SG_ 85 WhlAngVelLFrtAuth "Serial Data 16 Protected : Wheel Angular Velocity Left Front Authenticated";
BA_ "SignalType" SG_ 85 WhlAngVelLFrtAuth_Inv "ENM";
BA_ "SignalLongName" SG_ 85 WhlAngVelLFrtAuth_Inv "Serial Data 16 Protected : Wheel Angular Velocity Left Front Authenticated Invalid";
BA_ "SignalType" SG_ 85 WhlAngVelLRrAuth_Inv "ENM";
BA_ "SignalLongName" SG_ 85 WhlAngVelLRrAuth_Inv "Serial Data 16 Protected : Wheel Angular Velocity Left Rear Authenticated Invalid";
BA_ "SignalLongName" SG_ 85 WhlAngVelLRrAuth "Serial Data 16 Protected : Wheel Angular Velocity Left Rear Authenticated";
BA_ "SignalLongName" SG_ 85 WhlAngVelRFrtAuth "Serial Data 16 Protected : Wheel Angular Velocity Right Front Authenticated";
BA_ "SignalType" SG_ 85 WhlAngVelRFrtAuth_Inv "ENM";
BA_ "SignalLongName" SG_ 85 WhlAngVelRFrtAuth_Inv "Serial Data 16 Protected : Wheel Angular Velocity Right Front Authenticated Invalid";
BA_ "SignalLongName" SG_ 85 WhlAngVelRRrAuth "Serial Data 16 Protected : Wheel Angular Velocity Right Rear Authenticated";
BA_ "SignalType" SG_ 85 WhlAngVelRRrAuth_Inv "ENM";
BA_ "SignalLongName" SG_ 85 WhlAngVelRRrAuth_Inv "Serial Data 16 Protected : Wheel Angular Velocity Right Rear Authenticated Invalid";
BA_ "SignalLongName" SG_ 69 CSBTP_ChsSysTtBrkAxTqVlAuth "Serial Data 16 Protected : Chassis System Total Brake Axle Torque Value Authenticated";
BA_ "SignalLongName" SG_ 69 CSBTP_DrvrIntndTtBrkTqAuth "Serial Data 16 Protected : Driver Intended Total Brake Torque Authenticated";
BA_ "SignalLongName" SG_ 69 CBIP_BrkPedPstnEmsRltdAuth "Serial Data 16 Protected : Brake Pedal Position Emissions Related Authenticated";
BA_ "SignalType" SG_ 69 CBIP_BrkPedPstnEmsRltdAuth_Inv "ENM";
BA_ "SignalLongName" SG_ 69 CBIP_BrkPedPstnEmsRltdAuth_Inv "Serial Data 16 Protected : Brake Pedal Position Emissions Related Authenticated Invalid";
BA_ "SignalType" SG_ 69 CBIP_ACCBrkgStsAuth "ENM";
BA_ "SignalLongName" SG_ 69 CBIP_ACCBrkgStsAuth "Serial Data 16 Protected : Adaptive Cruise Control Braking Status Authenticated";
BA_ "SignalType" SG_ 69 BSIRP_HillDscntCtlStsAuth "ENM";
BA_ "SignalLongName" SG_ 69 BSIRP_HillDscntCtlStsAuth "Serial Data 16 Protected : Hill Descent Control Status Authenticated";
BA_ "SignalType" SG_ 730 LDGI1_LgslDiagStdCondsMet "ENM";
BA_ "SignalLongName" SG_ 730 LDGI1_LgslDiagStdCondsMet "Serial Data 29 : Legislated Diagnostics Standard Conditions Met";
BA_ "SignalLongName" SG_ 63 FWDECP_LFAuth "Serial Data 16 Protected : Wheel Distance Edge Counter Left Front Authenticated";
BA_ "SignalType" SG_ 63 FWDECP_LFAuth_Inv "ENM";
BA_ "SignalLongName" SG_ 63 FWDECP_LFAuth_Inv "Serial Data 16 Protected : Wheel Distance Edge Counter Left Front Authenticated Invalid";
BA_ "SignalLongName" SG_ 63 FWDECP_RFAuth "Serial Data 16 Protected : Wheel Distance Edge Counter Right Front Authenticated";
BA_ "SignalType" SG_ 63 FWDECP_RFAuth_Inv "ENM";
BA_ "SignalLongName" SG_ 63 FWDECP_RFAuth_Inv "Serial Data 16 Protected : Wheel Distance Edge Counter Right Front Authenticated Invalid";
BA_ "SignalLongName" SG_ 63 RWDECP_LRAuth "Serial Data 16 Protected : Rear Wheel Distance Edge Counter Left Rear Authenticated";
BA_ "SignalType" SG_ 63 RWDECP_LRAuth_Inv "ENM";
BA_ "SignalLongName" SG_ 63 RWDECP_LRAuth_Inv "Serial Data 16 Protected : Rear Wheel Distance Edge Counter Left Rear Authenticated Invalid";
BA_ "SignalLongName" SG_ 63 RWDECP_RRAuth "Serial Data 16 Protected : Rear Wheel Distance Edge Counter Right Rear Authenticated";
BA_ "SignalType" SG_ 63 RWDECP_RRAuth_Inv "ENM";
BA_ "SignalLongName" SG_ 63 RWDECP_RRAuth_Inv "Serial Data 16 Protected : Rear Wheel Distance Edge Counter Right Rear Authenticated Invalid";
BA_ "SignalType" SG_ 63 RWDECP_RstOccAuth "ENM";
BA_ "SignalLongName" SG_ 63 RWDECP_RstOccAuth "Serial Data 16 Protected : Rear Wheel Distance Edge Counter Reset Occurred Authenticated";
BA_ "SignalType" SG_ 63 FWDECP_RstOccAuth "ENM";
BA_ "SignalLongName" SG_ 63 FWDECP_RstOccAuth "Serial Data 16 Protected : Front Wheel Distance Edge Counter Reset Occurred Authenticated";
BA_ "SignalLongName" SG_ 225 PrplSysMtrBSpdAuth_Public "Serial Data 53 Protected : Propulsion System Motor B Speed Authenticated";
BA_ "SignalType" SG_ 225 PrplSysMtrBSpdAuth_Public_Inv "ENM";
BA_ "SignalLongName" SG_ 225 PrplSysMtrBSpdAuth_Public_Inv "Serial Data 53 Protected : Propulsion System Motor B Speed Authenticated Invalid";
BA_ "SignalLongName" SG_ 184 PrplSysMtrCSpdAuth_Public "Serial Data 55 Protected : Propulsion System Motor C Speed Authenticated";
BA_ "SignalType" SG_ 184 PrplSysMtrCSpdAuth_Public_Inv "ENM";
BA_ "SignalLongName" SG_ 184 PrplSysMtrCSpdAuth_Public_Inv "Serial Data 55 Protected : Propulsion System Motor C Speed Authenticated Invalid";
BA_ "SignalLongName" SG_ 1389 ElecShftRngSecDisp_PCSM "Electronic Shift Range Secondary Display Protected Counter Sync Message";
BA_ "SignalLongName" SG_ 871 ESRSDP_MAC "Electronic Shift Range Secondary Display Protected : MAC";
BA_ "SignalLongName" SG_ 871 ESRSDP_FCnt "Electronic Shift Range Secondary Display Protected : Freshness Counter";
BA_ "SignalLongName" SG_ 871 ESRSDP_Filler "Electronic Shift Range Secondary Display Protected : Filler";
BA_ "SignalLongName" SG_ 871 ESRSDP_ARC "Electronic Shift Range Secondary Display Protected : Alive Rolling Count";
BA_ "SignalType" SG_ 871 ESRSDP_ElecShftRngSecDispAuth "ENM";
BA_ "SignalLongName" SG_ 871 ESRSDP_ElecShftRngSecDispAuth "Electronic Shift Range Secondary Display Protected : Electronic Shift Range Secondary Display Authenticated";
BA_ "SignalLongName" SG_ 1400 ElecStrgColLck_PCSM "Electric Steering Column Lock Protected Counter Sync Message";
BA_ "SignalLongName" SG_ 877 ESCLP_MAC "Electric Steering Column Lock Protected : MAC";
BA_ "SignalLongName" SG_ 877 ESCLP_FCnt "Electric Steering Column Lock Protected : Freshness Counter";
BA_ "SignalLongName" SG_ 877 ESCLP_ARC "Electric Steering Column Lock Protected : Alive Rolling Count";
BA_ "SignalType" SG_ 877 ESCLP_StrgColLckdIndOnAuth "ENM";
BA_ "SignalLongName" SG_ 877 ESCLP_StrgColLckdIndOnAuth "Electric Steering Column Lock Protected : Steering Column Locked Indication On Authenticated";
BA_ "SignalType" SG_ 877 ESCLP_ServColLckIndOnAuth "ENM";
BA_ "SignalLongName" SG_ 877 ESCLP_ServColLckIndOnAuth "Electric Steering Column Lock Protected : Service Column Lock Indication On Authenticated";
BA_ "SignalType" SG_ 877 ESCLP_ElecStrgColLckStsAuth "ENM";
BA_ "SignalLongName" SG_ 877 ESCLP_ElecStrgColLckStsAuth "Electric Steering Column Lock Protected : Electric Steering Column Lock Status Authenticated";
BA_ "SignalLongName" SG_ 1388 EnhdSrvsVhTpSp_PCSM "Enhanced Services Vehicle Top Speed Protected Counter Sync Message";
BA_ "SignalLongName" SG_ 869 ESVTSP_MAC "Enhanced Services Vehicle Top Speed Protected : MAC";
BA_ "SignalLongName" SG_ 869 ESVTSP_FCnt "Enhanced Services Vehicle Top Speed Protected : Freshness Counter";
BA_ "SignalLongName" SG_ 869 ESVTSP_EnhdSrvsVhTpSpLimValAuth "Enhanced Services Vehicle Top Speed Protected : Enhanced Services Vehicle Top Speed Limit Value Authenticated";
BA_ "SignalType" SG_ 869 ESVTSP_EnhdSrvsVhTpSpLimReqAuth "ENM";
BA_ "SignalLongName" SG_ 869 ESVTSP_EnhdSrvsVhTpSpLimReqAuth "Enhanced Services Vehicle Top Speed Protected : Enhanced Services Vehicle Top Speed Limit Request Authenticated";
BA_ "SignalLongName" SG_ 869 ESVTSP_ARC "Enhanced Services Vehicle Top Speed Protected : Alive Rolling Count";
BA_ "SignalLongName" SG_ 1067 FOMI_ACP2_MCU_DTCNumber "Figure of Merit Information ACP2_MCU : DTC Number";
BA_ "SignalType" SG_ 1067 FOMI_ACP2_MCU_DTCTriggered "ENM";
BA_ "SignalLongName" SG_ 1067 FOMI_ACP2_MCU_DTCTriggered "Figure of Merit Information ACP2_MCU : DTC Triggered";
BA_ "SignalLongName" SG_ 1066 FOMI_ACP3_MCU_DTCNumber "Figure of Merit Information ACP3_MCU : DTC Number";
BA_ "SignalType" SG_ 1066 FOMI_ACP3_MCU_DTCTriggered "ENM";
BA_ "SignalLongName" SG_ 1066 FOMI_ACP3_MCU_DTCTriggered "Figure of Merit Information ACP3_MCU : DTC Triggered";
BA_ "SignalLongName" SG_ 2001 FOMI_ACP4_MCU_DTCNumber "Figure of Merit Information ACP4_MCU : DTC Number";
BA_ "SignalType" SG_ 2001 FOMI_ACP4_MCU_DTCTriggered "ENM";
BA_ "SignalLongName" SG_ 2001 FOMI_ACP4_MCU_DTCTriggered "Figure of Merit Information ACP4_MCU : DTC Triggered";
BA_ "SignalLongName" SG_ 2008 FOMI_BCM_DTCNumber "Figure of Merit Information BCM : DTC Number";
BA_ "SignalType" SG_ 2008 FOMI_BCM_DTCTriggered "ENM";
BA_ "SignalLongName" SG_ 2008 FOMI_BCM_DTCTriggered "Figure of Merit Information BCM : DTC Triggered";
BA_ "SignalLongName" SG_ 1065 FOMI_BSM_DTCNumber "Figure of Merit Information BSM : DTC Number";
BA_ "SignalType" SG_ 1065 FOMI_BSM_DTCTriggered "ENM";
BA_ "SignalLongName" SG_ 1065 FOMI_BSM_DTCTriggered "Figure of Merit Information BSM : DTC Triggered";
BA_ "SignalLongName" SG_ 2002 FOMI_EBCM_DTCNumber "Figure of Merit Information EBCM : DTC Number";
BA_ "SignalType" SG_ 2002 FOMI_EBCM_DTCTriggered "ENM";
BA_ "SignalLongName" SG_ 2002 FOMI_EBCM_DTCTriggered "Figure of Merit Information EBCM : DTC Triggered";
BA_ "SignalLongName" SG_ 2007 FOMI_ECM_DTCNumber "Figure of Merit Information ECM : DTC Number";
BA_ "SignalType" SG_ 2007 FOMI_ECM_DTCTriggered "ENM";
BA_ "SignalLongName" SG_ 2007 FOMI_ECM_DTCTriggered "Figure of Merit Information ECM : DTC Triggered";
BA_ "SignalLongName" SG_ 1064 FOMI_ECP_E_DTCNumber "Figure of Merit Information ECP_E : DTC Number";
BA_ "SignalType" SG_ 1064 FOMI_ECP_E_DTCTriggered "ENM";
BA_ "SignalLongName" SG_ 1064 FOMI_ECP_E_DTCTriggered "Figure of Merit Information ECP_E : DTC Triggered";
BA_ "SignalLongName" SG_ 2003 FOMI_ECP_H1_DTCNumber "Figure of Merit Information ECP_H1 : DTC Number";
BA_ "SignalType" SG_ 2003 FOMI_ECP_H1_DTCTriggered "ENM";
BA_ "SignalLongName" SG_ 2003 FOMI_ECP_H1_DTCTriggered "Figure of Merit Information ECP_H1 : DTC Triggered";
BA_ "SignalLongName" SG_ 1063 FOMI_ECP_H2_DTCNumber "Figure of Merit Information ECP_H2 : DTC Number";
BA_ "SignalType" SG_ 1063 FOMI_ECP_H2_DTCTriggered "ENM";
BA_ "SignalLongName" SG_ 1063 FOMI_ECP_H2_DTCTriggered "Figure of Merit Information ECP_H2 : DTC Triggered";
BA_ "SignalLongName" SG_ 1062 FOMI_ECP_H3_DTCNumber "Figure of Merit Information ECP_H3 : DTC Number";
BA_ "SignalType" SG_ 1062 FOMI_ECP_H3_DTCTriggered "ENM";
BA_ "SignalLongName" SG_ 1062 FOMI_ECP_H3_DTCTriggered "Figure of Merit Information ECP_H3 : DTC Triggered";
BA_ "SignalLongName" SG_ 1072 FOMI_ECP_S2_DTCNumber "Figure of Merit Information ECP_S2 : DTC Number";
BA_ "SignalType" SG_ 1072 FOMI_ECP_S2_DTCTriggered "ENM";
BA_ "SignalLongName" SG_ 1072 FOMI_ECP_S2_DTCTriggered "Figure of Merit Information ECP_S2 : DTC Triggered";
BA_ "SignalLongName" SG_ 1995 FOMI_ECP_S_DTCNumber "Figure of Merit Information ECP_S : DTC Number";
BA_ "SignalType" SG_ 1995 FOMI_ECP_S_DTCTriggered "ENM";
BA_ "SignalLongName" SG_ 1995 FOMI_ECP_S_DTCTriggered "Figure of Merit Information ECP_S : DTC Triggered";
BA_ "SignalLongName" SG_ 1071 FOMI_ECP_X1_DTCNumber "Figure of Merit Information ECP_X1 : DTC Number";
BA_ "SignalType" SG_ 1071 FOMI_ECP_X1_DTCTriggered "ENM";
BA_ "SignalLongName" SG_ 1071 FOMI_ECP_X1_DTCTriggered "Figure of Merit Information ECP_X1 : DTC Triggered";
BA_ "SignalLongName" SG_ 1996 FOMI_ELM_DTCNumber "Figure of Merit Information ELM : DTC Number";
BA_ "SignalType" SG_ 1996 FOMI_ELM_DTCTriggered "ENM";
BA_ "SignalLongName" SG_ 1996 FOMI_ELM_DTCTriggered "Figure of Merit Information ELM : DTC Triggered";
BA_ "SignalLongName" SG_ 1997 FOMI_EOCM_HCP1_DTCNumber "Figure of Merit Information EOCM_HCP1 : DTC Number";
BA_ "SignalType" SG_ 1997 FOMI_EOCM_HCP1_DTCTriggered "ENM";
BA_ "SignalLongName" SG_ 1997 FOMI_EOCM_HCP1_DTCTriggered "Figure of Merit Information EOCM_HCP1 : DTC Triggered";
BA_ "SignalLongName" SG_ 1070 FOMI_EOCM_DTCNumber "Figure of Merit Information EOCM : DTC Number";
BA_ "SignalType" SG_ 1070 FOMI_EOCM_DTCTriggered "ENM";
BA_ "SignalLongName" SG_ 1070 FOMI_EOCM_DTCTriggered "Figure of Merit Information EOCM : DTC Triggered";
BA_ "SignalLongName" SG_ 1069 FOMI_ICCM_DTCNumber "Figure of Merit Information ICCM : DTC Number";
BA_ "SignalType" SG_ 1069 FOMI_ICCM_DTCTriggered "ENM";
BA_ "SignalLongName" SG_ 1069 FOMI_ICCM_DTCTriggered "Figure of Merit Information ICCM : DTC Triggered";
BA_ "SignalLongName" SG_ 1998 FOMI_PCM_DTCNumber "Figure of Merit Information PCM : DTC Number";
BA_ "SignalType" SG_ 1998 FOMI_PCM_DTCTriggered "ENM";
BA_ "SignalLongName" SG_ 1998 FOMI_PCM_DTCTriggered "Figure of Merit Information PCM : DTC Triggered";
BA_ "SignalLongName" SG_ 1068 FOMI_TCM_DTCNumber "Figure of Merit Information TCM : DTC Number";
BA_ "SignalType" SG_ 1068 FOMI_TCM_DTCTriggered "ENM";
BA_ "SignalLongName" SG_ 1068 FOMI_TCM_DTCTriggered "Figure of Merit Information TCM : DTC Triggered";
BA_ "SignalLongName" SG_ 1999 FOMI_VECM_DTCNumber "Figure of Merit Information VECM : DTC Number";
BA_ "SignalType" SG_ 1999 FOMI_VECM_DTCTriggered "ENM";
BA_ "SignalLongName" SG_ 1999 FOMI_VECM_DTCTriggered "Figure of Merit Information VECM : DTC Triggered";
BA_ "SignalLongName" SG_ 2009 FOMI_VICM_DTCNumber "Figure of Merit Information VICM : DTC Number";
BA_ "SignalType" SG_ 2009 FOMI_VICM_DTCTriggered "ENM";
BA_ "SignalLongName" SG_ 2009 FOMI_VICM_DTCTriggered "Figure of Merit Information VICM : DTC Triggered";
BA_ "SignalLongName" SG_ 1508 FI_FiltdDispTotFlLvlPct "Fuel Information : Filtered Display Total Fuel Level Percent";
BA_ "SignalLongName" SG_ 1508 FI_FiltdDispTotFlLvlTnk2Pct "Fuel Information : Filtered Display Total Fuel Level Tank 2 Percent";
BA_ "SignalType" SG_ 1508 FI_FiltdDispTotFlLvlPct_Inv "ENM";
BA_ "SignalLongName" SG_ 1508 FI_FiltdDispTotFlLvlPct_Inv "Fuel Information : Filtered Display Total Fuel Level Percent Invalid";
BA_ "SignalType" SG_ 1508 FI_FiltdDispTotFlLvlTnk2Pct_Inv "ENM";
BA_ "SignalLongName" SG_ 1508 FI_FiltdDispTotFlLvlTnk2Pct_Inv "Fuel Information : Filtered Display Total Fuel Level Tank 2 Percent Invalid";
BA_ "SignalLongName" SG_ 1508 FI_CS "Fuel Information : Checksum";
BA_ "SignalLongName" SG_ 1508 FI_ARC "Fuel Information : Alive Rolling Count";
BA_ "SignalLongName" SG_ 724 GPSQM_PPS2DAbsPstnErrEst "Global Positioning System Quality Metrics : Precise Positioning System 2D Absolute Position Error Estimate";
BA_ "SignalLongName" SG_ 724 GPSQM_PPS3DAbsPstnErrEst "Global Positioning System Quality Metrics : Precise Positioning System 3D Absolute Position Error Estimate";
BA_ "SignalType" SG_ 724 GPSQM_PPS2DAbsPstnErrEst_Inv "ENM";
BA_ "SignalLongName" SG_ 724 GPSQM_PPS2DAbsPstnErrEst_Inv "Global Positioning System Quality Metrics : Precise Positioning System 2D Absolute Position Error Estimate Invalid";
BA_ "SignalLongName" SG_ 724 GPSQM_PPSAbsHdgErrEst "Global Positioning System Quality Metrics : Precise Positioning System Absolute Heading Error Estimate";
BA_ "SignalType" SG_ 724 GPSQM_PPS3DAbsPstnErrEst_Inv "ENM";
BA_ "SignalLongName" SG_ 724 GPSQM_PPS3DAbsPstnErrEst_Inv "Global Positioning System Quality Metrics : Precise Positioning System 3D Absolute Position Error Estimate Invalid";
BA_ "SignalLongName" SG_ 724 GPSQM_PPSAbsVelErrEst "Global Positioning System Quality Metrics : Precise Positioning System Absolute Velocity Error Estimate";
BA_ "SignalLongName" SG_ 724 GPSQM_PPSPstnDilutnPrcsn "Global Positioning System Quality Metrics : Precise Positioning System Position Dilution of Precision";
BA_ "SignalType" SG_ 724 GPSQM_PPSMode_Inv "ENM";
BA_ "SignalLongName" SG_ 724 GPSQM_PPSMode_Inv "Global Positioning System Quality Metrics : Precise Positioning System Mode Invalid";
BA_ "SignalType" SG_ 724 GPSQM_PPSMode "ENM";
BA_ "SignalLongName" SG_ 724 GPSQM_PPSMode "Global Positioning System Quality Metrics : Precise Positioning System Mode";
BA_ "SignalType" SG_ 724 GPSQM_PPSAbsVelErrEst_Inv "ENM";
BA_ "SignalLongName" SG_ 724 GPSQM_PPSAbsVelErrEst_Inv "Global Positioning System Quality Metrics : Precise Positioning System Absolute Velocity Error Estimate Invalid";
BA_ "SignalType" SG_ 724 GPSQM_PPSAbsHdgErrEst_Inv "ENM";
BA_ "SignalLongName" SG_ 724 GPSQM_PPSAbsHdgErrEst_Inv "Global Positioning System Quality Metrics : Precise Positioning System Absolute Heading Error Estimate Invalid";
BA_ "SignalType" SG_ 724 GPSQM_PPSPstnDilutnPrcsn_Inv "ENM";
BA_ "SignalLongName" SG_ 724 GPSQM_PPSPstnDilutnPrcsn_Inv "Global Positioning System Quality Metrics : Precise Positioning System Position Dilution of Precision Invalid";
BA_ "SignalLongName" SG_ 725 GPSC_PPSLat "Global Positioning System Coordinates : Precise Positioning System Latitude";
BA_ "SignalLongName" SG_ 725 GPSC_PPSLong "Global Positioning System Coordinates : Precise Positioning System Longitude";
BA_ "SignalType" SG_ 725 GPSC_PPSLat_Inv "ENM";
BA_ "SignalLongName" SG_ 725 GPSC_PPSLat_Inv "Global Positioning System Coordinates : Precise Positioning System Latitude Invalid";
BA_ "SignalType" SG_ 725 GPSC_PPSLong_Inv "ENM";
BA_ "SignalLongName" SG_ 725 GPSC_PPSLong_Inv "Global Positioning System Coordinates : Precise Positioning System Longitude Invalid";
BA_ "SignalLongName" SG_ 726 GPST_PPSCldrDy "Global Positioning System Time : Precise Positioning System Calendar Day";
BA_ "SignalLongName" SG_ 726 GPST_PPSCldrYr "Global Positioning System Time : Precise Positioning System Calendar Year";
BA_ "SignalType" SG_ 726 GPST_PPSCldrDy_Inv "ENM";
BA_ "SignalLongName" SG_ 726 GPST_PPSCldrDy_Inv "Global Positioning System Time : Precise Positioning System Calendar Day Invalid";
BA_ "SignalLongName" SG_ 726 GPST_PPSTmOfDy "Global Positioning System Time : Precise Positioning System Time of Day";
BA_ "SignalType" SG_ 726 GPST_PPSCldrYr_Inv "ENM";
BA_ "SignalLongName" SG_ 726 GPST_PPSCldrYr_Inv "Global Positioning System Time : Precise Positioning System Calendar Year Invalid";
BA_ "SignalType" SG_ 726 GPST_PPSTmOfDy_Inv "ENM";
BA_ "SignalLongName" SG_ 726 GPST_PPSTmOfDy_Inv "Global Positioning System Time : Precise Positioning System Time of Day Invalid";
BA_ "SignalLongName" SG_ 727 GPSV_PPSCalcdSpd "Global Positioning System Velocity : Precise Positioning System Calculated Speed";
BA_ "SignalLongName" SG_ 727 GPSV_PPSElvtn "Global Positioning System Velocity : Precise Positioning System Elevation";
BA_ "SignalType" SG_ 727 GPSV_PPSCalcdSpd_Inv "ENM";
BA_ "SignalLongName" SG_ 727 GPSV_PPSCalcdSpd_Inv "Global Positioning System Velocity : Precise Positioning System Calculated Speed Invalid";
BA_ "SignalLongName" SG_ 727 GPSV_PPSHdg "Global Positioning System Velocity : Precise Positioning System Heading";
BA_ "SignalType" SG_ 727 GPSV_PPSElvtn_Inv "ENM";
BA_ "SignalLongName" SG_ 727 GPSV_PPSElvtn_Inv "Global Positioning System Velocity : Precise Positioning System Elevation Invalid";
BA_ "SignalType" SG_ 727 GPSV_PPSHdg_Inv "ENM";
BA_ "SignalLongName" SG_ 727 GPSV_PPSHdg_Inv "Global Positioning System Velocity : Precise Positioning System Heading Invalid";
BA_ "SignalLongName" SG_ 1360 HMIGenInfo3_PCSM "HMI General Information 3 Protected Counter Sync Messsage";
BA_ "SignalLongName" SG_ 1305 HMIGI3P_MAC "HMI General Information 3 Protected : MAC";
BA_ "SignalLongName" SG_ 1305 HMIGI3P_FCnt "HMI General Information 3 Protected : Freshness Counter";
BA_ "SignalType" SG_ 1305 CntrStckDispFlrIndOn "ENM";
BA_ "SignalLongName" SG_ 1305 CntrStckDispFlrIndOn "HMI General Information 3 Protected : Center Stack Display Failure Indication On";
BA_ "SignalType" SG_ 1305 VirtCtlAuxAlrmSnsrReqAuth "ENM";
BA_ "SignalLongName" SG_ 1305 VirtCtlAuxAlrmSnsrReqAuth "HMI General Information 3 Protected : Virtual Control Auxiliary Alarm Sensor Request Authenticated";
BA_ "SignalLongName" SG_ 1305 HMIGI3P_ARC "HMI General Information 3 Protected : Alive Rolling Count";
BA_ "SignalType" SG_ 1305 HMIGI3P_VirtCtlHdPrkLmpsReqAuth "ENM";
BA_ "SignalLongName" SG_ 1305 HMIGI3P_VirtCtlHdPrkLmpsReqAuth "HMI General Information 3 Protected : Virtual Control Head and Park Lamps Request Authenticated";
BA_ "SignalType" SG_ 1305 InfoWndMtnRRReq "ENM";
BA_ "SignalLongName" SG_ 1305 InfoWndMtnRRReq "HMI General Information 3 Protected : DEPRECATED VIP 24 - Infotainment Window Motion Right Rear Request";
BA_ "SignalType" SG_ 1305 InfoWndMtnLRReq "ENM";
BA_ "SignalLongName" SG_ 1305 InfoWndMtnLRReq "HMI General Information 3 Protected : DEPRECATED VIP 24 - Infotainment Window Motion Left Rear Request";
BA_ "SignalType" SG_ 1305 InfoWndMtnRFReq "ENM";
BA_ "SignalLongName" SG_ 1305 InfoWndMtnRFReq "HMI General Information 3 Protected : DEPRECATED VIP 24 - Infotainment Window Motion Right Front Request";
BA_ "SignalType" SG_ 1305 InfoWndMtnLFReq "ENM";
BA_ "SignalLongName" SG_ 1305 InfoWndMtnLFReq "HMI General Information 3 Protected : DEPRECATED VIP 24 - Infotainment Window Motion Left Front Request";
BA_ "SignalType" SG_ 1305 VirtCtlVehOnExtModeSwReqd "ENM";
BA_ "SignalLongName" SG_ 1305 VirtCtlVehOnExtModeSwReqd "HMI General Information 3 Protected : Virtual Control Vehicle On Extend Mode Switch Requested";
BA_ "SignalType" SG_ 1305 VirtCtlVehEmrgOffSwReqd "ENM";
BA_ "SignalLongName" SG_ 1305 VirtCtlVehEmrgOffSwReqd "HMI General Information 3 Protected : Virtual Control Vehicle Emergency Off Switch Requested";
BA_ "SignalType" SG_ 1305 VirtCtlVehOffSwReq "ENM";
BA_ "SignalLongName" SG_ 1305 VirtCtlVehOffSwReq "HMI General Information 3 Protected : Virtual Control Vehicle Off Switch Request";
BA_ "SignalType" SG_ 1305 InfoSnrfPstnReq "ENM";
BA_ "SignalLongName" SG_ 1305 InfoSnrfPstnReq "HMI General Information 3 Protected : Infotainment Sunroof Position Request";
BA_ "SignalLongName" SG_ 1305 HMIGI3P_Filler "HMI General Information 3 Protected : Filler";
BA_ "SignalType" SG_ 1305 InfoWndPstnRRReqActv "ENM";
BA_ "SignalLongName" SG_ 1305 InfoWndPstnRRReqActv "HMI General Information 3 Protected : Infotainment Window Position Right Rear Request Active";
BA_ "SignalLongName" SG_ 1305 InfoWndPstnRRReq "HMI General Information 3 Protected : Infotainment Window Position Right Rear Request";
BA_ "SignalLongName" SG_ 1385 HMIInds1_PCSM "HMI Indications 1 Protected Counter Sync Message";
BA_ "SignalLongName" SG_ 1315 HMII1P_MAC "HMI Indications 1 Protected : MAC";
BA_ "SignalLongName" SG_ 1315 HMII1P_FCnt "HMI Indications 1 Protected : Freshness Counter";
BA_ "SignalType" SG_ 1315 HMII1P_LnFllwgChInterFltDtdAuth "ENM";
BA_ "SignalLongName" SG_ 1315 HMII1P_LnFllwgChInterFltDtdAuth "HMI Indications 1 Protected : Lane Following Chime Interface Fault Detected Authenticated";
BA_ "SignalType" SG_ 1315 HMII1P_IPCDispStsAuth "ENM";
BA_ "SignalLongName" SG_ 1315 HMII1P_IPCDispStsAuth "HMI Indications 1 Protected : IPC Display Status Authenticated";
BA_ "SignalType" SG_ 1315 HMII1P_ChmSysSOHAuth "ENM";
BA_ "SignalLongName" SG_ 1315 HMII1P_ChmSysSOHAuth "HMI Indications 1 Protected : Chime System State of Health Authenticated";
BA_ "SignalType" SG_ 1315 HMII1P_AutoModeSpdLimCnfrmdAuth "ENM";
BA_ "SignalLongName" SG_ 1315 HMII1P_AutoModeSpdLimCnfrmdAuth "HMI Indications 1 Protected : Auto Mode Speed Limit Confirmed Authenticated";
BA_ "SignalType" SG_ 1315 HMII1P_ACCSetTypAuth "ENM";
BA_ "SignalLongName" SG_ 1315 HMII1P_ACCSetTypAuth "HMI Indications 1 Protected : Adaptive Cruise Control Setting Type Authenticated";
BA_ "SignalLongName" SG_ 1315 InfoWndPstnLFReq "HMI Indications 1 Protected : Infotainment Window Position Left Front Request";
BA_ "SignalLongName" SG_ 1315 HMII1P_ARC "HMI Indications 1 Protected : Alive Rolling Count";
BA_ "SignalLongName" SG_ 1315 InfoWndPstnRFReq "HMI Indications 1 Protected : Infotainment Window Position Right Front Request";
BA_ "SignalLongName" SG_ 1315 InfoWndPstnLRReq "HMI Indications 1 Protected : Infotainment Window Position Left Rear Request";
BA_ "SignalLongName" SG_ 1315 HMII1P_Filler "HMI Indications 1 Protected : Filler";
BA_ "SignalType" SG_ 1315 InfoWndPstnRFReqActv "ENM";
BA_ "SignalLongName" SG_ 1315 InfoWndPstnRFReqActv "HMI Indications 1 Protected : Infotainment Window Position Right Front Request Active";
BA_ "SignalType" SG_ 1315 InfoWndPstnLRReqActv "ENM";
BA_ "SignalLongName" SG_ 1315 InfoWndPstnLRReqActv "HMI Indications 1 Protected : Infotainment Window Position Left Rear Request Active";
BA_ "SignalType" SG_ 1315 InfoWndPstnLFReqActv "ENM";
BA_ "SignalLongName" SG_ 1315 InfoWndPstnLFReqActv "HMI Indications 1 Protected : Infotainment Window Position Left Front Request Active";
BA_ "SignalLongName" SG_ 1447 HVACFCRADSCF_LtRwVltg "HVAC Front Controls Request Air Distribution Setting Change Front : Left Raw Voltage";
BA_ "SignalType" SG_ 1447 HVACFCRADSCF_LtChgNext "ENM";
BA_ "SignalLongName" SG_ 1447 HVACFCRADSCF_LtChgNext "HVAC Front Controls Request Air Distribution Setting Change Front : Left Change Next";
BA_ "SignalLongName" SG_ 1447 HVACFCRADSCF_RtRwVltg "HVAC Front Controls Request Air Distribution Setting Change Front : Right Raw Voltage";
BA_ "SignalType" SG_ 1447 HVACFCRADSCF_RtChgNext "ENM";
BA_ "SignalLongName" SG_ 1447 HVACFCRADSCF_RtChgNext "HVAC Front Controls Request Air Distribution Setting Change Front : Right Change Next";
BA_ "SignalLongName" SG_ 1447 HVACFrtCtlRqTmpLvlChgFLRwVltgHi "HVAC Front Controls Request Air Distribution Setting Change Front : HVAC Front Controls Request Temperature Level Change Front Left Raw Voltage High";
BA_ "SignalLongName" SG_ 1447 HVACFrtCtlRqTmpLvlChgFLRwVltgLo "HVAC Front Controls Request Air Distribution Setting Change Front : HVAC Front Controls Request Temperature Level Change Front Left Raw Voltage Low";
BA_ "SignalLongName" SG_ 1447 HVACFCRADSCF_CS "HVAC Front Controls Request Air Distribution Setting Change Front : Checksum";
BA_ "SignalLongName" SG_ 1447 HVACFCRADSCF_ARC "HVAC Front Controls Request Air Distribution Setting Change Front : Alive Rolling Count";
BA_ "SignalLongName" SG_ 1448 HVACFCRADSF_Lt4Rt1RwVltg "HVAC Front Controls Request Air Distribution Setting Front : Left Raw Voltage 4 / Right Raw Voltage 1";
BA_ "SignalLongName" SG_ 1448 HVACFCRADSF_LtRwVltg1 "HVAC Front Controls Request Air Distribution Setting Front : Left Raw Voltage 1";
BA_ "SignalLongName" SG_ 1448 HVACFCRADSF_LtRwVltg2 "HVAC Front Controls Request Air Distribution Setting Front : Left Raw Voltage 2";
BA_ "SignalLongName" SG_ 1448 HVACFCRADSF_LtRwVltg3 "HVAC Front Controls Request Air Distribution Setting Front : Left Raw Voltage 3";
BA_ "SignalLongName" SG_ 1448 HVACFCRADSF_RtRwVltg2 "HVAC Front Controls Request Air Distribution Setting Front : Right Raw Voltage 2";
BA_ "SignalType" SG_ 1448 HVACFCRADSF_LtSet "ENM";
BA_ "SignalLongName" SG_ 1448 HVACFCRADSF_LtSet "HVAC Front Controls Request Air Distribution Setting Front : Left Setting";
BA_ "SignalType" SG_ 1448 HVACFCRADSF_RtSet "ENM";
BA_ "SignalLongName" SG_ 1448 HVACFCRADSF_RtSet "HVAC Front Controls Request Air Distribution Setting Front : Right Setting";
BA_ "SignalLongName" SG_ 1448 HVACFCRADSF_CS "HVAC Front Controls Request Air Distribution Setting Front : Checksum";
BA_ "SignalLongName" SG_ 1448 HVACFCRADSF_ARC "HVAC Front Controls Request Air Distribution Setting Front : Alive Rolling Count";
BA_ "SignalLongName" SG_ 1450 HVACFCRBLCFOR_ORX1 "HVAC Front Controls Request Blower Level Change Front Out of Range : Out of Range X 1";
BA_ "SignalLongName" SG_ 1450 HVACFCRBLCFOR_ORX2 "HVAC Front Controls Request Blower Level Change Front Out of Range : Out of Range X 2";
BA_ "SignalLongName" SG_ 1450 HVACFCRBLCFOR_ORY1 "HVAC Front Controls Request Blower Level Change Front Out of Range : Out of Range Y 1";
BA_ "SignalLongName" SG_ 1450 HVACFCRBLCFOR_ORY2 "HVAC Front Controls Request Blower Level Change Front Out of Range : Out of Range Y 2";
BA_ "SignalLongName" SG_ 1450 HVACFCRBLCFOR_CS "HVAC Front Controls Request Blower Level Change Front Out of Range : Checksum";
BA_ "SignalLongName" SG_ 1450 HVACFCRBLCFOR_ARC "HVAC Front Controls Request Blower Level Change Front Out of Range : Alive Rolling Count";
BA_ "SignalType" SG_ 1449 HVACFCRBLCF_ORH1 "ENM";
BA_ "SignalLongName" SG_ 1449 HVACFCRBLCF_ORH1 "HVAC Front Controls Request Blower Level Change Front : Out of Range High 1";
BA_ "SignalLongName" SG_ 1449 HVACFCRBLCF_LvlChg "HVAC Front Controls Request Blower Level Change Front : Level Change";
BA_ "SignalType" SG_ 1449 HVACFCRBLCF_CktCorr "ENM";
BA_ "SignalLongName" SG_ 1449 HVACFCRBLCF_CktCorr "HVAC Front Controls Request Blower Level Change Front : Circuit Correlation";
BA_ "SignalLongName" SG_ 1449 HVACFCRBLCF_RwVltg1 "HVAC Front Controls Request Blower Level Change Front : Raw Voltage 1";
BA_ "SignalType" SG_ 1449 HVACFCRBLCF_ORL2 "ENM";
BA_ "SignalLongName" SG_ 1449 HVACFCRBLCF_ORL2 "HVAC Front Controls Request Blower Level Change Front : Out of Range Low 2";
BA_ "SignalType" SG_ 1449 HVACFCRBLCF_ORL1 "ENM";
BA_ "SignalLongName" SG_ 1449 HVACFCRBLCF_ORL1 "HVAC Front Controls Request Blower Level Change Front : Out of Range Low 1";
BA_ "SignalType" SG_ 1449 HVACFCRBLCF_ORH2 "ENM";
BA_ "SignalLongName" SG_ 1449 HVACFCRBLCF_ORH2 "HVAC Front Controls Request Blower Level Change Front : Out of Range High 2";
BA_ "SignalLongName" SG_ 1449 HVACFCRBLCF_RwVltg2 "HVAC Front Controls Request Blower Level Change Front : Raw Voltage 2";
BA_ "SignalLongName" SG_ 1449 HVACFCRBLCF_CS "HVAC Front Controls Request Blower Level Change Front : Checksum";
BA_ "SignalLongName" SG_ 1449 HVACFCRBLCF_ARC "HVAC Front Controls Request Blower Level Change Front : Alive Rolling Count";
BA_ "SignalLongName" SG_ 1451 HVACFCRBLF_RwVltg "HVAC Front Controls Request Blower Level Front : Raw Voltage";
BA_ "SignalType" SG_ 1451 HVACFCRBLF_LvlActv "ENM";
BA_ "SignalLongName" SG_ 1451 HVACFCRBLF_LvlActv "HVAC Front Controls Request Blower Level Front : Level Active";
BA_ "SignalLongName" SG_ 1451 HVACFCRBLF_Lvl "HVAC Front Controls Request Blower Level Front : Level";
BA_ "SignalLongName" SG_ 1451 HVACFrtCtlReqBlwLvlFrtRwVltgHi "HVAC Front Controls Request Blower Level Front : HVAC Front Controls Request Blower Level Front Raw Voltage High";
BA_ "SignalLongName" SG_ 1451 HVACFrtCtlReqBlwLvlFrtRwVltgLo "HVAC Front Controls Request Blower Level Front : HVAC Front Controls Request Blower Level Front Raw Voltage Low";
BA_ "SignalLongName" SG_ 1451 HVACFCRBLF_CS "HVAC Front Controls Request Blower Level Front : Checksum";
BA_ "SignalLongName" SG_ 1451 HVACFCRBLF_ARC "HVAC Front Controls Request Blower Level Front : Alive Rolling Count";
BA_ "SignalLongName" SG_ 1452 HVACFCRDP_FrtDefrRwVltg "HVAC Front Controls Request Defrost and Power : Front Defrost Raw Voltage";
BA_ "SignalLongName" SG_ 1452 HVACFCRDP_HtdFrtWshldRwVltg "HVAC Front Controls Request Defrost and Power : Heated Front Windshield Raw Voltage";
BA_ "SignalType" SG_ 1452 HVACFCRDP_FrtPwrSetChg_Inv "ENM";
BA_ "SignalLongName" SG_ 1452 HVACFCRDP_FrtPwrSetChg_Inv "HVAC Front Controls Request Defrost and Power : Front Power Setting Change Invalid";
BA_ "SignalType" SG_ 1452 HVACFCRDP_FrtPwrSetChg "ENM";
BA_ "SignalLongName" SG_ 1452 HVACFCRDP_FrtPwrSetChg "HVAC Front Controls Request Defrost and Power : Front Power Setting Change";
BA_ "SignalType" SG_ 1452 HVACFCRDP_IntrnlFltSts "ENM";
BA_ "SignalLongName" SG_ 1452 HVACFCRDP_IntrnlFltSts "HVAC Front Controls Request Defrost and Power : Internal Fault Status";
BA_ "SignalType" SG_ 1452 HVACFCRDP_InitFin "ENM";
BA_ "SignalLongName" SG_ 1452 HVACFCRDP_InitFin "HVAC Front Controls Request Defrost and Power : Initialization Finished";
BA_ "SignalType" SG_ 1452 HVACFCRDP_HtdFrtWshldSetChgd "ENM";
BA_ "SignalLongName" SG_ 1452 HVACFCRDP_HtdFrtWshldSetChgd "HVAC Front Controls Request Defrost and Power : Heated Front Windshield Setting Changed";
BA_ "SignalType" SG_ 1452 HVACFCRDP_MaxDefrSetChg "ENM";
BA_ "SignalLongName" SG_ 1452 HVACFCRDP_MaxDefrSetChg "HVAC Front Controls Request Defrost and Power : Max Defrost Setting Change";
BA_ "SignalLongName" SG_ 1452 HVACFCRDP_CS "HVAC Front Controls Request Defrost and Power : Checksum";
BA_ "SignalLongName" SG_ 1452 HVACFCRDP_ARC "HVAC Front Controls Request Defrost and Power : Alive Rolling Count";
BA_ "SignalLongName" SG_ 1453 HVACFCRRFA_FrshAirRwVltg "HVAC Front Controls Request Recirculation and Front Auto : Fresh Air Raw Voltage";
BA_ "SignalLongName" SG_ 1453 HVACFCRRFA_FrtAutoRwVltg "HVAC Front Controls Request Recirculation and Front Auto : Front Auto Raw Voltage";
BA_ "SignalType" SG_ 1453 HVACFCRRFA_FrshAirSetChg "ENM";
BA_ "SignalLongName" SG_ 1453 HVACFCRRFA_FrshAirSetChg "HVAC Front Controls Request Recirculation and Front Auto : Fresh Air Setting Change";
BA_ "SignalLongName" SG_ 1453 HVACFCRRFA_RecircRwVltg1 "HVAC Front Controls Request Recirculation and Front Auto : Recirculation Raw Voltage 1";
BA_ "SignalType" SG_ 1453 HVACFCRRFA_FrtAutoSetChg "ENM";
BA_ "SignalLongName" SG_ 1453 HVACFCRRFA_FrtAutoSetChg "HVAC Front Controls Request Recirculation and Front Auto : Front Auto Setting Change";
BA_ "SignalLongName" SG_ 1453 HVACFCRRFA_RecircRwVltg2 "HVAC Front Controls Request Recirculation and Front Auto : Recirculation Raw Voltage 2";
BA_ "SignalType" SG_ 1453 HVACFCRRFA_RecircSetChg "ENM";
BA_ "SignalLongName" SG_ 1453 HVACFCRRFA_RecircSetChg "HVAC Front Controls Request Recirculation and Front Auto : Recirculation Setting Change";
BA_ "SignalLongName" SG_ 1453 HVACFCRRFA_CS "HVAC Front Controls Request Recirculation and Front Auto : Checksum";
BA_ "SignalLongName" SG_ 1453 HVACFCRRFA_ARC "HVAC Front Controls Request Recirculation and Front Auto : Alive Rolling Count";
BA_ "SignalLongName" SG_ 1455 HVACFCRTLCFLOR1n2_ORX1 "HVAC Front Controls Request Temperature Level Change Front Left Out of Range 1 and 2 : Out of Range X 1";
BA_ "SignalLongName" SG_ 1455 HVACFCRTLCFLOR1n2_ORX2 "HVAC Front Controls Request Temperature Level Change Front Left Out of Range 1 and 2 : Out of Range X 2";
BA_ "SignalLongName" SG_ 1455 HVACFCRTLCFLOR1n2_ORY1 "HVAC Front Controls Request Temperature Level Change Front Left Out of Range 1 and 2 : Out of Range Y 1";
BA_ "SignalLongName" SG_ 1455 HVACFCRTLCFLOR1n2_ORY2 "HVAC Front Controls Request Temperature Level Change Front Left Out of Range 1 and 2 : Out of Range Y 2";
BA_ "SignalLongName" SG_ 1455 HVACFCRTLCFLOR1n2_CS "HVAC Front Controls Request Temperature Level Change Front Left Out of Range 1 and 2 : Checksum";
BA_ "SignalLongName" SG_ 1455 HVACFCRTLCFLOR1n2_ARC "HVAC Front Controls Request Temperature Level Change Front Left Out of Range 1 and 2 : Alive Rolling Count";
BA_ "SignalLongName" SG_ 1454 HVACFCRTLCFL_LvlChg "HVAC Front Controls Request Temperature Level Change Front Left : Left Level Change";
BA_ "SignalType" SG_ 1454 HVACFCRTLCFL_CktCorr "ENM";
BA_ "SignalLongName" SG_ 1454 HVACFCRTLCFL_CktCorr "HVAC Front Controls Request Temperature Level Change Front Left : Circuit Correlation";
BA_ "SignalLongName" SG_ 1454 HVACFCRTLCFL_RwVltg1 "HVAC Front Controls Request Temperature Level Change Front Left : Raw Voltage 1";
BA_ "SignalType" SG_ 1454 HVACFCRTLCFL_ORL3 "ENM";
BA_ "SignalLongName" SG_ 1454 HVACFCRTLCFL_ORL3 "HVAC Front Controls Request Temperature Level Change Front Left : Out of Range Low 3";
BA_ "SignalType" SG_ 1454 HVACFCRTLCFL_ORL2 "ENM";
BA_ "SignalLongName" SG_ 1454 HVACFCRTLCFL_ORL2 "HVAC Front Controls Request Temperature Level Change Front Left : Out of Range Low 2";
BA_ "SignalType" SG_ 1454 HVACFCRTLCFL_ORL1 "ENM";
BA_ "SignalLongName" SG_ 1454 HVACFCRTLCFL_ORL1 "HVAC Front Controls Request Temperature Level Change Front Left : Out of Range Low 1";
BA_ "SignalType" SG_ 1454 HVACFCRTLCFL_ORH3 "ENM";
BA_ "SignalLongName" SG_ 1454 HVACFCRTLCFL_ORH3 "HVAC Front Controls Request Temperature Level Change Front Left : Out of Range High 3";
BA_ "SignalType" SG_ 1454 HVACFCRTLCFL_ORH2 "ENM";
BA_ "SignalLongName" SG_ 1454 HVACFCRTLCFL_ORH2 "HVAC Front Controls Request Temperature Level Change Front Left : Out of Range High 2";
BA_ "SignalType" SG_ 1454 HVACFCRTLCFL_ORH1 "ENM";
BA_ "SignalLongName" SG_ 1454 HVACFCRTLCFL_ORH1 "HVAC Front Controls Request Temperature Level Change Front Left : Out of Range High 1";
BA_ "SignalLongName" SG_ 1454 HVACFCRTLCFL_RwVltg2 "HVAC Front Controls Request Temperature Level Change Front Left : Raw Voltage 2";
BA_ "SignalLongName" SG_ 1454 HVACFCRTLCFL_RwVltg3 "HVAC Front Controls Request Temperature Level Change Front Left : Raw Voltage 3";
BA_ "SignalLongName" SG_ 1454 HVACFCRTLCFL_CS "HVAC Front Controls Request Temperature Level Change Front Left : Checksum";
BA_ "SignalLongName" SG_ 1454 HVACFCRTLCFL_ARC "HVAC Front Controls Request Temperature Level Change Front Left : Alive Rolling Count";
BA_ "SignalLongName" SG_ 1456 HVACFCRTLCFOR3_LtORX3 "HVAC Front Controls Request Temperature Level Change Front Out of Range 3 : Left Out of Range X 3";
BA_ "SignalLongName" SG_ 1456 HVACFCRTLCFOR3_LtORY3 "HVAC Front Controls Request Temperature Level Change Front Out of Range 3 : Left Out of Range Y 3";
BA_ "SignalLongName" SG_ 1456 HVACFCRTLCFOR3_RtORX3 "HVAC Front Controls Request Temperature Level Change Front Out of Range 3 : Right Out of Range X 3";
BA_ "SignalLongName" SG_ 1456 HVACFCRTLCFOR3_RtORY3 "HVAC Front Controls Request Temperature Level Change Front Out of Range 3 : Right Out of Range Y 3";
BA_ "SignalLongName" SG_ 1456 HVACFCRTLCFOR3_CS "HVAC Front Controls Request Temperature Level Change Front Out of Range 3 : Checksum";
BA_ "SignalLongName" SG_ 1456 HVACFCRTLCFOR3_ARC "HVAC Front Controls Request Temperature Level Change Front Out of Range 3 : Alive Rolling Count";
BA_ "SignalLongName" SG_ 1458 HVACFCRTLCFROR1n2_ORX1 "HVAC Front Controls Request Temperature Level Change Front Right Out of Range 1 and 2 : Out of Range X 1";
BA_ "SignalLongName" SG_ 1458 HVACFCRTLCFROR1n2_ORX2 "HVAC Front Controls Request Temperature Level Change Front Right Out of Range 1 and 2 : Out of Range X 2";
BA_ "SignalLongName" SG_ 1458 HVACFCRTLCFROR1n2_ORY1 "HVAC Front Controls Request Temperature Level Change Front Right Out of Range 1 and 2 : Out of Range Y 1";
BA_ "SignalLongName" SG_ 1458 HVACFCRTLCFROR1n2_ORY2 "HVAC Front Controls Request Temperature Level Change Front Right Out of Range 1 and 2 : Out of Range Y 2";
BA_ "SignalLongName" SG_ 1458 HVACFCRTLCFROR1n2_CS "HVAC Front Controls Request Temperature Level Change Front Right Out of Range 1 and 2 : Checksum";
BA_ "SignalLongName" SG_ 1458 HVACFCRTLCFROR1n2_ARC "HVAC Front Controls Request Temperature Level Change Front Right Out of Range 1 and 2 : Alive Rolling Count";
BA_ "SignalLongName" SG_ 1457 HVACFCRTLCFR_LvlChg "HVAC Front Controls Request Temperature Level Change Front Right : Level Change";
BA_ "SignalType" SG_ 1457 HVACFCRTLCFR_CktCorr "ENM";
BA_ "SignalLongName" SG_ 1457 HVACFCRTLCFR_CktCorr "HVAC Front Controls Request Temperature Level Change Front Right : Circuit Correlation";
BA_ "SignalLongName" SG_ 1457 HVACFCRTLCFR_RwVltg1 "HVAC Front Controls Request Temperature Level Change Front Right : Raw Voltage 1";
BA_ "SignalType" SG_ 1457 HVACFCRTLCFR_ORL3 "ENM";
BA_ "SignalLongName" SG_ 1457 HVACFCRTLCFR_ORL3 "HVAC Front Controls Request Temperature Level Change Front Right : Out of Range Low 3";
BA_ "SignalType" SG_ 1457 HVACFCRTLCFR_ORL2 "ENM";
BA_ "SignalLongName" SG_ 1457 HVACFCRTLCFR_ORL2 "HVAC Front Controls Request Temperature Level Change Front Right : Out of Range Low 2";
BA_ "SignalType" SG_ 1457 HVACFCRTLCFR_ORL1 "ENM";
BA_ "SignalLongName" SG_ 1457 HVACFCRTLCFR_ORL1 "HVAC Front Controls Request Temperature Level Change Front Right : Out of Range Low 1";
BA_ "SignalType" SG_ 1457 HVACFCRTLCFR_ORH3 "ENM";
BA_ "SignalLongName" SG_ 1457 HVACFCRTLCFR_ORH3 "HVAC Front Controls Request Temperature Level Change Front Right : Out of Range High 3";
BA_ "SignalType" SG_ 1457 HVACFCRTLCFR_ORH2 "ENM";
BA_ "SignalLongName" SG_ 1457 HVACFCRTLCFR_ORH2 "HVAC Front Controls Request Temperature Level Change Front Right : Out of Range High 2";
BA_ "SignalType" SG_ 1457 HVACFCRTLCFR_ORH1 "ENM";
BA_ "SignalLongName" SG_ 1457 HVACFCRTLCFR_ORH1 "HVAC Front Controls Request Temperature Level Change Front Right : Out of Range High 1";
BA_ "SignalLongName" SG_ 1457 HVACFCRTLCFR_RwVltg2 "HVAC Front Controls Request Temperature Level Change Front Right : Raw Voltage 2";
BA_ "SignalLongName" SG_ 1457 HVACFCRTLCFR_RwVltg3 "HVAC Front Controls Request Temperature Level Change Front Right : Raw Voltage 3";
BA_ "SignalLongName" SG_ 1457 HVACFCRTLCFR_CS "HVAC Front Controls Request Temperature Level Change Front Right : Checksum";
BA_ "SignalLongName" SG_ 1457 HVACFCRTLCFR_ARC "HVAC Front Controls Request Temperature Level Change Front Right : Alive Rolling Count";
BA_ "SignalType" SG_ 1459 HVACFCRTLF_LtLvlActv "ENM";
BA_ "SignalLongName" SG_ 1459 HVACFCRTLF_LtLvlActv "HVAC Front Controls Request Temperature Level Front : Left Level Active";
BA_ "SignalLongName" SG_ 1459 HVACFCRTLF_LtLvl "HVAC Front Controls Request Temperature Level Front : Left Level";
BA_ "SignalLongName" SG_ 1459 HVACFCRTLF_LtRwVltg "HVAC Front Controls Request Temperature Level Front : Left Raw Voltage";
BA_ "SignalLongName" SG_ 1459 HVACFCRTLF_RtLvl "HVAC Front Controls Request Temperature Level Front : Right Level";
BA_ "SignalLongName" SG_ 1459 HVACFCRTLF_RtRwVltg "HVAC Front Controls Request Temperature Level Front : Right Raw Voltage";
BA_ "SignalType" SG_ 1459 HVACFCRTLF_RtLvlActv "ENM";
BA_ "SignalLongName" SG_ 1459 HVACFCRTLF_RtLvlActv "HVAC Front Controls Request Temperature Level Front : Right Level Active";
BA_ "SignalLongName" SG_ 1459 HVACFCRTLF_CS "HVAC Front Controls Request Temperature Level Front : Checksum";
BA_ "SignalLongName" SG_ 1459 HVACFCRTLF_ARC "HVAC Front Controls Request Temperature Level Front : Alive Rolling Count";
BA_ "SignalLongName" SG_ 1460 HVACFCRTLCFLI2_ORX4 "HVAC Front Controls Request Temperature Level Change Front Left Information 2 : Out of Range X4";
BA_ "SignalType" SG_ 1460 HVACFCRTLCFLI2_ORL4 "ENM";
BA_ "SignalLongName" SG_ 1460 HVACFCRTLCFLI2_ORL4 "HVAC Front Controls Request Temperature Level Change Front Left Information 2 : Out of Range Low 4";
BA_ "SignalType" SG_ 1460 HVACFCRTLCFLI2_ORH4 "ENM";
BA_ "SignalLongName" SG_ 1460 HVACFCRTLCFLI2_ORH4 "HVAC Front Controls Request Temperature Level Change Front Left Information 2 : Out of Range High 4";
BA_ "SignalLongName" SG_ 1460 HVACFCRTLCFLI2_ORY4 "HVAC Front Controls Request Temperature Level Change Front Left Information 2 : Out of Range Y4";
BA_ "SignalLongName" SG_ 1460 HVACFCRTLCFLI2_RwVltg4 "HVAC Front Controls Request Temperature Level Change Front Left Information 2 : Raw Voltage 4";
BA_ "SignalLongName" SG_ 1460 HVACFCRTLCFLI2_CS "HVAC Front Controls Request Temperature Level Change Front Left Information 2 : Checksum";
BA_ "SignalLongName" SG_ 1460 HVACFCRTLCFLI2_ARC "HVAC Front Controls Request Temperature Level Change Front Left Information 2 : Alive Rolling Count";
BA_ "SignalLongName" SG_ 1461 HVACFCRTLCFRI2_ORX4 "HVAC Front Controls Request Temperature Level Change Front Right Information 2 : Out of Range X4";
BA_ "SignalType" SG_ 1461 HVACFCRTLCFRI2_ORL4 "ENM";
BA_ "SignalLongName" SG_ 1461 HVACFCRTLCFRI2_ORL4 "HVAC Front Controls Request Temperature Level Change Front Right Information 2 : Out of Range Low 4";
BA_ "SignalType" SG_ 1461 HVACFCRTLCFRI2_ORH4 "ENM";
BA_ "SignalLongName" SG_ 1461 HVACFCRTLCFRI2_ORH4 "HVAC Front Controls Request Temperature Level Change Front Right Information 2 : Out of Range High 4";
BA_ "SignalLongName" SG_ 1461 HVACFCRTLCFRI2_ORY4 "HVAC Front Controls Request Temperature Level Change Front Right Information 2 : Out of Range Y4";
BA_ "SignalLongName" SG_ 1461 HVACFCRTLCFRI2_RwVltg4 "HVAC Front Controls Request Temperature Level Change Front Right Information 2 : Raw Voltage 4";
BA_ "SignalLongName" SG_ 1461 HVACFCRTLCFRI2_CS "HVAC Front Controls Request Temperature Level Change Front Right Information 2 : Checksum";
BA_ "SignalLongName" SG_ 1461 HVACFCRTLCFRI2_ARC "HVAC Front Controls Request Temperature Level Change Front Right Information 2 : Alive Rolling Count";
BA_ "SignalLongName" SG_ 1462 HVACICR1_BlwLvlFrt "HVAC Infotainment Controls Request 1 : Blower Level Front";
BA_ "SignalLongName" SG_ 1462 HVACICR1_BlwLvlChgFrt "HVAC Infotainment Controls Request 1 : Blower Level Change Front";
BA_ "SignalType" SG_ 1462 HVACICR1_FrtRrPwrSet "ENM";
BA_ "SignalLongName" SG_ 1462 HVACICR1_FrtRrPwrSet "HVAC Infotainment Controls Request 1 : Front and Rear Power Setting";
BA_ "SignalType" SG_ 1462 HVACICR1_FrtPwrSetChg "ENM";
BA_ "SignalLongName" SG_ 1462 HVACICR1_FrtPwrSetChg "HVAC Infotainment Controls Request 1 : Front Power Setting Change";
BA_ "SignalType" SG_ 1462 HVACICR1_FrtAutoSetChg "ENM";
BA_ "SignalLongName" SG_ 1462 HVACICR1_FrtAutoSetChg "HVAC Infotainment Controls Request 1 : Front Auto Setting Change";
BA_ "SignalType" SG_ 1462 HVACICR1_CompSetChg "ENM";
BA_ "SignalLongName" SG_ 1462 HVACICR1_CompSetChg "HVAC Infotainment Controls Request 1 : Compressor Setting Change";
BA_ "SignalType" SG_ 1462 HVACICR1_CompSet "ENM";
BA_ "SignalLongName" SG_ 1462 HVACICR1_CompSet "HVAC Infotainment Controls Request 1 : Compressor Setting";
BA_ "SignalType" SG_ 1462 HVACICR1_BlwLvlFrtActv "ENM";
BA_ "SignalLongName" SG_ 1462 HVACICR1_BlwLvlFrtActv "HVAC Infotainment Controls Request 1 : Blower Level Front Active";
BA_ "SignalType" SG_ 1462 HVACICR1_IntrnlFltSts "ENM";
BA_ "SignalLongName" SG_ 1462 HVACICR1_IntrnlFltSts "HVAC Infotainment Controls Request 1 : Internal Fault Status";
BA_ "SignalType" SG_ 1462 HVACICR1_HtrSetChg "ENM";
BA_ "SignalLongName" SG_ 1462 HVACICR1_HtrSetChg "HVAC Infotainment Controls Request 1 : Heater Setting Change";
BA_ "SignalType" SG_ 1462 HVACICR1_HtrSet "ENM";
BA_ "SignalLongName" SG_ 1462 HVACICR1_HtrSet "HVAC Infotainment Controls Request 1 : Heater Setting";
BA_ "SignalType" SG_ 1462 HVACICR1_MaxDefrSetChg "ENM";
BA_ "SignalLongName" SG_ 1462 HVACICR1_MaxDefrSetChg "HVAC Infotainment Controls Request 1 : Max Defrost Setting Change";
BA_ "SignalType" SG_ 1462 HVACICR1_MaxDefrSet "ENM";
BA_ "SignalLongName" SG_ 1462 HVACICR1_MaxDefrSet "HVAC Infotainment Controls Request 1 : Max Defrost Setting";
BA_ "SignalLongName" SG_ 1462 HVACICR1_CS "HVAC Infotainment Controls Request 1 : Checksum";
BA_ "SignalType" SG_ 1462 HVACInfoCtlReqHtgACSetChg "ENM";
BA_ "SignalLongName" SG_ 1462 HVACInfoCtlReqHtgACSetChg "HVAC Infotainment Controls Request 1 : HVAC Infotainment Controls Request Heating and Air Conditioning Setting Change";
BA_ "SignalLongName" SG_ 1462 HVACICR1_ARC "HVAC Infotainment Controls Request 1 : Alive Rolling Count";
BA_ "SignalType" SG_ 1463 HVACICR2_AirDstRtChgPrev "ENM";
BA_ "SignalLongName" SG_ 1463 HVACICR2_AirDstRtChgPrev "HVAC Infotainment Controls Request 2 : Air Distribution Right Change Previous";
BA_ "SignalType" SG_ 1463 HVACICR2_AirDstRtChgNext "ENM";
BA_ "SignalLongName" SG_ 1463 HVACICR2_AirDstRtChgNext "HVAC Infotainment Controls Request 2 : Air Distribution Right Change Next";
BA_ "SignalType" SG_ 1463 HVACICR2_AirDstLtSet "ENM";
BA_ "SignalLongName" SG_ 1463 HVACICR2_AirDstLtSet "HVAC Infotainment Controls Request 2 : Air Distribution Left Setting";
BA_ "SignalType" SG_ 1463 HVACICR2_AirDstLtChgPrev "ENM";
BA_ "SignalLongName" SG_ 1463 HVACICR2_AirDstLtChgPrev "HVAC Infotainment Controls Request 2 : Air Distribution Left Change Previous";
BA_ "SignalType" SG_ 1463 HVACICR2_AirDstLtChgNext "ENM";
BA_ "SignalLongName" SG_ 1463 HVACICR2_AirDstLtChgNext "HVAC Infotainment Controls Request 2 : Air Distribution Left Change Next";
BA_ "SignalLongName" SG_ 1463 HVACICR2_TempLtLvl "HVAC Infotainment Controls Request 2 : Temperature Left Level";
BA_ "SignalType" SG_ 1463 HVACICR2_RecircSetChg "ENM";
BA_ "SignalLongName" SG_ 1463 HVACICR2_RecircSetChg "HVAC Infotainment Controls Request 2 : Recirculation Setting Change";
BA_ "SignalType" SG_ 1463 HVACICR2_RecircSet "ENM";
BA_ "SignalLongName" SG_ 1463 HVACICR2_RecircSet "HVAC Infotainment Controls Request 2 : Recirculation Setting";
BA_ "SignalType" SG_ 1463 HVACICR2_AirDstRtSet "ENM";
BA_ "SignalLongName" SG_ 1463 HVACICR2_AirDstRtSet "HVAC Infotainment Controls Request 2 : Air Distribution Right Setting";
BA_ "SignalLongName" SG_ 1463 HVACICR2_TempLtLvlChg "HVAC Infotainment Controls Request 2 : Temperature Left Level Change";
BA_ "SignalType" SG_ 1463 HVACICR2_TempLtLvlActv "ENM";
BA_ "SignalLongName" SG_ 1463 HVACICR2_TempLtLvlActv "HVAC Infotainment Controls Request 2 : Temperature Left Level Active";
BA_ "SignalLongName" SG_ 1463 HVACICR2_TempRtLvl "HVAC Infotainment Controls Request 2 : Temperature Right Level";
BA_ "SignalLongName" SG_ 1463 HVACICR2_TempRtLvlChg "HVAC Infotainment Controls Request 2 : Temperature Right Level Change";
BA_ "SignalType" SG_ 1463 HVACICR2_TempRtLvlActv "ENM";
BA_ "SignalLongName" SG_ 1463 HVACICR2_TempRtLvlActv "HVAC Infotainment Controls Request 2 : Temperature Right Level Active";
BA_ "SignalLongName" SG_ 1463 HVACICR2_CS "HVAC Infotainment Controls Request 2 : Checksum";
BA_ "SignalLongName" SG_ 1463 HVACICR2_ARC "HVAC Infotainment Controls Request 2 : Alive Rolling Count";
BA_ "SignalLongName" SG_ 1885 LclTmYrVal "Cellular Time Year Value";
BA_ "SignalType" SG_ 1885 LclTmYrVal_Inv "ENM";
BA_ "SignalLongName" SG_ 1885 LclTmYrVal_Inv "Cellular Time Year Value Invalid";
BA_ "SignalLongName" SG_ 1885 LclTmMinVal "Cellular Time Minutes Value";
BA_ "SignalType" SG_ 1885 LclTmMinVal_Inv "ENM";
BA_ "SignalLongName" SG_ 1885 LclTmMinVal_Inv "Cellular Time Minutes Value Invalid";
BA_ "SignalType" SG_ 1885 LclTmDayVal_Inv "ENM";
BA_ "SignalLongName" SG_ 1885 LclTmDayVal_Inv "Cellular Time Day Value Invalid";
BA_ "SignalLongName" SG_ 1885 LclTmSecVal "Cellular Time Seconds Value";
BA_ "SignalType" SG_ 1885 LclTmSecVal_Inv "ENM";
BA_ "SignalLongName" SG_ 1885 LclTmSecVal_Inv "Cellular Time Seconds Value Invalid";
BA_ "SignalLongName" SG_ 1885 LclTmHrVal "Cellular Time Hours Value";
BA_ "SignalType" SG_ 1885 LclTmHrVal_Inv "ENM";
BA_ "SignalLongName" SG_ 1885 LclTmHrVal_Inv "Cellular Time Hours Value Invalid";
BA_ "SignalLongName" SG_ 1885 LclTmDayVal "Cellular Time Day Value";
BA_ "SignalType" SG_ 1885 LclTmMthVal "ENM";
BA_ "SignalLongName" SG_ 1885 LclTmMthVal "Cellular Time Month Value";
BA_ "SignalType" SG_ 1885 LclTmMthVal_Inv "ENM";
BA_ "SignalLongName" SG_ 1885 LclTmMthVal_Inv "Cellular Time Month Value Invalid";
BA_ "SignalLongName" SG_ 1439 FrtCntrStckEncdr4 "Front Center Stack Encoder 4";
BA_ "SignalLongName" SG_ 1439 FrtCntrStckEncdr5 "Front Center Stack Encoder 5";
BA_ "SignalLongName" SG_ 1439 FrtCntrStckMenuEncdr "Front Center Stack Menu Encoder";
BA_ "SignalLongName" SG_ 1439 FrtCntrStckTuneEncdr "Front Center Stack Tune Encoder";
BA_ "SignalLongName" SG_ 1439 FrtCntrStckVolEncdr "Front Center Stack Volume Encoder";
BA_ "SignalType" SG_ 1439 FrtCntrStckFvrtUpSw "ENM";
BA_ "SignalLongName" SG_ 1439 FrtCntrStckFvrtUpSw "Front Center Stack Favorites Up Switch";
BA_ "SignalType" SG_ 1439 FrtCntrStckFvrtDnSw "ENM";
BA_ "SignalLongName" SG_ 1439 FrtCntrStckFvrtDnSw "Front Center Stack Favorites Down Switch";
BA_ "SignalType" SG_ 1439 FrtCntrStckEjectSw "ENM";
BA_ "SignalLongName" SG_ 1439 FrtCntrStckEjectSw "Front Center Stack Eject Switch";
BA_ "SignalType" SG_ 1439 FrtCntrStckDiscAuxSw "ENM";
BA_ "SignalLongName" SG_ 1439 FrtCntrStckDiscAuxSw "Front Center Stack Disc Auxiliary Switch";
BA_ "SignalType" SG_ 1439 FrtCntrStckBndSw "ENM";
BA_ "SignalLongName" SG_ 1439 FrtCntrStckBndSw "Front Center Stack Band Switch";
BA_ "SignalType" SG_ 1439 FrtCntrStckBnchBtnID_VirtSw "ENM";
BA_ "SignalLongName" SG_ 1439 FrtCntrStckBnchBtnID_VirtSw "Front Center Stack Bench Button ID Virtual Switch";
BA_ "SignalType" SG_ 1439 FrtCntrStckBackSw "ENM";
BA_ "SignalLongName" SG_ 1439 FrtCntrStckBackSw "Front Center Stack Back Switch";
BA_ "SignalType" SG_ 1439 FrtCntrStckAllRelSw "ENM";
BA_ "SignalLongName" SG_ 1439 FrtCntrStckAllRelSw "Front Center Stack All Release Switch";
BA_ "SignalType" SG_ 1439 FrtCntrStckSw24 "ENM";
BA_ "SignalLongName" SG_ 1439 FrtCntrStckSw24 "Front Center Stack Switch 24";
BA_ "SignalType" SG_ 1439 FrtCntrStckSw23 "ENM";
BA_ "SignalLongName" SG_ 1439 FrtCntrStckSw23 "Front Center Stack Switch 23";
BA_ "SignalType" SG_ 1439 FrtCntrStckStrgeUnlckSw "ENM";
BA_ "SignalLongName" SG_ 1439 FrtCntrStckStrgeUnlckSw "Front Center Stack Storage Unlock Switch";
BA_ "SignalType" SG_ 1439 FrtCntrStckPwrSw "ENM";
BA_ "SignalLongName" SG_ 1439 FrtCntrStckPwrSw "Front Center Stack Power Switch";
BA_ "SignalType" SG_ 1439 FrtCntrStckPrevSw "ENM";
BA_ "SignalLongName" SG_ 1439 FrtCntrStckPrevSw "Front Center Stack Previous Switch";
BA_ "SignalType" SG_ 1439 FrtCntrStckNextSw "ENM";
BA_ "SignalLongName" SG_ 1439 FrtCntrStckNextSw "Front Center Stack Next Switch";
BA_ "SignalType" SG_ 1439 FrtCntrStckMenuSw "ENM";
BA_ "SignalLongName" SG_ 1439 FrtCntrStckMenuSw "Front Center Stack Menu Switch";
BA_ "SignalType" SG_ 1439 FrtCntrStckHomeSw "ENM";
BA_ "SignalLongName" SG_ 1439 FrtCntrStckHomeSw "Front Center Stack Home Switch";
BA_ "SignalType" SG_ 1439 FrtCntrStckSw32 "ENM";
BA_ "SignalLongName" SG_ 1439 FrtCntrStckSw32 "Front Center Stack Switch 32";
BA_ "SignalType" SG_ 1439 FrtCntrStckSw31 "ENM";
BA_ "SignalLongName" SG_ 1439 FrtCntrStckSw31 "Front Center Stack Switch 31";
BA_ "SignalType" SG_ 1439 FrtCntrStckSw30 "ENM";
BA_ "SignalLongName" SG_ 1439 FrtCntrStckSw30 "Front Center Stack Switch 30";
BA_ "SignalType" SG_ 1439 FrtCntrStckSw29 "ENM";
BA_ "SignalLongName" SG_ 1439 FrtCntrStckSw29 "Front Center Stack Switch 29";
BA_ "SignalType" SG_ 1439 FrtCntrStckSw28 "ENM";
BA_ "SignalLongName" SG_ 1439 FrtCntrStckSw28 "Front Center Stack Switch 28";
BA_ "SignalType" SG_ 1439 FrtCntrStckSw27 "ENM";
BA_ "SignalLongName" SG_ 1439 FrtCntrStckSw27 "Front Center Stack Switch 27";
BA_ "SignalType" SG_ 1439 FrtCntrStckSw26 "ENM";
BA_ "SignalLongName" SG_ 1439 FrtCntrStckSw26 "Front Center Stack Switch 26";
BA_ "SignalType" SG_ 1439 FrtCntrStckSw25 "ENM";
BA_ "SignalLongName" SG_ 1439 FrtCntrStckSw25 "Front Center Stack Switch 25";
BA_ "SignalLongName" SG_ 1180 UTCHrs "UTC Date and Time : Hours";
BA_ "SignalType" SG_ 1180 UTCDay_Inv "ENM";
BA_ "SignalLongName" SG_ 1180 UTCDay_Inv "UTC Date and Time : Day Invalid";
BA_ "SignalLongName" SG_ 1180 UTCDay "UTC Date and Time : Day";
BA_ "SignalLongName" SG_ 1180 UTCMin "UTC Date and Time : Minutes";
BA_ "SignalType" SG_ 1180 UTCHrs_Inv "ENM";
BA_ "SignalLongName" SG_ 1180 UTCHrs_Inv "UTC Date and Time : Hours Invalid";
BA_ "SignalType" SG_ 1180 UTCMth_Inv "ENM";
BA_ "SignalLongName" SG_ 1180 UTCMth_Inv "UTC Date and Time : Month Invalid";
BA_ "SignalType" SG_ 1180 UTCMth "ENM";
BA_ "SignalLongName" SG_ 1180 UTCMth "UTC Date and Time : Month";
BA_ "SignalType" SG_ 1180 UTCMin_Inv "ENM";
BA_ "SignalLongName" SG_ 1180 UTCMin_Inv "UTC Date and Time : Minutes Invalid";
BA_ "SignalLongName" SG_ 1180 UTCYr "UTC Date and Time : Year";
BA_ "SignalType" SG_ 1180 UTCSec_Inv "ENM";
BA_ "SignalLongName" SG_ 1180 UTCSec_Inv "UTC Date and Time : Seconds Invalid";
BA_ "SignalLongName" SG_ 1180 UTCSec "UTC Date and Time : Seconds";
BA_ "SignalType" SG_ 1180 UTCYr_Inv "ENM";
BA_ "SignalLongName" SG_ 1180 UTCYr_Inv "UTC Date and Time : Year Invalid";
BA_ "SignalType" SG_ 1180 CellNWDateTimeAvl "ENM";
BA_ "SignalLongName" SG_ 1180 CellNWDateTimeAvl "Cellular Network Date and Time Available";
BA_ "SignalLongName" SG_ 1244 CmpsCrHding "Compass Corrected Heading";
BA_ "SignalType" SG_ 1244 CmpsOctHding "ENM";
BA_ "SignalLongName" SG_ 1244 CmpsOctHding "Compass Octant Heading";
BA_ "SignalType" SG_ 1244 CmpsDecZone "ENM";
BA_ "SignalLongName" SG_ 1244 CmpsDecZone "Compass Declination Zone";
BA_ "SignalType" SG_ 1244 EmrgRespSysServIndOn "ENM";
BA_ "SignalLongName" SG_ 1244 EmrgRespSysServIndOn "Emergency Response System Service Indication On";
BA_ "SignalType" SG_ 1244 CmpsZnNvrSet "ENM";
BA_ "SignalLongName" SG_ 1244 CmpsZnNvrSet "Compass Zone Never Set";
BA_ "SignalType" SG_ 1244 CmpsSatrtd "ENM";
BA_ "SignalLongName" SG_ 1244 CmpsSatrtd "Compass Saturated";
BA_ "SignalType" SG_ 1244 CmpsOctHdingDataSrc "ENM";
BA_ "SignalLongName" SG_ 1244 CmpsOctHdingDataSrc "Compass Octant Heading Data Source";
BA_ "SignalType" SG_ 1244 CmpsModManCalInPrc "ENM";
BA_ "SignalLongName" SG_ 1244 CmpsModManCalInPrc "Compass Module Manual Calibration In Process";
BA_ "SignalType" SG_ 1244 CmpsModFltPrs "ENM";
BA_ "SignalLongName" SG_ 1244 CmpsModFltPrs "Compass Module Fault Present";
BA_ "SignalType" SG_ 1440 FrtCntrStckHptcFdbkStat "ENM";
BA_ "SignalLongName" SG_ 1440 FrtCntrStckHptcFdbkStat "Front Center Stack Haptic Feedback State";
BA_ "SignalType" SG_ 1440 FrtCntrStckTag2Sw "ENM";
BA_ "SignalLongName" SG_ 1440 FrtCntrStckTag2Sw "Front Center Stack Tag 2 Switch";
BA_ "SignalType" SG_ 1440 FrtCntrStckTag1Sw "ENM";
BA_ "SignalLongName" SG_ 1440 FrtCntrStckTag1Sw "Front Center Stack Tag 1 Switch";
BA_ "SignalType" SG_ 1440 FrtCntrStckPrxmtyStat "ENM";
BA_ "SignalLongName" SG_ 1440 FrtCntrStckPrxmtyStat "Front Center Stack Proximity State";
BA_ "SignalType" SG_ 1440 FrtCntrStckPrxmtyGstr "ENM";
BA_ "SignalLongName" SG_ 1440 FrtCntrStckPrxmtyGstr "Front Center Stack Proximity Gesture";
BA_ "SignalType" SG_ 1440 FrtCntrStckVolUpSw "ENM";
BA_ "SignalLongName" SG_ 1440 FrtCntrStckVolUpSw "Front Center Stack Volume Up Switch";
BA_ "SignalType" SG_ 1440 FrtCntrStckVolDnSw "ENM";
BA_ "SignalLongName" SG_ 1440 FrtCntrStckVolDnSw "Front Center Stack Volume Down Switch";
BA_ "SignalType" SG_ 1440 FrtCntrStckToneSw "ENM";
BA_ "SignalLongName" SG_ 1440 FrtCntrStckToneSw "Front Center Stack Tone Switch";
BA_ "SignalType" SG_ 1440 FrtCntrStckTag5Sw "ENM";
BA_ "SignalLongName" SG_ 1440 FrtCntrStckTag5Sw "Front Center Stack Tag 5 Switch";
BA_ "SignalType" SG_ 1440 FrtCntrStckTag4Sw "ENM";
BA_ "SignalLongName" SG_ 1440 FrtCntrStckTag4Sw "Front Center Stack Tag 4 Switch";
BA_ "SignalType" SG_ 1440 FrtCntrStckTag3Sw "ENM";
BA_ "SignalLongName" SG_ 1440 FrtCntrStckTag3Sw "Front Center Stack Tag 3 Switch";
BA_ "SignalType" SG_ 1503 SBZAlrtCstAvlFlg7 "ENM";
BA_ "SignalLongName" SG_ 1503 SBZAlrtCstAvlFlg7 "Side Blind Zone Alert Customization Availability Flag 7";
BA_ "SignalType" SG_ 1503 SBZAlrtCstAvlFlg6 "ENM";
BA_ "SignalLongName" SG_ 1503 SBZAlrtCstAvlFlg6 "Side Blind Zone Alert Customization Availability Flag 6";
BA_ "SignalType" SG_ 1503 SBZAlrtCstAvlFlg5 "ENM";
BA_ "SignalLongName" SG_ 1503 SBZAlrtCstAvlFlg5 "Side Blind Zone Alert Customization Availability Flag 5";
BA_ "SignalType" SG_ 1503 SBZAlrtCstAvlFlg4 "ENM";
BA_ "SignalLongName" SG_ 1503 SBZAlrtCstAvlFlg4 "Side Blind Zone Alert Customization Availability Flag 4";
BA_ "SignalType" SG_ 1503 SBZAlrtCstAvlFlg3 "ENM";
BA_ "SignalLongName" SG_ 1503 SBZAlrtCstAvlFlg3 "Side Blind Zone Alert Customization Availability Flag 3";
BA_ "SignalType" SG_ 1503 SBZAlrtCstAvlFlg2 "ENM";
BA_ "SignalLongName" SG_ 1503 SBZAlrtCstAvlFlg2 "Side Blind Zone Alert Customization Availability Flag 2";
BA_ "SignalType" SG_ 1503 SBZAlrtCstAvlFlg1 "ENM";
BA_ "SignalLongName" SG_ 1503 SBZAlrtCstAvlFlg1 "Side Blind Zone Alert Customization Availability Flag 1";
BA_ "SignalType" SG_ 1503 LnChgAlrtLmtdTrlrIndOn "ENM";
BA_ "SignalLongName" SG_ 1503 LnChgAlrtLmtdTrlrIndOn "Lane Change Alert Limited by Trailer Indication On";
BA_ "SignalType" SG_ 1503 ServSdDtcSysIndOn "ENM";
BA_ "SignalLongName" SG_ 1503 ServSdDtcSysIndOn "Service Side Detection System Indication On";
BA_ "SignalType" SG_ 1503 SdDtcTempUnvIndOn "ENM";
BA_ "SignalLongName" SG_ 1503 SdDtcTempUnvIndOn "Side Detection Temporarily Unavailable Indication On";
BA_ "SignalType" SG_ 1503 SBZAlrtOffIndOn "ENM";
BA_ "SignalLongName" SG_ 1503 SBZAlrtOffIndOn "Side Blind Zone Alert Off Indication On";
BA_ "SignalType" SG_ 1503 SBZAlrtCstStAvl "ENM";
BA_ "SignalLongName" SG_ 1503 SBZAlrtCstStAvl "Side Blind Zone Alert Customization Setting Available";
BA_ "SignalType" SG_ 1509 DrvrAlrtTypCstStAvl "ENM";
BA_ "SignalLongName" SG_ 1509 DrvrAlrtTypCstStAvl "Driver Alert Type Customization Setting Available";
BA_ "SignalType" SG_ 1509 DrvrAlrtTypCstAvlFlg7 "ENM";
BA_ "SignalLongName" SG_ 1509 DrvrAlrtTypCstAvlFlg7 "Driver Alert Type Customization Availability Flag 7";
BA_ "SignalType" SG_ 1509 DrvrAlrtTypCstAvlFlg6 "ENM";
BA_ "SignalLongName" SG_ 1509 DrvrAlrtTypCstAvlFlg6 "Driver Alert Type Customization Availability Flag 6";
BA_ "SignalType" SG_ 1509 DrvrAlrtTypCstAvlFlg5 "ENM";
BA_ "SignalLongName" SG_ 1509 DrvrAlrtTypCstAvlFlg5 "Driver Alert Type CustomizationAvailability Flag 5";
BA_ "SignalType" SG_ 1509 DrvrAlrtTypCstAvlFlg4 "ENM";
BA_ "SignalLongName" SG_ 1509 DrvrAlrtTypCstAvlFlg4 "Driver Alert Type Customization Availability Flag 4";
BA_ "SignalType" SG_ 1509 DrvrAlrtTypCstAvlFlg3 "ENM";
BA_ "SignalLongName" SG_ 1509 DrvrAlrtTypCstAvlFlg3 "Driver Alert Type Customization Availability Flag 3";
BA_ "SignalType" SG_ 1509 DrvrAlrtTypCstAvlFlg2 "ENM";
BA_ "SignalLongName" SG_ 1509 DrvrAlrtTypCstAvlFlg2 "Driver Alert Type Customization Availability Flag 2";
BA_ "SignalType" SG_ 1509 DrvrAlrtTypCstAvlFlg1 "ENM";
BA_ "SignalLongName" SG_ 1509 DrvrAlrtTypCstAvlFlg1 "Driver Alert Type Customization Availability Flag 1";
BA_ "SignalType" SG_ 1509 HptcStFldIndOn "ENM";
BA_ "SignalLongName" SG_ 1509 HptcStFldIndOn "Haptic Seat Failed Indication On";
BA_ "SignalLongName" SG_ 702 DrvrAppStrgTrq "Driver Applied Steering Torque";
BA_ "SignalType" SG_ 702 StrgWhlTrqIntegSts "ENM";
BA_ "SignalLongName" SG_ 702 StrgWhlTrqIntegSts "Steering Wheel Torque Integrity Status";
BA_ "SignalType" SG_ 702 StrgWhlHndsOffDtnStat "ENM";
BA_ "SignalLongName" SG_ 702 StrgWhlHndsOffDtnStat "Steering Wheel Hands Off Detection State";
VAL_ 1199 DTCI_SRR_RR_CnfrmdDTC 0 "FALSE" 1 "TRUE" ;
VAL_ 1199 DTCI_SRR_RR_DTCFaultType 0 "Not Supported" 1 "Type A" 2 "Type B" 3 "Type C" ;
VAL_ 1199 DTCI_SRR_RR_TstNCmpltdOpCyc 0 "FALSE" 1 "TRUE" ;
VAL_ 1199 DTCI_SRR_RR_TstNCmpltdLstClr 0 "FALSE" 1 "TRUE" ;
VAL_ 1199 DTCI_SRR_RR_TstFldOpCyc 0 "FALSE" 1 "TRUE" ;
VAL_ 1199 DTCI_SRR_RR_TstFldLstClr 0 "FALSE" 1 "TRUE" ;
VAL_ 1199 DTCI_SRR_RR_TstFld 0 "FALSE" 1 "TRUE" ;
VAL_ 1199 DTCI_SRR_RR_PndngDTC 0 "FALSE" 1 "TRUE" ;
VAL_ 1199 DTCI_SRR_RR_DTCTriggered 0 "FALSE" 1 "TRUE" ;
VAL_ 1199 DTCI_SRR_RR_WrnIndTrggrd 0 "FALSE" 1 "TRUE" ;
VAL_ 1199 DTCI_SRR_RR_WrnIndRqd 0 "FALSE" 1 "TRUE" ;
VAL_ 1867 DTCI_SRR_SLR_CnfrmdDTC 0 "FALSE" 1 "TRUE" ;
VAL_ 1867 DTCI_SRR_SLR_DTCFaultType 0 "Not Supported" 1 "Type A" 2 "Type B" 3 "Type C" ;
VAL_ 1867 DTCI_SRR_SLR_TstNCmpltdOpCyc 0 "FALSE" 1 "TRUE" ;
VAL_ 1867 DTCI_SRR_SLR_TstNCmpltdLstClr 0 "FALSE" 1 "TRUE" ;
VAL_ 1867 DTCI_SRR_SLR_TstFldOpCyc 0 "FALSE" 1 "TRUE" ;
VAL_ 1867 DTCI_SRR_SLR_TstFldLstClr 0 "FALSE" 1 "TRUE" ;
VAL_ 1867 DTCI_SRR_SLR_TstFld 0 "FALSE" 1 "TRUE" ;
VAL_ 1867 DTCI_SRR_SLR_PndngDTC 0 "FALSE" 1 "TRUE" ;
VAL_ 1867 DTCI_SRR_SLR_DTCTriggered 0 "FALSE" 1 "TRUE" ;
VAL_ 1867 DTCI_SRR_SLR_WrnIndTrggrd 0 "FALSE" 1 "TRUE" ;
VAL_ 1867 DTCI_SRR_SLR_WrnIndRqd 0 "FALSE" 1 "TRUE" ;
VAL_ 1198 DTCI_SRR_SRR_CnfrmdDTC 0 "FALSE" 1 "TRUE" ;
VAL_ 1198 DTCI_SRR_SRR_DTCFaultType 0 "Not Supported" 1 "Type A" 2 "Type B" 3 "Type C" ;
VAL_ 1198 DTCI_SRR_SRR_TstNCmpltdOpCyc 0 "FALSE" 1 "TRUE" ;
VAL_ 1198 DTCI_SRR_SRR_TstNCmpltdLstClr 0 "FALSE" 1 "TRUE" ;
VAL_ 1198 DTCI_SRR_SRR_TstFldOpCyc 0 "FALSE" 1 "TRUE" ;
VAL_ 1198 DTCI_SRR_SRR_TstFldLstClr 0 "FALSE" 1 "TRUE" ;
VAL_ 1198 DTCI_SRR_SRR_TstFld 0 "FALSE" 1 "TRUE" ;
VAL_ 1198 DTCI_SRR_SRR_PndngDTC 0 "FALSE" 1 "TRUE" ;
VAL_ 1198 DTCI_SRR_SRR_DTCTriggered 0 "FALSE" 1 "TRUE" ;
VAL_ 1198 DTCI_SRR_SRR_WrnIndTrggrd 0 "FALSE" 1 "TRUE" ;
VAL_ 1198 DTCI_SRR_SRR_WrnIndRqd 0 "FALSE" 1 "TRUE" ;
VAL_ 1197 DTCI_TCCM_CnfrmdDTC 0 "FALSE" 1 "TRUE" ;
VAL_ 1197 DTCI_TCCM_DTCFaultType 0 "Not Supported" 1 "Type A" 2 "Type B" 3 "Type C" ;
VAL_ 1197 DTCI_TCCM_TstNCmpltdOpCyc 0 "FALSE" 1 "TRUE" ;
VAL_ 1197 DTCI_TCCM_TstNCmpltdLstClr 0 "FALSE" 1 "TRUE" ;
VAL_ 1197 DTCI_TCCM_TstFldOpCyc 0 "FALSE" 1 "TRUE" ;
VAL_ 1197 DTCI_TCCM_TstFldLstClr 0 "FALSE" 1 "TRUE" ;
VAL_ 1197 DTCI_TCCM_TstFld 0 "FALSE" 1 "TRUE" ;
VAL_ 1197 DTCI_TCCM_PndngDTC 0 "FALSE" 1 "TRUE" ;
VAL_ 1197 DTCI_TCCM_DTCTriggered 0 "FALSE" 1 "TRUE" ;
VAL_ 1197 DTCI_TCCM_WrnIndTrggrd 0 "FALSE" 1 "TRUE" ;
VAL_ 1197 DTCI_TCCM_WrnIndRqd 0 "FALSE" 1 "TRUE" ;
VAL_ 1869 DTCI_TCM_CnfrmdDTC 0 "FALSE" 1 "TRUE" ;
VAL_ 1869 DTCI_TCM_DTCFaultType 0 "Not Supported" 1 "Type A" 2 "Type B" 3 "Type C" ;
VAL_ 1869 DTCI_TCM_TstNCmpltdOpCyc 0 "FALSE" 1 "TRUE" ;
VAL_ 1869 DTCI_TCM_TstNCmpltdLstClr 0 "FALSE" 1 "TRUE" ;
VAL_ 1869 DTCI_TCM_TstFldOpCyc 0 "FALSE" 1 "TRUE" ;
VAL_ 1869 DTCI_TCM_TstFldLstClr 0 "FALSE" 1 "TRUE" ;
VAL_ 1869 DTCI_TCM_TstFld 0 "FALSE" 1 "TRUE" ;
VAL_ 1869 DTCI_TCM_PndngDTC 0 "FALSE" 1 "TRUE" ;
VAL_ 1869 DTCI_TCM_DTCTriggered 0 "FALSE" 1 "TRUE" ;
VAL_ 1869 DTCI_TCM_WrnIndTrggrd 0 "FALSE" 1 "TRUE" ;
VAL_ 1869 DTCI_TCM_WrnIndRqd 0 "FALSE" 1 "TRUE" ;
VAL_ 1196 DTCI_TCP_CnfrmdDTC 0 "FALSE" 1 "TRUE" ;
VAL_ 1196 DTCI_TCP_DTCFaultType 0 "Not Supported" 1 "Type A" 2 "Type B" 3 "Type C" ;
VAL_ 1196 DTCI_TCP_TstNCmpltdOpCyc 0 "FALSE" 1 "TRUE" ;
VAL_ 1196 DTCI_TCP_TstNCmpltdLstClr 0 "FALSE" 1 "TRUE" ;
VAL_ 1196 DTCI_TCP_TstFldOpCyc 0 "FALSE" 1 "TRUE" ;
VAL_ 1196 DTCI_TCP_TstFldLstClr 0 "FALSE" 1 "TRUE" ;
VAL_ 1196 DTCI_TCP_TstFld 0 "FALSE" 1 "TRUE" ;
VAL_ 1196 DTCI_TCP_PndngDTC 0 "FALSE" 1 "TRUE" ;
VAL_ 1196 DTCI_TCP_DTCTriggered 0 "FALSE" 1 "TRUE" ;
VAL_ 1196 DTCI_TCP_WrnIndTrggrd 0 "FALSE" 1 "TRUE" ;
VAL_ 1196 DTCI_TCP_WrnIndRqd 0 "FALSE" 1 "TRUE" ;
VAL_ 1870 DTCI_TIM_CnfrmdDTC 0 "FALSE" 1 "TRUE" ;
VAL_ 1870 DTCI_TIM_DTCFaultType 0 "Not Supported" 1 "Type A" 2 "Type B" 3 "Type C" ;
VAL_ 1870 DTCI_TIM_TstNCmpltdOpCyc 0 "FALSE" 1 "TRUE" ;
VAL_ 1870 DTCI_TIM_TstNCmpltdLstClr 0 "FALSE" 1 "TRUE" ;
VAL_ 1870 DTCI_TIM_TstFldOpCyc 0 "FALSE" 1 "TRUE" ;
VAL_ 1870 DTCI_TIM_TstFldLstClr 0 "FALSE" 1 "TRUE" ;
VAL_ 1870 DTCI_TIM_TstFld 0 "FALSE" 1 "TRUE" ;
VAL_ 1870 DTCI_TIM_PndngDTC 0 "FALSE" 1 "TRUE" ;
VAL_ 1870 DTCI_TIM_DTCTriggered 0 "FALSE" 1 "TRUE" ;
VAL_ 1870 DTCI_TIM_WrnIndTrggrd 0 "FALSE" 1 "TRUE" ;
VAL_ 1870 DTCI_TIM_WrnIndRqd 0 "FALSE" 1 "TRUE" ;
VAL_ 1902 DTCI_UPM_CnfrmdDTC 0 "FALSE" 1 "TRUE" ;
VAL_ 1902 DTCI_UPM_DTCFaultType 0 "Not Supported" 1 "Type A" 2 "Type B" 3 "Type C" ;
VAL_ 1902 DTCI_UPM_TstNCmpltdOpCyc 0 "FALSE" 1 "TRUE" ;
VAL_ 1902 DTCI_UPM_TstNCmpltdLstClr 0 "FALSE" 1 "TRUE" ;
VAL_ 1902 DTCI_UPM_TstFldOpCyc 0 "FALSE" 1 "TRUE" ;
VAL_ 1902 DTCI_UPM_TstFldLstClr 0 "FALSE" 1 "TRUE" ;
VAL_ 1902 DTCI_UPM_TstFld 0 "FALSE" 1 "TRUE" ;
VAL_ 1902 DTCI_UPM_PndngDTC 0 "FALSE" 1 "TRUE" ;
VAL_ 1902 DTCI_UPM_DTCTriggered 0 "FALSE" 1 "TRUE" ;
VAL_ 1902 DTCI_UPM_WrnIndTrggrd 0 "FALSE" 1 "TRUE" ;
VAL_ 1902 DTCI_UPM_WrnIndRqd 0 "FALSE" 1 "TRUE" ;
VAL_ 1904 DTCI_UVM_CnfrmdDTC 0 "FALSE" 1 "TRUE" ;
VAL_ 1904 DTCI_UVM_DTCFaultType 0 "Not Supported" 1 "Type A" 2 "Type B" 3 "Type C" ;
VAL_ 1904 DTCI_UVM_TstNCmpltdOpCyc 0 "FALSE" 1 "TRUE" ;
VAL_ 1904 DTCI_UVM_TstNCmpltdLstClr 0 "FALSE" 1 "TRUE" ;
VAL_ 1904 DTCI_UVM_TstFldOpCyc 0 "FALSE" 1 "TRUE" ;
VAL_ 1904 DTCI_UVM_TstFldLstClr 0 "FALSE" 1 "TRUE" ;
VAL_ 1904 DTCI_UVM_TstFld 0 "FALSE" 1 "TRUE" ;
VAL_ 1904 DTCI_UVM_PndngDTC 0 "FALSE" 1 "TRUE" ;
VAL_ 1904 DTCI_UVM_DTCTriggered 0 "FALSE" 1 "TRUE" ;
VAL_ 1904 DTCI_UVM_WrnIndTrggrd 0 "FALSE" 1 "TRUE" ;
VAL_ 1904 DTCI_UVM_WrnIndRqd 0 "FALSE" 1 "TRUE" ;
VAL_ 1195 DTCI_VCU_CnfrmdDTC 0 "FALSE" 1 "TRUE" ;
VAL_ 1195 DTCI_VCU_DTCFaultType 0 "Not Supported" 1 "Type A" 2 "Type B" 3 "Type C" ;
VAL_ 1195 DTCI_VCU_TstNCmpltdOpCyc 0 "FALSE" 1 "TRUE" ;
VAL_ 1195 DTCI_VCU_TstNCmpltdLstClr 0 "FALSE" 1 "TRUE" ;
VAL_ 1195 DTCI_VCU_TstFldOpCyc 0 "FALSE" 1 "TRUE" ;
VAL_ 1195 DTCI_VCU_TstFldLstClr 0 "FALSE" 1 "TRUE" ;
VAL_ 1195 DTCI_VCU_TstFld 0 "FALSE" 1 "TRUE" ;
VAL_ 1195 DTCI_VCU_PndngDTC 0 "FALSE" 1 "TRUE" ;
VAL_ 1195 DTCI_VCU_DTCTriggered 0 "FALSE" 1 "TRUE" ;
VAL_ 1195 DTCI_VCU_WrnIndTrggrd 0 "FALSE" 1 "TRUE" ;
VAL_ 1195 DTCI_VCU_WrnIndRqd 0 "FALSE" 1 "TRUE" ;
VAL_ 1175 DTCI_VDM_CnfrmdDTC 0 "FALSE" 1 "TRUE" ;
VAL_ 1175 DTCI_VDM_DTCFaultType 0 "Not Supported" 1 "Type A" 2 "Type B" 3 "Type C" ;
VAL_ 1175 DTCI_VDM_TstNCmpltdOpCyc 0 "FALSE" 1 "TRUE" ;
VAL_ 1175 DTCI_VDM_TstNCmpltdLstClr 0 "FALSE" 1 "TRUE" ;
VAL_ 1175 DTCI_VDM_TstFldOpCyc 0 "FALSE" 1 "TRUE" ;
VAL_ 1175 DTCI_VDM_TstFldLstClr 0 "FALSE" 1 "TRUE" ;
VAL_ 1175 DTCI_VDM_TstFld 0 "FALSE" 1 "TRUE" ;
VAL_ 1175 DTCI_VDM_PndngDTC 0 "FALSE" 1 "TRUE" ;
VAL_ 1175 DTCI_VDM_DTCTriggered 0 "FALSE" 1 "TRUE" ;
VAL_ 1175 DTCI_VDM_WrnIndTrggrd 0 "FALSE" 1 "TRUE" ;
VAL_ 1175 DTCI_VDM_WrnIndRqd 0 "FALSE" 1 "TRUE" ;
VAL_ 1891 DTCI_VECM_CnfrmdDTC 0 "FALSE" 1 "TRUE" ;
VAL_ 1891 DTCI_VECM_DTCFaultType 0 "Not Supported" 1 "Type A" 2 "Type B" 3 "Type C" ;
VAL_ 1891 DTCI_VECM_TstNCmpltdOpCyc 0 "FALSE" 1 "TRUE" ;
VAL_ 1891 DTCI_VECM_TstNCmpltdLstClr 0 "FALSE" 1 "TRUE" ;
VAL_ 1891 DTCI_VECM_TstFldOpCyc 0 "FALSE" 1 "TRUE" ;
VAL_ 1891 DTCI_VECM_TstFldLstClr 0 "FALSE" 1 "TRUE" ;
VAL_ 1891 DTCI_VECM_TstFld 0 "FALSE" 1 "TRUE" ;
VAL_ 1891 DTCI_VECM_PndngDTC 0 "FALSE" 1 "TRUE" ;
VAL_ 1891 DTCI_VECM_DTCTriggered 0 "FALSE" 1 "TRUE" ;
VAL_ 1891 DTCI_VECM_WrnIndTrggrd 0 "FALSE" 1 "TRUE" ;
VAL_ 1891 DTCI_VECM_WrnIndRqd 0 "FALSE" 1 "TRUE" ;
VAL_ 1871 DTCI_VICM_CnfrmdDTC 0 "FALSE" 1 "TRUE" ;
VAL_ 1871 DTCI_VICM_DTCFaultType 0 "Not Supported" 1 "Type A" 2 "Type B" 3 "Type C" ;
VAL_ 1871 DTCI_VICM_TstNCmpltdOpCyc 0 "FALSE" 1 "TRUE" ;
VAL_ 1871 DTCI_VICM_TstNCmpltdLstClr 0 "FALSE" 1 "TRUE" ;
VAL_ 1871 DTCI_VICM_TstFldOpCyc 0 "FALSE" 1 "TRUE" ;
VAL_ 1871 DTCI_VICM_TstFldLstClr 0 "FALSE" 1 "TRUE" ;
VAL_ 1871 DTCI_VICM_TstFld 0 "FALSE" 1 "TRUE" ;
VAL_ 1871 DTCI_VICM_PndngDTC 0 "FALSE" 1 "TRUE" ;
VAL_ 1871 DTCI_VICM_DTCTriggered 0 "FALSE" 1 "TRUE" ;
VAL_ 1871 DTCI_VICM_WrnIndTrggrd 0 "FALSE" 1 "TRUE" ;
VAL_ 1871 DTCI_VICM_WrnIndRqd 0 "FALSE" 1 "TRUE" ;
VAL_ 1194 DTCI_VKM_CnfrmdDTC 0 "FALSE" 1 "TRUE" ;
VAL_ 1194 DTCI_VKM_DTCFaultType 0 "Not Supported" 1 "Type A" 2 "Type B" 3 "Type C" ;
VAL_ 1194 DTCI_VKM_TstNCmpltdOpCyc 0 "FALSE" 1 "TRUE" ;
VAL_ 1194 DTCI_VKM_TstNCmpltdLstClr 0 "FALSE" 1 "TRUE" ;
VAL_ 1194 DTCI_VKM_TstFldOpCyc 0 "FALSE" 1 "TRUE" ;
VAL_ 1194 DTCI_VKM_TstFldLstClr 0 "FALSE" 1 "TRUE" ;
VAL_ 1194 DTCI_VKM_TstFld 0 "FALSE" 1 "TRUE" ;
VAL_ 1194 DTCI_VKM_PndngDTC 0 "FALSE" 1 "TRUE" ;
VAL_ 1194 DTCI_VKM_DTCTriggered 0 "FALSE" 1 "TRUE" ;
VAL_ 1194 DTCI_VKM_WrnIndTrggrd 0 "FALSE" 1 "TRUE" ;
VAL_ 1194 DTCI_VKM_WrnIndRqd 0 "FALSE" 1 "TRUE" ;
VAL_ 1872 DTCI_VLM_CnfrmdDTC 0 "FALSE" 1 "TRUE" ;
VAL_ 1872 DTCI_VLM_DTCFaultType 0 "Not Supported" 1 "Type A" 2 "Type B" 3 "Type C" ;
VAL_ 1872 DTCI_VLM_TstNCmpltdOpCyc 0 "FALSE" 1 "TRUE" ;
VAL_ 1872 DTCI_VLM_TstNCmpltdLstClr 0 "FALSE" 1 "TRUE" ;
VAL_ 1872 DTCI_VLM_TstFldOpCyc 0 "FALSE" 1 "TRUE" ;
VAL_ 1872 DTCI_VLM_TstFldLstClr 0 "FALSE" 1 "TRUE" ;
VAL_ 1872 DTCI_VLM_TstFld 0 "FALSE" 1 "TRUE" ;
VAL_ 1872 DTCI_VLM_PndngDTC 0 "FALSE" 1 "TRUE" ;
VAL_ 1872 DTCI_VLM_DTCTriggered 0 "FALSE" 1 "TRUE" ;
VAL_ 1872 DTCI_VLM_WrnIndTrggrd 0 "FALSE" 1 "TRUE" ;
VAL_ 1872 DTCI_VLM_WrnIndRqd 0 "FALSE" 1 "TRUE" ;
VAL_ 1193 DTCI_VPM_CnfrmdDTC 0 "FALSE" 1 "TRUE" ;
VAL_ 1193 DTCI_VPM_DTCFaultType 0 "Not Supported" 1 "Type A" 2 "Type B" 3 "Type C" ;
VAL_ 1193 DTCI_VPM_TstNCmpltdOpCyc 0 "FALSE" 1 "TRUE" ;
VAL_ 1193 DTCI_VPM_TstNCmpltdLstClr 0 "FALSE" 1 "TRUE" ;
VAL_ 1193 DTCI_VPM_TstFldOpCyc 0 "FALSE" 1 "TRUE" ;
VAL_ 1193 DTCI_VPM_TstFldLstClr 0 "FALSE" 1 "TRUE" ;
VAL_ 1193 DTCI_VPM_TstFld 0 "FALSE" 1 "TRUE" ;
VAL_ 1193 DTCI_VPM_PndngDTC 0 "FALSE" 1 "TRUE" ;
VAL_ 1193 DTCI_VPM_DTCTriggered 0 "FALSE" 1 "TRUE" ;
VAL_ 1193 DTCI_VPM_WrnIndTrggrd 0 "FALSE" 1 "TRUE" ;
VAL_ 1193 DTCI_VPM_WrnIndRqd 0 "FALSE" 1 "TRUE" ;
VAL_ 1346 DTCI_WCM2_CnfrmdDTC 0 "FALSE" 1 "TRUE" ;
VAL_ 1346 DTCI_WCM2_DTCFaultType 0 "Not Supported" 1 "Type A" 2 "Type B" 3 "Type C" ;
VAL_ 1346 DTCI_WCM2_TstNCmpltdOpCyc 0 "FALSE" 1 "TRUE" ;
VAL_ 1346 DTCI_WCM2_TstNCmpltdLstClr 0 "FALSE" 1 "TRUE" ;
VAL_ 1346 DTCI_WCM2_TstFldOpCyc 0 "FALSE" 1 "TRUE" ;
VAL_ 1346 DTCI_WCM2_TstFldLstClr 0 "FALSE" 1 "TRUE" ;
VAL_ 1346 DTCI_WCM2_TstFld 0 "FALSE" 1 "TRUE" ;
VAL_ 1346 DTCI_WCM2_PndngDTC 0 "FALSE" 1 "TRUE" ;
VAL_ 1346 DTCI_WCM2_DTCTriggered 0 "FALSE" 1 "TRUE" ;
VAL_ 1346 DTCI_WCM2_WrnIndTrggrd 0 "FALSE" 1 "TRUE" ;
VAL_ 1346 DTCI_WCM2_WrnIndRqd 0 "FALSE" 1 "TRUE" ;
VAL_ 1285 DTCI_WCM3_CnfrmdDTC 0 "FALSE" 1 "TRUE" ;
VAL_ 1285 DTCI_WCM3_DTCFaultType 0 "Not Supported" 1 "Type A" 2 "Type B" 3 "Type C" ;
VAL_ 1285 DTCI_WCM3_TstNCmpltdOpCyc 0 "FALSE" 1 "TRUE" ;
VAL_ 1285 DTCI_WCM3_TstNCmpltdLstClr 0 "FALSE" 1 "TRUE" ;
VAL_ 1285 DTCI_WCM3_TstFldOpCyc 0 "FALSE" 1 "TRUE" ;
VAL_ 1285 DTCI_WCM3_TstFldLstClr 0 "FALSE" 1 "TRUE" ;
VAL_ 1285 DTCI_WCM3_TstFld 0 "FALSE" 1 "TRUE" ;
VAL_ 1285 DTCI_WCM3_PndngDTC 0 "FALSE" 1 "TRUE" ;
VAL_ 1285 DTCI_WCM3_DTCTriggered 0 "FALSE" 1 "TRUE" ;
VAL_ 1285 DTCI_WCM3_WrnIndTrggrd 0 "FALSE" 1 "TRUE" ;
VAL_ 1285 DTCI_WCM3_WrnIndRqd 0 "FALSE" 1 "TRUE" ;
VAL_ 1216 DTCI_WCM4_CnfrmdDTC 0 "FALSE" 1 "TRUE" ;
VAL_ 1216 DTCI_WCM4_DTCFaultType 0 "Not Supported" 1 "Type A" 2 "Type B" 3 "Type C" ;
VAL_ 1216 DTCI_WCM4_TstNCmpltdOpCyc 0 "FALSE" 1 "TRUE" ;
VAL_ 1216 DTCI_WCM4_TstNCmpltdLstClr 0 "FALSE" 1 "TRUE" ;
VAL_ 1216 DTCI_WCM4_TstFldOpCyc 0 "FALSE" 1 "TRUE" ;
VAL_ 1216 DTCI_WCM4_TstFldLstClr 0 "FALSE" 1 "TRUE" ;
VAL_ 1216 DTCI_WCM4_TstFld 0 "FALSE" 1 "TRUE" ;
VAL_ 1216 DTCI_WCM4_PndngDTC 0 "FALSE" 1 "TRUE" ;
VAL_ 1216 DTCI_WCM4_DTCTriggered 0 "FALSE" 1 "TRUE" ;
VAL_ 1216 DTCI_WCM4_WrnIndTrggrd 0 "FALSE" 1 "TRUE" ;
VAL_ 1216 DTCI_WCM4_WrnIndRqd 0 "FALSE" 1 "TRUE" ;
VAL_ 1873 DTCI_WCM_CnfrmdDTC 0 "FALSE" 1 "TRUE" ;
VAL_ 1873 DTCI_WCM_DTCFaultType 0 "Not Supported" 1 "Type A" 2 "Type B" 3 "Type C" ;
VAL_ 1873 DTCI_WCM_TstNCmpltdOpCyc 0 "FALSE" 1 "TRUE" ;
VAL_ 1873 DTCI_WCM_TstNCmpltdLstClr 0 "FALSE" 1 "TRUE" ;
VAL_ 1873 DTCI_WCM_TstFldOpCyc 0 "FALSE" 1 "TRUE" ;
VAL_ 1873 DTCI_WCM_TstFldLstClr 0 "FALSE" 1 "TRUE" ;
VAL_ 1873 DTCI_WCM_TstFld 0 "FALSE" 1 "TRUE" ;
VAL_ 1873 DTCI_WCM_PndngDTC 0 "FALSE" 1 "TRUE" ;
VAL_ 1873 DTCI_WCM_DTCTriggered 0 "FALSE" 1 "TRUE" ;
VAL_ 1873 DTCI_WCM_WrnIndTrggrd 0 "FALSE" 1 "TRUE" ;
VAL_ 1873 DTCI_WCM_WrnIndRqd 0 "FALSE" 1 "TRUE" ;
VAL_ 872 DDIP_SecAxl4WDAWDTmpInhbIOAuth 0 "FALSE" 1 "TRUE" ;
VAL_ 872 DDIP_SecAxl4WDAWDNonEmMlfIOAuth 0 "FALSE" 1 "TRUE" ;
VAL_ 872 DDIP_4AndAllWhlDrvIndReqAuth 0 "No Indication" 1 "Two Wheel Drive High Pending" 2 "Two Wheel Drive High Active" 3 "Four Wheel Drive High Auto Pending" 4 "Four Wheel Drive High Auto Active" 5 "Four Wheel Drive High Lock Pending" 6 "Four Wheel Drive High Lock Active" 7 "Four Wheel Drive Low Lock Pending" 8 "Four Wheel Drive Low Lock Active" 9 "Transfer Case Neutral Pending" 10 "Transfer Case Neutral Active" 11 "Position Undetermined Active" 12 "AWD Connected Mode Pending" 13 "AWD Connected Mode Active" 14 "Front Wheel Drive Mode Pending" 15 "Front Wheel Drive Mode Active" ;
VAL_ 85 WhlAngVelLFrtAuth_Inv 0 "FALSE" 1 "TRUE" ;
VAL_ 85 WhlAngVelLRrAuth_Inv 0 "FALSE" 1 "TRUE" ;
VAL_ 85 WhlAngVelRFrtAuth_Inv 0 "FALSE" 1 "TRUE" ;
VAL_ 85 WhlAngVelRRrAuth_Inv 0 "FALSE" 1 "TRUE" ;
VAL_ 69 CBIP_BrkPedPstnEmsRltdAuth_Inv 0 "FALSE" 1 "TRUE" ;
VAL_ 69 CBIP_ACCBrkgStsAuth 0 "Not Active" 1 "Active" 2 "Failed" ;
VAL_ 69 BSIRP_HillDscntCtlStsAuth 0 "Not Enabled" 1 "Enabled" 2 "Active" ;
VAL_ 730 LDGI1_LgslDiagStdCondsMet 0 "FALSE" 1 "TRUE" ;
VAL_ 63 FWDECP_LFAuth_Inv 0 "FALSE" 1 "TRUE" ;
VAL_ 63 FWDECP_RFAuth_Inv 0 "FALSE" 1 "TRUE" ;
VAL_ 63 RWDECP_LRAuth_Inv 0 "FALSE" 1 "TRUE" ;
VAL_ 63 RWDECP_RRAuth_Inv 0 "FALSE" 1 "TRUE" ;
VAL_ 63 RWDECP_RstOccAuth 0 "FALSE" 1 "TRUE" ;
VAL_ 63 FWDECP_RstOccAuth 0 "FALSE" 1 "TRUE" ;
VAL_ 225 PrplSysMtrBSpdAuth_Public_Inv 0 "FALSE" 1 "TRUE" ;
VAL_ 184 PrplSysMtrCSpdAuth_Public_Inv 0 "FALSE" 1 "TRUE" ;
VAL_ 871 ESRSDP_ElecShftRngSecDispAuth 0 "No Display" 1 "Park Nominal" 2 "Reverse Nominal" 3 "Neutral Nominal" 4 "Drive Nominal" 5 "Low Nominal" 6 "Manual Nominal" 7 "Park Requested And In Progress" 8 "Reverse Requested And In Progress" 9 "Neutral Requested And In Progress" 10 "Drive Requested And In Progress" 11 "Manual Requested And In Progress" 12 "Park Requested And Denied" ;
VAL_ 877 ESCLP_StrgColLckdIndOnAuth 0 "FALSE" 1 "TRUE" ;
VAL_ 877 ESCLP_ServColLckIndOnAuth 0 "FALSE" 1 "TRUE" ;
VAL_ 877 ESCLP_ElecStrgColLckStsAuth 0 "Locked" 1 "Inbetween" 2 "Unlocked" 3 "Unknown" ;
VAL_ 869 ESVTSP_EnhdSrvsVhTpSpLimReqAuth 0 "No Action" 1 "Active" 2 "Inactive" ;
VAL_ 1067 FOMI_ACP2_MCU_DTCTriggered 0 "FALSE" 1 "TRUE" ;
VAL_ 1066 FOMI_ACP3_MCU_DTCTriggered 0 "FALSE" 1 "TRUE" ;
VAL_ 2001 FOMI_ACP4_MCU_DTCTriggered 0 "FALSE" 1 "TRUE" ;
VAL_ 2008 FOMI_BCM_DTCTriggered 0 "FALSE" 1 "TRUE" ;
VAL_ 1065 FOMI_BSM_DTCTriggered 0 "FALSE" 1 "TRUE" ;
VAL_ 2002 FOMI_EBCM_DTCTriggered 0 "FALSE" 1 "TRUE" ;
VAL_ 2007 FOMI_ECM_DTCTriggered 0 "FALSE" 1 "TRUE" ;
VAL_ 1064 FOMI_ECP_E_DTCTriggered 0 "FALSE" 1 "TRUE" ;
VAL_ 2003 FOMI_ECP_H1_DTCTriggered 0 "FALSE" 1 "TRUE" ;
VAL_ 1063 FOMI_ECP_H2_DTCTriggered 0 "FALSE" 1 "TRUE" ;
VAL_ 1062 FOMI_ECP_H3_DTCTriggered 0 "FALSE" 1 "TRUE" ;
VAL_ 1072 FOMI_ECP_S2_DTCTriggered 0 "FALSE" 1 "TRUE" ;
VAL_ 1995 FOMI_ECP_S_DTCTriggered 0 "FALSE" 1 "TRUE" ;
VAL_ 1071 FOMI_ECP_X1_DTCTriggered 0 "FALSE" 1 "TRUE" ;
VAL_ 1996 FOMI_ELM_DTCTriggered 0 "FALSE" 1 "TRUE" ;
VAL_ 1997 FOMI_EOCM_HCP1_DTCTriggered 0 "FALSE" 1 "TRUE" ;
VAL_ 1070 FOMI_EOCM_DTCTriggered 0 "FALSE" 1 "TRUE" ;
VAL_ 1069 FOMI_ICCM_DTCTriggered 0 "FALSE" 1 "TRUE" ;
VAL_ 1998 FOMI_PCM_DTCTriggered 0 "FALSE" 1 "TRUE" ;
VAL_ 1068 FOMI_TCM_DTCTriggered 0 "FALSE" 1 "TRUE" ;
VAL_ 1999 FOMI_VECM_DTCTriggered 0 "FALSE" 1 "TRUE" ;
VAL_ 2009 FOMI_VICM_DTCTriggered 0 "FALSE" 1 "TRUE" ;
VAL_ 1508 FI_FiltdDispTotFlLvlPct_Inv 0 "FALSE" 1 "TRUE" ;
VAL_ 1508 FI_FiltdDispTotFlLvlTnk2Pct_Inv 0 "FALSE" 1 "TRUE" ;
VAL_ 724 GPSQM_PPS2DAbsPstnErrEst_Inv 0 "FALSE" 1 "TRUE" ;
VAL_ 724 GPSQM_PPS3DAbsPstnErrEst_Inv 0 "FALSE" 1 "TRUE" ;
VAL_ 724 GPSQM_PPSMode_Inv 0 "FALSE" 1 "TRUE" ;
VAL_ 724 GPSQM_PPSMode 0 "GNSS Standalone" 1 "GNSS and SBAS" 2 "GNSS and RTX" 3 "GNSS and DR" 4 "GNSS and SBAS and DR" 5 "GNSS and RTX and DR" 6 "DR ONLY" 7 "GNSS and RTX and DR and MM" ;
VAL_ 724 GPSQM_PPSAbsVelErrEst_Inv 0 "FALSE" 1 "TRUE" ;
VAL_ 724 GPSQM_PPSAbsHdgErrEst_Inv 0 "FALSE" 1 "TRUE" ;
VAL_ 724 GPSQM_PPSPstnDilutnPrcsn_Inv 0 "FALSE" 1 "TRUE" ;
VAL_ 725 GPSC_PPSLat_Inv 0 "FALSE" 1 "TRUE" ;
VAL_ 725 GPSC_PPSLong_Inv 0 "FALSE" 1 "TRUE" ;
VAL_ 726 GPST_PPSCldrDy_Inv 0 "FALSE" 1 "TRUE" ;
VAL_ 726 GPST_PPSCldrYr_Inv 0 "FALSE" 1 "TRUE" ;
VAL_ 726 GPST_PPSTmOfDy_Inv 0 "FALSE" 1 "TRUE" ;
VAL_ 727 GPSV_PPSCalcdSpd_Inv 0 "FALSE" 1 "TRUE" ;
VAL_ 727 GPSV_PPSElvtn_Inv 0 "FALSE" 1 "TRUE" ;
VAL_ 727 GPSV_PPSHdg_Inv 0 "FALSE" 1 "TRUE" ;
VAL_ 1305 CntrStckDispFlrIndOn 0 "FALSE" 1 "TRUE" ;
VAL_ 1305 VirtCtlAuxAlrmSnsrReqAuth 0 "No Action" 1 "On" 2 "Off" ;
VAL_ 1305 HMIGI3P_VirtCtlHdPrkLmpsReqAuth 0 "No Action" 1 "Off" 2 "Auto" 3 "Parking" 4 "On" ;
VAL_ 1305 InfoWndMtnRRReq 0 "No Request" 1 "Move Fully Up" 2 "Move Fully Down" 3 "Vent" ;
VAL_ 1305 InfoWndMtnLRReq 0 "No Request" 1 "Move Fully Up" 2 "Move Fully Down" 3 "Vent" ;
VAL_ 1305 InfoWndMtnRFReq 0 "No Request" 1 "Move Fully Up" 2 "Move Fully Down" 3 "Vent" ;
VAL_ 1305 InfoWndMtnLFReq 0 "No Request" 1 "Move Fully Up" 2 "Move Fully Down" 3 "Vent" ;
VAL_ 1305 VirtCtlVehOnExtModeSwReqd 0 "FALSE" 1 "TRUE" ;
VAL_ 1305 VirtCtlVehEmrgOffSwReqd 0 "FALSE" 1 "TRUE" ;
VAL_ 1305 VirtCtlVehOffSwReq 0 "Not Pressed" 1 "Pressed" 2 "Press and Hold" ;
VAL_ 1305 InfoSnrfPstnReq 0 "No Request" 1 "0%" 2 "10%" 3 "20%" 4 "30%" 5 "40%" 6 "50%" 7 "60%" 8 "70%" 9 "80%" 10 "90%" 11 "100%" ;
VAL_ 1305 InfoWndPstnRRReqActv 0 "FALSE" 1 "TRUE" ;
VAL_ 1315 HMII1P_LnFllwgChInterFltDtdAuth 0 "FALSE" 1 "TRUE" ;
VAL_ 1315 HMII1P_IPCDispStsAuth 0 "Unknown" 1 "Normal" 2 "Fault" ;
VAL_ 1315 HMII1P_ChmSysSOHAuth 0 "Unknown" 1 "Healthy" 2 "Faulted" ;
VAL_ 1315 HMII1P_AutoModeSpdLimCnfrmdAuth 0 "FALSE" 1 "TRUE" ;
VAL_ 1315 HMII1P_ACCSetTypAuth 0 "Manual" 1 "Auto" ;
VAL_ 1315 InfoWndPstnRFReqActv 0 "FALSE" 1 "TRUE" ;
VAL_ 1315 InfoWndPstnLRReqActv 0 "FALSE" 1 "TRUE" ;
VAL_ 1315 InfoWndPstnLFReqActv 0 "FALSE" 1 "TRUE" ;
VAL_ 1447 HVACFCRADSCF_LtChgNext 0 "FALSE" 1 "TRUE" ;
VAL_ 1447 HVACFCRADSCF_RtChgNext 0 "FALSE" 1 "TRUE" ;
VAL_ 1448 HVACFCRADSF_LtSet 0 "NoAction" 1 "Auto" 2 "Floor" 3 "FloorAndVent" 4 "Vent" 5 "VentAndWindshield" 6 "Windshield" 7 "FloorAndWindshield" 8 "FloorAndVentAndWindshield" ;
VAL_ 1448 HVACFCRADSF_RtSet 0 "NoAction" 1 "Auto" 2 "Floor" 3 "FloorAndVent" 4 "Vent" 5 "VentAndWindshield" 6 "Windshield" 7 "FloorAndWindshield" 8 "FloorAndVentAndWindshield" ;
VAL_ 1449 HVACFCRBLCF_ORH1 0 "FALSE" 1 "TRUE" ;
VAL_ 1449 HVACFCRBLCF_CktCorr 0 "Indeterminate" 1 "Pass Criteria Met" 2 "Fail Criteria Met" ;
VAL_ 1449 HVACFCRBLCF_ORL2 0 "FALSE" 1 "TRUE" ;
VAL_ 1449 HVACFCRBLCF_ORL1 0 "FALSE" 1 "TRUE" ;
VAL_ 1449 HVACFCRBLCF_ORH2 0 "FALSE" 1 "TRUE" ;
VAL_ 1451 HVACFCRBLF_LvlActv 0 "FALSE" 1 "TRUE" ;
VAL_ 1452 HVACFCRDP_FrtPwrSetChg_Inv 0 "FALSE" 1 "TRUE" ;
VAL_ 1452 HVACFCRDP_FrtPwrSetChg 0 "FALSE" 1 "TRUE" ;
VAL_ 1452 HVACFCRDP_IntrnlFltSts 0 "Fault1" 1 "Fault2" 2 "Fault3" 3 "Fault4" 4 "Fault5" 5 "Fault6" 6 "Fault7" 7 "Fault8" 8 "Fault9" 9 "Fault10" 10 "Fault11" 11 "Fault12" 12 "Fault13" 13 "Fault14" 14 "Fault15" 15 "Fault16" ;
VAL_ 1452 HVACFCRDP_InitFin 0 "FALSE" 1 "TRUE" ;
VAL_ 1452 HVACFCRDP_HtdFrtWshldSetChgd 0 "FALSE" 1 "TRUE" ;
VAL_ 1452 HVACFCRDP_MaxDefrSetChg 0 "FALSE" 1 "TRUE" ;
VAL_ 1453 HVACFCRRFA_FrshAirSetChg 0 "FALSE" 1 "TRUE" ;
VAL_ 1453 HVACFCRRFA_FrtAutoSetChg 0 "FALSE" 1 "TRUE" ;
VAL_ 1453 HVACFCRRFA_RecircSetChg 0 "FALSE" 1 "TRUE" ;
VAL_ 1454 HVACFCRTLCFL_CktCorr 0 "Indeterminate" 1 "Pass Criteria Met" 2 "Fail Criteria Met" ;
VAL_ 1454 HVACFCRTLCFL_ORL3 0 "FALSE" 1 "TRUE" ;
VAL_ 1454 HVACFCRTLCFL_ORL2 0 "FALSE" 1 "TRUE" ;
VAL_ 1454 HVACFCRTLCFL_ORL1 0 "FALSE" 1 "TRUE" ;
VAL_ 1454 HVACFCRTLCFL_ORH3 0 "FALSE" 1 "TRUE" ;
VAL_ 1454 HVACFCRTLCFL_ORH2 0 "FALSE" 1 "TRUE" ;
VAL_ 1454 HVACFCRTLCFL_ORH1 0 "FALSE" 1 "TRUE" ;
VAL_ 1457 HVACFCRTLCFR_CktCorr 0 "Indeterminate" 1 "Pass Criteria Met" 2 "Fail Criteria Met" ;
VAL_ 1457 HVACFCRTLCFR_ORL3 0 "FALSE" 1 "TRUE" ;
VAL_ 1457 HVACFCRTLCFR_ORL2 0 "FALSE" 1 "TRUE" ;
VAL_ 1457 HVACFCRTLCFR_ORL1 0 "FALSE" 1 "TRUE" ;
VAL_ 1457 HVACFCRTLCFR_ORH3 0 "FALSE" 1 "TRUE" ;
VAL_ 1457 HVACFCRTLCFR_ORH2 0 "FALSE" 1 "TRUE" ;
VAL_ 1457 HVACFCRTLCFR_ORH1 0 "FALSE" 1 "TRUE" ;
VAL_ 1459 HVACFCRTLF_LtLvlActv 0 "FALSE" 1 "TRUE" ;
VAL_ 1459 HVACFCRTLF_RtLvlActv 0 "FALSE" 1 "TRUE" ;
VAL_ 1460 HVACFCRTLCFLI2_ORL4 0 "FALSE" 1 "TRUE" ;
VAL_ 1460 HVACFCRTLCFLI2_ORH4 0 "FALSE" 1 "TRUE" ;
VAL_ 1461 HVACFCRTLCFRI2_ORL4 0 "FALSE" 1 "TRUE" ;
VAL_ 1461 HVACFCRTLCFRI2_ORH4 0 "FALSE" 1 "TRUE" ;
VAL_ 1462 HVACICR1_FrtRrPwrSet 0 "NoAction" 1 "FrontOFF_RearOFF" 2 "FrontON_RearON" 3 "FrontON_RearOFF" 4 "FrontOFF_RearON" ;
VAL_ 1462 HVACICR1_FrtPwrSetChg 0 "FALSE" 1 "TRUE" ;
VAL_ 1462 HVACICR1_FrtAutoSetChg 0 "FALSE" 1 "TRUE" ;
VAL_ 1462 HVACICR1_CompSetChg 0 "FALSE" 1 "TRUE" ;
VAL_ 1462 HVACICR1_CompSet 0 "NoAction" 1 "COMP_OFF" 2 "COMP_ON" 3 "COMP_ECON" ;
VAL_ 1462 HVACICR1_BlwLvlFrtActv 0 "FALSE" 1 "TRUE" ;
VAL_ 1462 HVACICR1_IntrnlFltSts 0 "Fault1" 1 "Fault2" 2 "Fault3" 3 "Fault4" 4 "Fault5" 5 "Fault6" 6 "Fault7" 7 "Fault8" 8 "Fault9" 9 "Fault10" 10 "Fault11" 11 "Fault12" 12 "Fault13" 13 "Fault14" 14 "Fault15" 15 "Fault16" ;
VAL_ 1462 HVACICR1_HtrSetChg 0 "FALSE" 1 "TRUE" ;
VAL_ 1462 HVACICR1_HtrSet 0 "NoAction" 1 "HEAT_OFF" 2 "HEAT_ON" ;
VAL_ 1462 HVACICR1_MaxDefrSetChg 0 "FALSE" 1 "TRUE" ;
VAL_ 1462 HVACICR1_MaxDefrSet 0 "NoAction" 1 "MaxDefrostOff" 2 "MaxDefrostOn" ;
VAL_ 1462 HVACInfoCtlReqHtgACSetChg 0 "FALSE" 1 "TRUE" ;
VAL_ 1463 HVACICR2_AirDstRtChgPrev 0 "FALSE" 1 "TRUE" ;
VAL_ 1463 HVACICR2_AirDstRtChgNext 0 "FALSE" 1 "TRUE" ;
VAL_ 1463 HVACICR2_AirDstLtSet 0 "NoAction" 1 "Auto" 2 "Floor" 3 "FloorAndVent" 4 "Vent" 5 "VentAndWindshield" 6 "Windshield" 7 "FloorAndWindshield" 8 "FloorAndVentAndWindshield" ;
VAL_ 1463 HVACICR2_AirDstLtChgPrev 0 "FALSE" 1 "TRUE" ;
VAL_ 1463 HVACICR2_AirDstLtChgNext 0 "FALSE" 1 "TRUE" ;
VAL_ 1463 HVACICR2_RecircSetChg 0 "FALSE" 1 "TRUE" ;
VAL_ 1463 HVACICR2_RecircSet 0 "NoAction" 1 "FreshAir" 2 "Recirc" ;
VAL_ 1463 HVACICR2_AirDstRtSet 0 "NoAction" 1 "Auto" 2 "Floor" 3 "FloorAndVent" 4 "Vent" 5 "VentAndWindshield" 6 "Windshield" 7 "FloorAndWindshield" 8 "FloorAndVentAndWindshield" ;
VAL_ 1463 HVACICR2_TempLtLvlActv 0 "FALSE" 1 "TRUE" ;
VAL_ 1463 HVACICR2_TempRtLvlActv 0 "FALSE" 1 "TRUE" ;
VAL_ 1885 LclTmYrVal_Inv 0 "FALSE" 1 "TRUE" ;
VAL_ 1885 LclTmMinVal_Inv 0 "FALSE" 1 "TRUE" ;
VAL_ 1885 LclTmDayVal_Inv 0 "FALSE" 1 "TRUE" ;
VAL_ 1885 LclTmSecVal_Inv 0 "FALSE" 1 "TRUE" ;
VAL_ 1885 LclTmHrVal_Inv 0 "FALSE" 1 "TRUE" ;
VAL_ 1885 LclTmMthVal 0 "Unknown" 1 "January" 2 "February" 3 "March" 4 "April" 5 "May" 6 "June" 7 "July" 8 "August" 9 "September" 10 "October" 11 "November" 12 "December" ;
VAL_ 1885 LclTmMthVal_Inv 0 "FALSE" 1 "TRUE" ;
VAL_ 1439 FrtCntrStckFvrtUpSw 0 "Released" 1 "Pressed" ;
VAL_ 1439 FrtCntrStckFvrtDnSw 0 "Released" 1 "Pressed" ;
VAL_ 1439 FrtCntrStckEjectSw 0 "Released" 1 "Pressed" ;
VAL_ 1439 FrtCntrStckDiscAuxSw 0 "Released" 1 "Pressed" ;
VAL_ 1439 FrtCntrStckBndSw 0 "Released" 1 "Pressed" ;
VAL_ 1439 FrtCntrStckBnchBtnID_VirtSw 0 "Released" 1 "Pressed" ;
VAL_ 1439 FrtCntrStckBackSw 0 "Released" 1 "Pressed" ;
VAL_ 1439 FrtCntrStckAllRelSw 0 "Released" 1 "Pressed" ;
VAL_ 1439 FrtCntrStckSw24 0 "Released" 1 "Pressed" ;
VAL_ 1439 FrtCntrStckSw23 0 "Released" 1 "Pressed" ;
VAL_ 1439 FrtCntrStckStrgeUnlckSw 0 "Released" 1 "Pressed" ;
VAL_ 1439 FrtCntrStckPwrSw 0 "Released" 1 "Pressed" ;
VAL_ 1439 FrtCntrStckPrevSw 0 "Released" 1 "Pressed" ;
VAL_ 1439 FrtCntrStckNextSw 0 "Released" 1 "Pressed" ;
VAL_ 1439 FrtCntrStckMenuSw 0 "Released" 1 "Pressed" ;
VAL_ 1439 FrtCntrStckHomeSw 0 "Released" 1 "Pressed" ;
VAL_ 1439 FrtCntrStckSw32 0 "Released" 1 "Pressed" ;
VAL_ 1439 FrtCntrStckSw31 0 "Released" 1 "Pressed" ;
VAL_ 1439 FrtCntrStckSw30 0 "Released" 1 "Pressed" ;
VAL_ 1439 FrtCntrStckSw29 0 "Released" 1 "Pressed" ;
VAL_ 1439 FrtCntrStckSw28 0 "Released" 1 "Pressed" ;
VAL_ 1439 FrtCntrStckSw27 0 "Released" 1 "Pressed" ;
VAL_ 1439 FrtCntrStckSw26 0 "Released" 1 "Pressed" ;
VAL_ 1439 FrtCntrStckSw25 0 "Released" 1 "Pressed" ;
VAL_ 1180 UTCDay_Inv 0 "FALSE" 1 "TRUE" ;
VAL_ 1180 UTCHrs_Inv 0 "FALSE" 1 "TRUE" ;
VAL_ 1180 UTCMth_Inv 0 "FALSE" 1 "TRUE" ;
VAL_ 1180 UTCMth 0 "Unknown" 1 "January" 2 "February" 3 "March" 4 "April" 5 "May" 6 "June" 7 "July" 8 "August" 9 "September" 10 "October" 11 "November" 12 "December" ;
VAL_ 1180 UTCMin_Inv 0 "FALSE" 1 "TRUE" ;
VAL_ 1180 UTCSec_Inv 0 "FALSE" 1 "TRUE" ;
VAL_ 1180 UTCYr_Inv 0 "FALSE" 1 "TRUE" ;
VAL_ 1180 CellNWDateTimeAvl 0 "FALSE" 1 "TRUE" ;
VAL_ 1244 CmpsOctHding 0 "N" 1 "NE" 2 "E" 3 "SE" 4 "S" 5 "SW" 6 "W" 7 "NW" ;
VAL_ 1244 CmpsDecZone 0 "Unknown" 1 "Zone 1" 2 "Zone 2" 3 "Zone 3" 4 "Zone 4" 5 "Zone 5" 6 "Zone 6" 7 "Zone 7" 8 "Zone 8" 9 "Zone 9" 10 "zone 10" 11 "Zone 11" 12 "Zone 12" 13 "Zone 13" 14 "Zone 14" 15 "Zone 15" ;
VAL_ 1244 EmrgRespSysServIndOn 0 "FALSE" 1 "TRUE" ;
VAL_ 1244 CmpsZnNvrSet 0 "False" 1 "True" ;
VAL_ 1244 CmpsSatrtd 0 "False" 1 "True" ;
VAL_ 1244 CmpsOctHdingDataSrc 0 "Stored Value" 1 "Calculated Value" ;
VAL_ 1244 CmpsModManCalInPrc 0 "False" 1 "True" ;
VAL_ 1244 CmpsModFltPrs 0 "False" 1 "True" ;
VAL_ 1440 FrtCntrStckHptcFdbkStat 0 "FEEDBACK_OFF" 1 "TAP" 2 "LONG_PRESS" 3 "PRESS_&_HOLD_SCROLL" 4 "PRESS_&_HOLD_END" 5 "RESERVED_05" 6 "RESERVED_06" 7 "RESERVED_07" 8 "RESERVED_08" 9 "RESERVED_09" 10 "RESERVED_10" 11 "RESERVED_11" 12 "RESERVED_12" 13 "RESERVED_13" 14 "RESERVED_14" 15 "RESERVED_15" ;
VAL_ 1440 FrtCntrStckTag2Sw 0 "Released" 1 "Pressed" ;
VAL_ 1440 FrtCntrStckTag1Sw 0 "Released" 1 "Pressed" ;
VAL_ 1440 FrtCntrStckPrxmtyStat 0 "FAR" 1 "NEAR" 2 "TOUCH" 3 "PRESS" 4 "PROX_STAT4" 5 "PROX_STAT5" 6 "PROX_STAT6" 7 "PROX_STAT7" ;
VAL_ 1440 FrtCntrStckPrxmtyGstr 0 "NO_ACTION" 1 "PROX_GESTURE1" 2 "PROX_GESTURE2" 3 "PROX_GESTURE3" 4 "PROX_GESTURE4" 5 "PROX_GESTURE5" 6 "PROX_GESTURE6" 7 "PROX_GESTURE7" ;
VAL_ 1440 FrtCntrStckVolUpSw 0 "Released" 1 "Pressed" ;
VAL_ 1440 FrtCntrStckVolDnSw 0 "Released" 1 "Pressed" ;
VAL_ 1440 FrtCntrStckToneSw 0 "Released" 1 "Pressed" ;
VAL_ 1440 FrtCntrStckTag5Sw 0 "Released" 1 "Pressed" ;
VAL_ 1440 FrtCntrStckTag4Sw 0 "Released" 1 "Pressed" ;
VAL_ 1440 FrtCntrStckTag3Sw 0 "Released" 1 "Pressed" ;
VAL_ 1503 SBZAlrtCstAvlFlg7 0 "FALSE" 1 "TRUE" ;
VAL_ 1503 SBZAlrtCstAvlFlg6 0 "FALSE" 1 "TRUE" ;
VAL_ 1503 SBZAlrtCstAvlFlg5 0 "FALSE" 1 "TRUE" ;
VAL_ 1503 SBZAlrtCstAvlFlg4 0 "FALSE" 1 "TRUE" ;
VAL_ 1503 SBZAlrtCstAvlFlg3 0 "FALSE" 1 "TRUE" ;
VAL_ 1503 SBZAlrtCstAvlFlg2 0 "FALSE" 1 "TRUE" ;
VAL_ 1503 SBZAlrtCstAvlFlg1 0 "FALSE" 1 "TRUE" ;
VAL_ 1503 LnChgAlrtLmtdTrlrIndOn 0 "FALSE" 1 "TRUE" ;
VAL_ 1503 ServSdDtcSysIndOn 0 "FALSE" 1 "TRUE" ;
VAL_ 1503 SdDtcTempUnvIndOn 0 "FALSE" 1 "TRUE" ;
VAL_ 1503 SBZAlrtOffIndOn 0 "FALSE" 1 "TRUE" ;
VAL_ 1503 SBZAlrtCstStAvl 0 "FALSE" 1 "TRUE" ;
VAL_ 1509 DrvrAlrtTypCstStAvl 0 "FALSE" 1 "TRUE" ;
VAL_ 1509 DrvrAlrtTypCstAvlFlg7 0 "FALSE" 1 "TRUE" ;
VAL_ 1509 DrvrAlrtTypCstAvlFlg6 0 "FALSE" 1 "TRUE" ;
VAL_ 1509 DrvrAlrtTypCstAvlFlg5 0 "FALSE" 1 "TRUE" ;
VAL_ 1509 DrvrAlrtTypCstAvlFlg4 0 "FALSE" 1 "TRUE" ;
VAL_ 1509 DrvrAlrtTypCstAvlFlg3 0 "FALSE" 1 "TRUE" ;
VAL_ 1509 DrvrAlrtTypCstAvlFlg2 0 "FALSE" 1 "TRUE" ;
VAL_ 1509 DrvrAlrtTypCstAvlFlg1 0 "FALSE" 1 "TRUE" ;
VAL_ 1509 HptcStFldIndOn 0 "FALSE" 1 "TRUE" ;
VAL_ 702 StrgWhlTrqIntegSts 0 "Unknown" 1 "Redundant ASIL D" 2 "Non Redundant ASIL D" 3 "Failed" ;
VAL_ 702 StrgWhlHndsOffDtnStat 0 "Hands On" 1 "Hands Off" 2 "Unknown" ;
